VERSION ""

NS_ :

BS_:

BU_: ETH

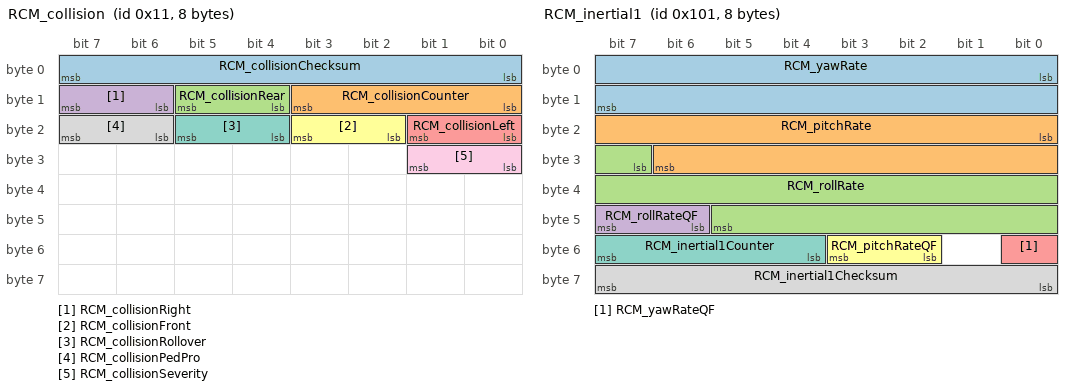
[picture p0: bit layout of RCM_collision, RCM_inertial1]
BO_ 17 RCM_collision: 8 Vector__XXX
 SG_ RCM_collisionChecksum : 0|8@1+ (1,0) [0|0] "" Vector__XXX
 SG_ RCM_collisionCounter : 8|4@1+ (1,0) [0|0] "" Vector__XXX
 SG_ RCM_collisionRear : 12|2@1+ (1,0) [0|0] "" Vector__XXX
 SG_ RCM_collisionRight : 14|2@1+ (1,0) [0|0] "" Vector__XXX
 SG_ RCM_collisionLeft : 16|2@1+ (1,0) [0|0] "" Vector__XXX
 SG_ RCM_collisionFront : 18|2@1+ (1,0) [0|0] "" Vector__XXX
 SG_ RCM_collisionRollover : 20|2@1+ (1,0) [0|0] "" Vector__XXX
 SG_ RCM_collisionPedPro : 22|2@1+ (1,0) [0|0] "" Vector__XXX
 SG_ RCM_collisionSeverity : 24|2@1+ (1,0) [0|0] "" Vector__XXX

BO_ 49 EPAS3P_status: 8 Vector__XXX
 SG_ EPAS3P_statusCrc : 0|8@1+ (1,0) [0|0] "" Vector__XXX
 SG_ EPAS3P_statusCounter : 8|4@1+ (1,0) [0|0] "" Vector__XXX
 SG_ EPAS3P_state : 12|4@1+ (1,0) [0|0] "" Vector__XXX
 SG_ EPAS3P_powerMode : 16|3@1+ (1,0) [0|0] "" Vector__XXX
 SG_ EPAS3P_role : 19|2@1+ (1,0) [0|0] "" Vector__XXX

BO_ 50 RCM_peripheralSensors1: 8 Vector__XXX
 SG_ RCM_leftFrontDoorPressure : 0|10@1- (0.48828125,0) [0|0] "" Vector__XXX
 SG_ RCM_rightFrontDoorPressure : 10|10@1- (0.48828125,0) [0|0] "" Vector__XXX
 SG_ RCM_leftRearDoorPressure : 20|10@1- (0.48828125,0) [0|0] "" Vector__XXX
 SG_ RCM_rightRearDoorPressure : 30|10@1- (0.48828125,0) [0|0] "" Vector__XXX
 SG_ RCM_peripheralSensors1Counter : 52|4@1+ (1,0) [0|0] "" Vector__XXX
 SG_ RCM_peripheralSensors1Checksum : 56|8@1+ (1,0) [0|0] "" Vector__XXX

BO_ 81 EPAS3S_status: 8 Vector__XXX
 SG_ EPAS3S_statusCrc : 0|8@1+ (1,0) [0|0] "" Vector__XXX
 SG_ EPAS3S_statusCounter : 8|4@1+ (1,0) [0|0] "" Vector__XXX
 SG_ EPAS3S_state : 12|4@1+ (1,0) [0|0] "" Vector__XXX
 SG_ EPAS3S_powerMode : 16|3@1+ (1,0) [0|0] "" Vector__XXX
 SG_ EPAS3S_role : 19|2@1+ (1,0) [0|0] "" Vector__XXX

BO_ 129 RCM_impactSummary: 8 Vector__XXX
 SG_ RCM_maxDvLateralEvent1 : 0|8@1+ (1,-127) [0|0] "" Vector__XXX
 SG_ RCM_maxDvLongitudinalEvent1 : 8|8@1+ (1,-127) [0|0] "" Vector__XXX
 SG_ RCM_impactDirectionEvent1 : 16|4@1+ (1,0) [0|0] "" Vector__XXX

BO_ 257 RCM_inertial1: 8 Vector__XXX
 SG_ RCM_yawRate : 0|16@1- (0.0001,0) [0|0] "" Vector__XXX
 SG_ RCM_pitchRate : 16|15@1- (0.00025,0) [0|0] "" Vector__XXX
 SG_ RCM_rollRate : 31|15@1- (0.00025,0) [0|0] "" Vector__XXX
 SG_ RCM_rollRateQF : 46|2@1+ (1,0) [0|0] "" Vector__XXX
 SG_ RCM_yawRateQF : 48|1@1+ (1,0) [0|0] "" Vector__XXX
 SG_ RCM_pitchRateQF : 50|2@1+ (1,0) [0|0] "" Vector__XXX
 SG_ RCM_inertial1Counter : 52|4@1+ (1,0) [0|0] "" Vector__XXX
 SG_ RCM_inertial1Checksum : 56|8@1+ (1,0) [0|0] "" Vector__XXX

BO_ 258 VCLEFT_doorStatus: 8 Vector__XXX
 SG_ VCLEFT_doorClosureStatusFront : 0|4@1+ (1,0) [0|0] "" Vector__XXX
 SG_ VCLEFT_doorClosureStatusRear : 4|4@1+ (1,0) [0|0] "" Vector__XXX
 SG_ VCLEFT_frontLatchSwitch : 8|1@1+ (1,0) [0|0] "" Vector__XXX
 SG_ VCLEFT_rearLatchSwitch : 9|1@1+ (1,0) [0|0] "" Vector__XXX
 SG_ VCLEFT_frontHandlePulled : 10|1@1+ (1,0) [0|0] "" Vector__XXX
 SG_ VCLEFT_rearHandlePulled : 11|1@1+ (1,0) [0|0] "" Vector__XXX
 SG_ VCLEFT_frontRelActuatorSwitch : 12|1@1+ (1,0) [0|0] "" Vector__XXX
 SG_ VCLEFT_rearRelActuatorSwitch : 13|1@1+ (1,0) [0|0] "" Vector__XXX
 SG_ VCLEFT_frontLatchStatus : 14|4@1+ (1,0) [0|0] "" Vector__XXX
 SG_ VCLEFT_rearLatchStatus : 18|4@1+ (1,0) [0|0] "" Vector__XXX
 SG_ VCLEFT_lastDoorReqSourceFront : 22|3@1+ (1,0) [0|0] "" Vector__XXX
 SG_ VCLEFT_lastDoorReqSourceRear : 25|3@1+ (1,0) [0|0] "" Vector__XXX
 SG_ VCLEFT_frontIntSwitchFaulted : 28|1@1+ (1,0) [0|0] "" Vector__XXX
 SG_ VCLEFT_rearIntSwitchFaulted : 29|1@1+ (1,0) [0|0] "" Vector__XXX
 SG_ VCLEFT_frontIntSwitchPressed : 31|1@1+ (1,0) [0|0] "" Vector__XXX
 SG_ VCLEFT_rearIntSwitchPressed : 32|1@1+ (1,0) [0|0] "" Vector__XXX
 SG_ VCLEFT_mirrorTiltXPosition : 33|8@1+ (0.02,0) [0|0] "" Vector__XXX
 SG_ VCLEFT_mirrorTiltYPosition : 41|8@1+ (0.02,0) [0|0] "" Vector__XXX
 SG_ VCLEFT_mirrorState : 49|3@1+ (1,0) [0|0] "" Vector__XXX
 SG_ VCLEFT_mirrorFoldState : 52|3@1+ (1,0) [0|0] "" Vector__XXX
 SG_ VCLEFT_mirrorRecallState : 55|3@1+ (1,0) [0|0] "" Vector__XXX
 SG_ VCLEFT_mirrorHeatState : 58|3@1+ (1,0) [0|0] "" Vector__XXX
 SG_ VCLEFT_rearHandlePulledPersist : 61|1@1+ (1,0) [0|0] "" Vector__XXX
 SG_ VCLEFT_frontHandlePulledPersist : 62|1@1+ (1,0) [0|0] "" Vector__XXX
 SG_ VCLEFT_mirrorDipped : 63|1@1+ (1,0) [0|0] "" Vector__XXX

BO_ 259 VCRIGHT_doorStatus: 8 Vector__XXX
 SG_ VCRIGHT_doorClosureStatusFront : 0|4@1+ (1,0) [0|0] "" Vector__XXX
 SG_ VCRIGHT_doorClosureStatusRear : 4|4@1+ (1,0) [0|0] "" Vector__XXX
 SG_ VCRIGHT_frontLatchSwitch : 8|1@1+ (1,0) [0|0] "" Vector__XXX
 SG_ VCRIGHT_rearLatchSwitch : 9|1@1+ (1,0) [0|0] "" Vector__XXX
 SG_ VCRIGHT_frontHandlePulled : 10|1@1+ (1,0) [0|0] "" Vector__XXX
 SG_ VCRIGHT_rearHandlePulled : 11|1@1+ (1,0) [0|0] "" Vector__XXX
 SG_ VCRIGHT_frontRelActuatorSwitch : 12|1@1+ (1,0) [0|0] "" Vector__XXX
 SG_ VCRIGHT_rearRelActuatorSwitch : 13|1@1+ (1,0) [0|0] "" Vector__XXX
 SG_ VCRIGHT_frontLatchStatus : 14|4@1+ (1,0) [0|0] "" Vector__XXX
 SG_ VCRIGHT_rearLatchStatus : 18|4@1+ (1,0) [0|0] "" Vector__XXX
 SG_ VCRIGHT_lastDoorReqSourceFront : 22|3@1+ (1,0) [0|0] "" Vector__XXX
 SG_ VCRIGHT_lastDoorReqSourceRear : 25|3@1+ (1,0) [0|0] "" Vector__XXX
 SG_ VCRIGHT_frontIntSwitchFaulted : 28|1@1+ (1,0) [0|0] "" Vector__XXX
 SG_ VCRIGHT_rearIntSwitchFaulted : 29|1@1+ (1,0) [0|0] "" Vector__XXX
 SG_ VCRIGHT_frontHandlePulledPersist : 30|1@1+ (1,0) [0|0] "" Vector__XXX
 SG_ VCRIGHT_frontIntSwitchPressed : 31|1@1+ (1,0) [0|0] "" Vector__XXX
 SG_ VCRIGHT_rearIntSwitchPressed : 32|1@1+ (1,0) [0|0] "" Vector__XXX
 SG_ VCRIGHT_mirrorTiltXPosition : 33|8@1+ (0.02,0) [0|0] "" Vector__XXX
 SG_ VCRIGHT_mirrorTiltYPosition : 41|8@1+ (0.02,0) [0|0] "" Vector__XXX
 SG_ VCRIGHT_mirrorState : 49|3@1+ (1,0) [0|0] "" Vector__XXX
 SG_ VCRIGHT_mirrorFoldState : 52|3@1+ (1,0) [0|0] "" Vector__XXX
 SG_ VCRIGHT_mirrorDipped : 55|1@1+ (1,0) [0|0] "" Vector__XXX
 SG_ VCRIGHT_trunkLatchStatus : 56|4@1+ (1,0) [0|0] "" Vector__XXX
 SG_ VCRIGHT_mirrorRecallState : 60|3@1+ (1,0) [0|0] "" Vector__XXX
 SG_ VCRIGHT_rearHandlePulledPersist : 63|1@1+ (1,0) [0|0] "" Vector__XXX

BO_ 260 VCFRONT_partyDebug: 8 Vector__XXX
 SG_ VCFRONT_vcleftHighPower : 0|1@1+ (1,0) [0|0] "" Vector__XXX
 SG_ VCFRONT_vcrightHighPower : 1|1@1+ (1,0) [0|0] "" Vector__XXX
 SG_ VCFRONT_uiHighPower : 2|1@1+ (1,0) [0|0] "" Vector__XXX
 SG_ VCFRONT_5VAStable : 3|1@1+ (1,0) [0|0] "" Vector__XXX
 SG_ VCFRONT_5VBStable : 4|1@1+ (1,0) [0|0] "" Vector__XXX
 SG_ VCFRONT_12VAStable : 5|1@1+ (1,0) [0|0] "" Vector__XXX
 SG_ VCFRONT_12VBStable : 6|1@1+ (1,0) [0|0] "" Vector__XXX
 SG_ VCFRONT_railA : 7|1@1+ (1,0) [0|0] "" Vector__XXX
 SG_ VCFRONT_railB : 8|1@1+ (1,0) [0|0] "" Vector__XXX
 SG_ VCFRONT_chargePumpStable : 9|1@1+ (1,0) [0|0] "" Vector__XXX
 SG_ VCFRONT_vehicleSM : 10|5@1+ (1,0) [0|0] "" Vector__XXX
 SG_ VCFRONT_revBattFault : 15|1@1+ (1,0) [0|0] "" Vector__XXX
 SG_ VCFRONT_battSM : 16|4@1+ (1,0) [0|0] "" Vector__XXX
 SG_ VCFRONT_U13Init : 20|1@1+ (1,0) [0|0] "" Vector__XXX
 SG_ VCFRONT_U16Init : 21|1@1+ (1,0) [0|0] "" Vector__XXX
 SG_ VCFRONT_anyVehLoadShedActiveDBG : 22|1@1+ (1,0) [0|0] "" Vector__XXX
 SG_ VCFRONT_battVoltage : 24|12@1+ (0.005443676098,0) [0|0] "" Vector__XXX
 SG_ VCFRONT_battCurrent : 40|16@1- (0.005,0) [0|0] "" Vector__XXX

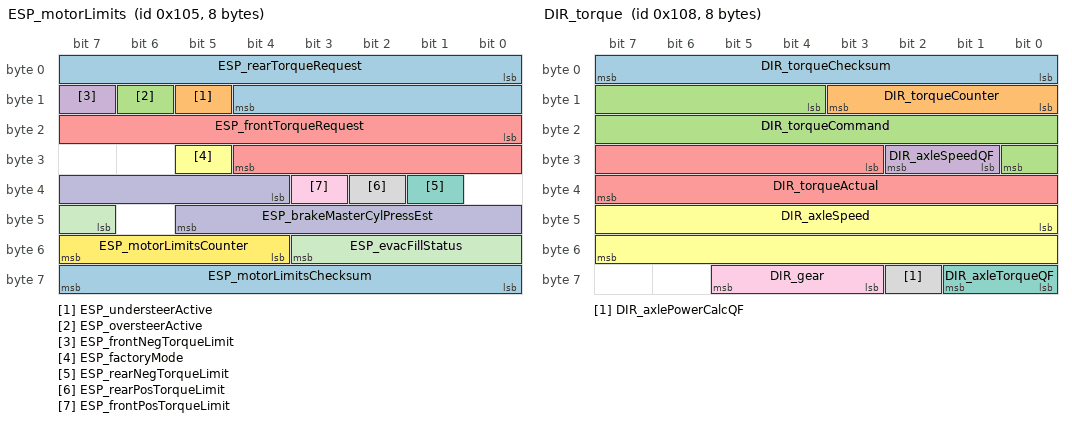
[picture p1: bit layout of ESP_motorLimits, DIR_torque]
BO_ 261 ESP_motorLimits: 8 Vector__XXX
 SG_ ESP_rearTorqueRequest : 0|13@1- (2,0) [0|0] "" Vector__XXX
 SG_ ESP_understeerActive : 13|1@1+ (1,0) [0|0] "" Vector__XXX
 SG_ ESP_oversteerActive : 14|1@1+ (1,0) [0|0] "" Vector__XXX
 SG_ ESP_frontNegTorqueLimit : 15|1@1+ (1,0) [0|0] "" Vector__XXX
 SG_ ESP_frontTorqueRequest : 16|13@1- (2,0) [0|0] "" Vector__XXX
 SG_ ESP_factoryMode : 29|1@1+ (1,0) [0|0] "" Vector__XXX
 SG_ ESP_rearNegTorqueLimit : 33|1@1+ (1,0) [0|0] "" Vector__XXX
 SG_ ESP_rearPosTorqueLimit : 34|1@1+ (1,0) [0|0] "" Vector__XXX
 SG_ ESP_frontPosTorqueLimit : 35|1@1+ (1,0) [0|0] "" Vector__XXX
 SG_ ESP_brakeMasterCylPressEst : 36|10@1+ (0.3,-30) [0|0] "" Vector__XXX
 SG_ ESP_evacFillStatus : 47|5@1+ (1,0) [0|0] "" Vector__XXX
 SG_ ESP_motorLimitsCounter : 52|4@1+ (1,0) [0|0] "" Vector__XXX
 SG_ ESP_motorLimitsChecksum : 56|8@1+ (1,0) [0|0] "" Vector__XXX

BO_ 264 DIR_torque: 8 Vector__XXX
 SG_ DIR_torqueChecksum : 0|8@1+ (1,0) [0|0] "" Vector__XXX
 SG_ DIR_torqueCounter : 8|4@1+ (1,0) [0|0] "" Vector__XXX
 SG_ DIR_torqueCommand : 12|13@1- (2,0) [0|0] "" Vector__XXX
 SG_ DIR_axleSpeedQF : 25|2@1+ (1,0) [0|0] "" Vector__XXX
 SG_ DIR_torqueActual : 27|13@1- (2,0) [0|0] "" Vector__XXX
 SG_ DIR_axleSpeed : 40|16@1- (0.1,0) [0|0] "" Vector__XXX
 SG_ DIR_axleTorqueQF : 56|2@1+ (1,0) [0|0] "" Vector__XXX
 SG_ DIR_axlePowerCalcQF : 58|1@1+ (1,0) [0|0] "" Vector__XXX
 SG_ DIR_gear : 59|3@1+ (1,0) [0|0] "" Vector__XXX

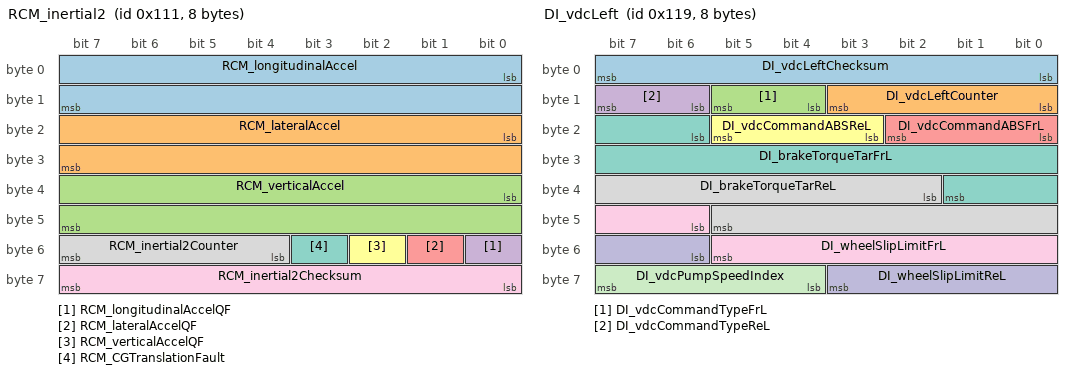
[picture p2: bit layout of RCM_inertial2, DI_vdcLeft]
BO_ 273 RCM_inertial2: 8 Vector__XXX
 SG_ RCM_longitudinalAccel : 0|16@1- (0.00125,0) [0|0] "" Vector__XXX
 SG_ RCM_lateralAccel : 16|16@1- (0.00125,0) [0|0] "" Vector__XXX
 SG_ RCM_verticalAccel : 32|16@1- (0.00125,0) [0|0] "" Vector__XXX
 SG_ RCM_longitudinalAccelQF : 48|1@1+ (1,0) [0|0] "" Vector__XXX
 SG_ RCM_lateralAccelQF : 49|1@1+ (1,0) [0|0] "" Vector__XXX
 SG_ RCM_verticalAccelQF : 50|1@1+ (1,0) [0|0] "" Vector__XXX
 SG_ RCM_CGTranslationFault : 51|1@1+ (1,0) [0|0] "" Vector__XXX
 SG_ RCM_inertial2Counter : 52|4@1+ (1,0) [0|0] "" Vector__XXX
 SG_ RCM_inertial2Checksum : 56|8@1+ (1,0) [0|0] "" Vector__XXX

BO_ 280 DI_systemStatus: 8 Vector__XXX
 SG_ DI_systemStatusChecksum : 0|8@1+ (1,0) [0|0] "" Vector__XXX
 SG_ DI_systemStatusCounter : 8|4@1+ (1,0) [0|0] "" Vector__XXX
 SG_ DI_immobilizerState : 13|3@1+ (1,0) [0|0] "" Vector__XXX
 SG_ DI_systemState : 16|3@1+ (1,0) [0|0] "" Vector__XXX
 SG_ DI_brakePedalState : 19|2@1+ (1,0) [0|0] "" Vector__XXX
 SG_ DI_gear : 21|3@1+ (1,0) [0|0] "" Vector__XXX
 SG_ DI_driveBlocked : 24|3@1+ (1,0) [0|0] "" Vector__XXX
 SG_ DI_hvilSystemStatus : 27|2@1+ (1,0) [0|0] "" Vector__XXX
 SG_ DI_accelPedalPos : 32|8@1+ (0.4,0) [0|0] "" Vector__XXX
 SG_ DI_tractionControlMode : 40|3@1+ (1,0) [0|0] "" Vector__XXX
 SG_ DI_dynoModeAvailable : 43|1@1+ (1,0) [0|0] "" Vector__XXX
 SG_ DI_epbRequest : 44|2@1+ (1,0) [0|0] "" Vector__XXX
 SG_ DI_eepDeliveryBitStatus : 46|1@1+ (1,0) [0|0] "" Vector__XXX
 SG_ DI_keepDrivePowerStateRequest : 47|1@1+ (1,0) [0|0] "" Vector__XXX
 SG_ DI_trackModeState : 48|2@1+ (1,0) [0|0] "" Vector__XXX
 SG_ DI_manualDrivingProhibited : 50|1@1+ (1,0) [0|0] "" Vector__XXX
 SG_ DI_regenLight : 51|1@1+ (1,0) [0|0] "" Vector__XXX
 SG_ DI_vehicleAcceleration : 52|12@1- (0.01,0) [0|0] "" Vector__XXX

BO_ 281 DI_vdcLeft: 8 Vector__XXX
 SG_ DI_vdcLeftChecksum : 0|8@1+ (1,0) [0|0] "" Vector__XXX
 SG_ DI_vdcLeftCounter : 8|4@1+ (1,0) [0|0] "" Vector__XXX
 SG_ DI_vdcCommandTypeFrL : 12|2@1+ (1,0) [0|0] "" Vector__XXX
 SG_ DI_vdcCommandTypeReL : 14|2@1+ (1,0) [0|0] "" Vector__XXX
 SG_ DI_vdcCommandABSFrL : 16|3@1+ (1,0) [0|0] "" Vector__XXX
 SG_ DI_vdcCommandABSReL : 19|3@1+ (1,0) [0|0] "" Vector__XXX
 SG_ DI_brakeTorqueTarFrL : 22|12@1+ (3,-3) [0|0] "" Vector__XXX
 SG_ DI_brakeTorqueTarReL : 34|12@1+ (3,-3) [0|0] "" Vector__XXX
 SG_ DI_wheelSlipLimitFrL : 46|8@1+ (0.004,-0.004) [0|0] "" Vector__XXX
 SG_ DI_wheelSlipLimitReL : 54|6@1+ (0.004,-0.004) [0|0] "" Vector__XXX
 SG_ DI_vdcPumpSpeedIndex : 60|4@1+ (1,0) [0|0] "" Vector__XXX

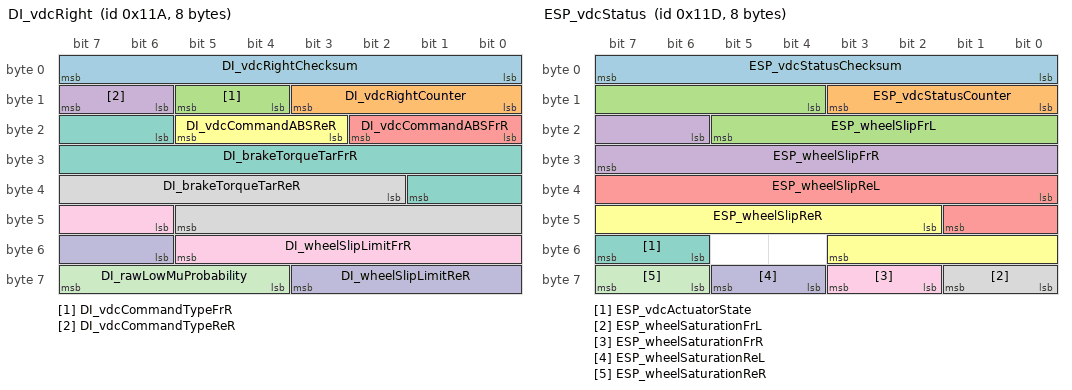
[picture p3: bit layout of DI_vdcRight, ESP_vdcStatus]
BO_ 282 DI_vdcRight: 8 Vector__XXX
 SG_ DI_vdcRightChecksum : 0|8@1+ (1,0) [0|0] "" Vector__XXX
 SG_ DI_vdcRightCounter : 8|4@1+ (1,0) [0|0] "" Vector__XXX
 SG_ DI_vdcCommandTypeFrR : 12|2@1+ (1,0) [0|0] "" Vector__XXX
 SG_ DI_vdcCommandTypeReR : 14|2@1+ (1,0) [0|0] "" Vector__XXX
 SG_ DI_vdcCommandABSFrR : 16|3@1+ (1,0) [0|0] "" Vector__XXX
 SG_ DI_vdcCommandABSReR : 19|3@1+ (1,0) [0|0] "" Vector__XXX
 SG_ DI_brakeTorqueTarFrR : 22|12@1+ (3,-3) [0|0] "" Vector__XXX
 SG_ DI_brakeTorqueTarReR : 34|12@1+ (3,-3) [0|0] "" Vector__XXX
 SG_ DI_wheelSlipLimitFrR : 46|8@1+ (0.004,-0.004) [0|0] "" Vector__XXX
 SG_ DI_wheelSlipLimitReR : 54|6@1+ (0.004,-0.004) [0|0] "" Vector__XXX
 SG_ DI_rawLowMuProbability : 60|4@1+ (0.06666666666666667,0) [0|0] "" Vector__XXX

BO_ 283 DAS_matrixBendAngleRequest: 8 Vector__XXX
 SG_ DAS_adaptiveBendAngle : 0|8@1- (0.1,0) [0|0] "" Vector__XXX

BO_ 285 ESP_vdcStatus: 8 Vector__XXX
 SG_ ESP_vdcStatusChecksum : 0|8@1+ (1,0) [0|0] "" Vector__XXX
 SG_ ESP_vdcStatusCounter : 8|4@1+ (1,0) [0|0] "" Vector__XXX
 SG_ ESP_wheelSlipFrL : 12|10@1+ (0.001,0) [0|0] "" Vector__XXX
 SG_ ESP_wheelSlipFrR : 22|10@1+ (0.001,0) [0|0] "" Vector__XXX
 SG_ ESP_wheelSlipReL : 32|10@1+ (0.001,0) [0|0] "" Vector__XXX
 SG_ ESP_wheelSlipReR : 42|10@1+ (0.001,0) [0|0] "" Vector__XXX
 SG_ ESP_vdcActuatorState : 54|2@1+ (1,0) [0|0] "" Vector__XXX
 SG_ ESP_wheelSaturationFrL : 56|2@1+ (1,0) [0|0] "" Vector__XXX
 SG_ ESP_wheelSaturationFrR : 58|2@1+ (1,0) [0|0] "" Vector__XXX
 SG_ ESP_wheelSaturationReL : 60|2@1+ (1,0) [0|0] "" Vector__XXX
 SG_ ESP_wheelSaturationReR : 62|2@1+ (1,0) [0|0] "" Vector__XXX

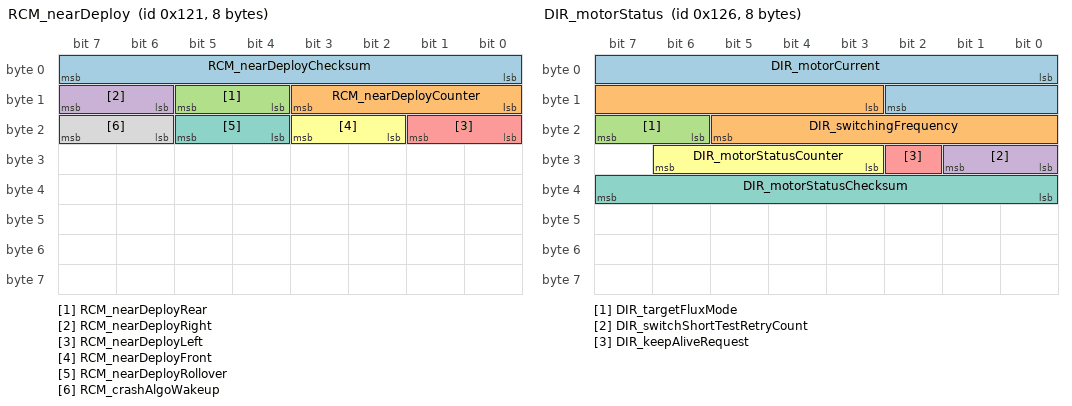
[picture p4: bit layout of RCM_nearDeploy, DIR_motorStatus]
BO_ 289 RCM_nearDeploy: 8 Vector__XXX
 SG_ RCM_nearDeployChecksum : 0|8@1+ (1,0) [0|0] "" Vector__XXX
 SG_ RCM_nearDeployCounter : 8|4@1+ (1,0) [0|0] "" Vector__XXX
 SG_ RCM_nearDeployRear : 12|2@1+ (1,0) [0|0] "" Vector__XXX
 SG_ RCM_nearDeployRight : 14|2@1+ (1,0) [0|0] "" Vector__XXX
 SG_ RCM_nearDeployLeft : 16|2@1+ (1,0) [0|0] "" Vector__XXX
 SG_ RCM_nearDeployFront : 18|2@1+ (1,0) [0|0] "" Vector__XXX
 SG_ RCM_nearDeployRollover : 20|2@1+ (1,0) [0|0] "" Vector__XXX
 SG_ RCM_crashAlgoWakeup : 22|2@1+ (1,0) [0|0] "" Vector__XXX

BO_ 294 DIR_motorStatus: 8 Vector__XXX
 SG_ DIR_motorCurrent : 0|11@1+ (1,0) [0|0] "" Vector__XXX
 SG_ DIR_switchingFrequency : 11|11@1+ (0.01,0) [0|0] "" Vector__XXX
 SG_ DIR_targetFluxMode : 22|2@1+ (1,0) [0|0] "" Vector__XXX
 SG_ DIR_switchShortTestRetryCount : 24|2@1+ (1,0) [0|0] "" Vector__XXX
 SG_ DIR_keepAliveRequest : 26|1@1+ (1,0) [0|0] "" Vector__XXX
 SG_ DIR_motorStatusCounter : 27|4@1+ (1,0) [0|0] "" Vector__XXX
 SG_ DIR_motorStatusChecksum : 32|8@1+ (1,0) [0|0] "" Vector__XXX

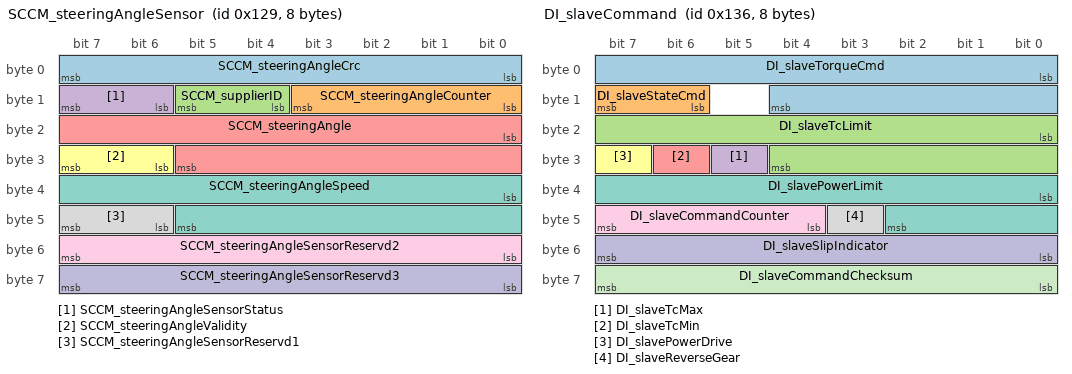
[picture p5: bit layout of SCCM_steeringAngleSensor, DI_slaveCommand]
BO_ 297 SCCM_steeringAngleSensor: 8 Vector__XXX
 SG_ SCCM_steeringAngleCrc : 0|8@1+ (1,0) [0|0] "" Vector__XXX
 SG_ SCCM_steeringAngleCounter : 8|4@1+ (1,0) [0|0] "" Vector__XXX
 SG_ SCCM_supplierID : 12|2@1+ (1,0) [0|0] "" Vector__XXX
 SG_ SCCM_steeringAngleSensorStatus : 14|2@1+ (1,0) [0|0] "" Vector__XXX
 SG_ SCCM_steeringAngle : 16|14@1+ (0.1,-819.2) [0|0] "" Vector__XXX
 SG_ SCCM_steeringAngleValidity : 30|2@1+ (1,0) [0|0] "" Vector__XXX
 SG_ SCCM_steeringAngleSpeed : 32|14@1+ (0.5,-4096) [0|0] "" Vector__XXX
 SG_ SCCM_steeringAngleSensorReservd1 : 46|2@1+ (1,0) [0|0] "" Vector__XXX
 SG_ SCCM_steeringAngleSensorReservd2 : 48|8@1+ (1,0) [0|0] "" Vector__XXX
 SG_ SCCM_steeringAngleSensorReservd3 : 56|8@1+ (1,0) [0|0] "" Vector__XXX

BO_ 310 DI_slaveCommand: 8 Vector__XXX
 SG_ DI_slaveTorqueCmd : 0|13@1- (2,0) [0|0] "" Vector__XXX
 SG_ DI_slaveStateCmd : 14|2@1+ (1,0) [0|0] "" Vector__XXX
 SG_ DI_slaveTcLimit : 16|13@1- (2,0) [0|0] "" Vector__XXX
 SG_ DI_slaveTcMax : 29|1@1+ (1,0) [0|0] "" Vector__XXX
 SG_ DI_slaveTcMin : 30|1@1+ (1,0) [0|0] "" Vector__XXX
 SG_ DI_slavePowerDrive : 31|1@1+ (1,0) [0|0] "" Vector__XXX
 SG_ DI_slavePowerLimit : 32|11@1+ (0.25,0) [0|0] "" Vector__XXX
 SG_ DI_slaveReverseGear : 43|1@1+ (1,0) [0|0] "" Vector__XXX
 SG_ DI_slaveCommandCounter : 44|4@1+ (1,0) [0|0] "" Vector__XXX
 SG_ DI_slaveSlipIndicator : 48|8@1+ (1,0) [0|0] "" Vector__XXX
 SG_ DI_slaveCommandChecksum : 56|8@1+ (1,0) [0|0] "" Vector__XXX

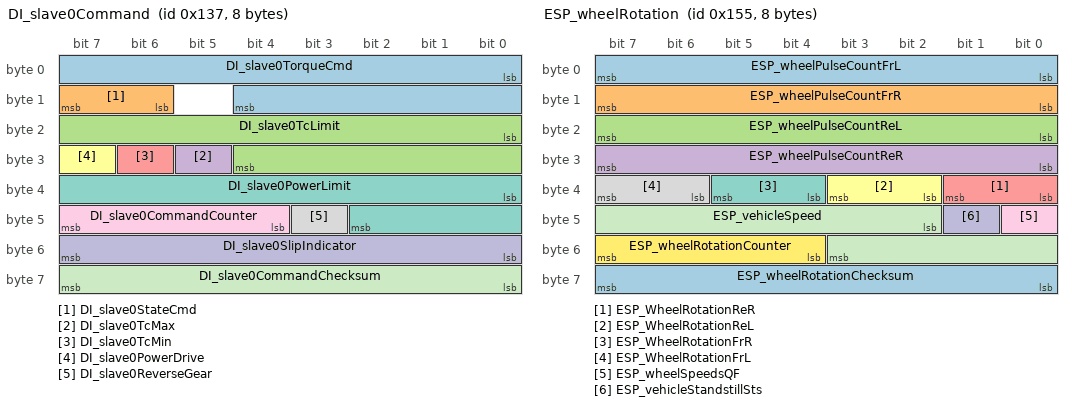
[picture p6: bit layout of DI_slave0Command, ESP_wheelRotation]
BO_ 311 DI_slave0Command: 8 Vector__XXX
 SG_ DI_slave0TorqueCmd : 0|13@1- (2,0) [0|0] "" Vector__XXX
 SG_ DI_slave0StateCmd : 14|2@1+ (1,0) [0|0] "" Vector__XXX
 SG_ DI_slave0TcLimit : 16|13@1- (2,0) [0|0] "" Vector__XXX
 SG_ DI_slave0TcMax : 29|1@1+ (1,0) [0|0] "" Vector__XXX
 SG_ DI_slave0TcMin : 30|1@1+ (1,0) [0|0] "" Vector__XXX
 SG_ DI_slave0PowerDrive : 31|1@1+ (1,0) [0|0] "" Vector__XXX
 SG_ DI_slave0PowerLimit : 32|11@1+ (0.25,0) [0|0] "" Vector__XXX
 SG_ DI_slave0ReverseGear : 43|1@1+ (1,0) [0|0] "" Vector__XXX
 SG_ DI_slave0CommandCounter : 44|4@1+ (1,0) [0|0] "" Vector__XXX
 SG_ DI_slave0SlipIndicator : 48|8@1+ (1,0) [0|0] "" Vector__XXX
 SG_ DI_slave0CommandChecksum : 56|8@1+ (1,0) [0|0] "" Vector__XXX

BO_ 322 DI_slaveCommand2: 8 Vector__XXX
 SG_ DI_slaveCommand2Checksum : 0|8@1+ (1,0) [0|0] "" Vector__XXX
 SG_ DI_slaveCommand2Counter : 8|4@1+ (1,0) [0|0] "" Vector__XXX
 SG_ DI_slaveAddLimit : 16|13@1- (1,0) [0|0] "" Vector__XXX
 SG_ DI_slaveAddMax : 29|1@1+ (1,0) [0|0] "" Vector__XXX
 SG_ DI_slaveAddMin : 30|1@1+ (1,0) [0|0] "" Vector__XXX
 SG_ DI_slaveExcessHeatCmd : 32|8@1+ (0.08,0) [0|0] "" Vector__XXX

BO_ 323 DI_slave0Command2: 8 Vector__XXX
 SG_ DI_slave0Command2Checksum : 0|8@1+ (1,0) [0|0] "" Vector__XXX
 SG_ DI_slave0Command2Counter : 8|4@1+ (1,0) [0|0] "" Vector__XXX
 SG_ DI_slave0AddLimit : 16|13@1- (1,0) [0|0] "" Vector__XXX
 SG_ DI_slave0AddMax : 29|1@1+ (1,0) [0|0] "" Vector__XXX
 SG_ DI_slave0AddMin : 30|1@1+ (1,0) [0|0] "" Vector__XXX
 SG_ DI_slave0ExcessHeatCmd : 32|8@1+ (0.08,0) [0|0] "" Vector__XXX

BO_ 325 ESP_status: 8 Vector__XXX
 SG_ ESP_statusChecksum : 0|8@1+ (1,0) [0|0] "" Vector__XXX
 SG_ ESP_statusCounter : 8|4@1+ (1,0) [0|0] "" Vector__XXX
 SG_ ESP_espModeActive : 12|2@1+ (1,0) [0|0] "" Vector__XXX
 SG_ ESP_stabilityControlSts2 : 14|2@1+ (1,0) [0|0] "" Vector__XXX
 SG_ ESP_ebdFaultLamp : 16|1@1+ (1,0) [0|0] "" Vector__XXX
 SG_ ESP_absFaultLamp : 17|1@1+ (1,0) [0|0] "" Vector__XXX
 SG_ ESP_espFaultLamp : 18|1@1+ (1,0) [0|0] "" Vector__XXX
 SG_ ESP_hydraulicBoostEnabled : 19|1@1+ (1,0) [0|0] "" Vector__XXX
 SG_ ESP_espLampFlash : 20|1@1+ (1,0) [0|0] "" Vector__XXX
 SG_ ESP_brakeLamp : 21|1@1+ (1,0) [0|0] "" Vector__XXX
 SG_ ESP_absBrakeEvent2 : 22|2@1+ (1,0) [0|0] "" Vector__XXX
 SG_ ESP_longitudinalAccelQF : 24|1@1+ (1,0) [0|0] "" Vector__XXX
 SG_ ESP_lateralAccelQF : 25|1@1+ (1,0) [0|0] "" Vector__XXX
 SG_ ESP_yawRateQF : 26|1@1+ (1,0) [0|0] "" Vector__XXX
 SG_ ESP_steeringAngleQF : 27|1@1+ (1,0) [0|0] "" Vector__XXX
 SG_ ESP_brakeDiscWipingActive : 28|1@1+ (1,0) [0|0] "" Vector__XXX
 SG_ ESP_driverBrakeApply : 29|2@1+ (1,0) [0|0] "" Vector__XXX
 SG_ ESP_brakeApply : 31|1@1+ (1,0) [0|0] "" Vector__XXX
 SG_ ESP_aesPrimaryActuatorStatus : 32|2@1+ (1,0) [0|0] "" Vector__XXX
 SG_ ESP_cdpStatus : 34|2@1+ (1,0) [0|0] "" Vector__XXX
 SG_ ESP_ptcTargetState : 36|2@1+ (1,0) [0|0] "" Vector__XXX
 SG_ ESP_btcTargetState : 38|2@1+ (1,0) [0|0] "" Vector__XXX
 SG_ ESP_ebrStandstillSkid : 48|1@1+ (1,0) [0|0] "" Vector__XXX
 SG_ ESP_ebrStatus : 49|2@1+ (1,0) [0|0] "" Vector__XXX
 SG_ ESP_brakeTorqueTarget : 51|13@1+ (3,0) [0|0] "" Vector__XXX

BO_ 328 DI_chassisControl: 8 Vector__XXX
 SG_ DI_chassisControlChecksum : 0|8@1+ (1,0) [0|0] "" Vector__XXX
 SG_ DI_chassisControlCounter : 8|4@1+ (1,0) [0|0] "" Vector__XXX
 SG_ DI_imuOffsetLearnRequest : 12|2@1+ (1,0) [0|0] "" Vector__XXX
 SG_ DI_brakeCommandType : 14|1@1+ (1,0) [0|0] "" Vector__XXX
 SG_ DI_brakeTorqueRequestActive : 15|1@1+ (1,0) [0|0] "" Vector__XXX
 SG_ DI_brakeTorqueCommand : 16|13@1+ (3,0) [0|0] "" Vector__XXX
 SG_ DI_ptcStateGlobal : 29|2@1+ (1,0) [0|0] "" Vector__XXX
 SG_ DI_ptcActive : 31|1@1+ (1,0) [0|0] "" Vector__XXX
 SG_ DI_vdcState : 32|2@1+ (1,0) [0|0] "" Vector__XXX
 SG_ DI_isAnyVdcControlActive : 34|2@1+ (1,0) [0|0] "" Vector__XXX
 SG_ DI_vdcMode : 36|2@1+ (1,0) [0|0] "" Vector__XXX
 SG_ DI_pedalAssistCurveSelect : 38|4@1+ (1,0) [0|0] "" Vector__XXX
 SG_ DI_isAnyTcActive : 42|1@1+ (1,0) [0|0] "" Vector__XXX
 SG_ DI_VehicleMuConfidence : 43|6@1+ (0.02,0) [0|0] "" Vector__XXX
 SG_ DI_VehicleMu : 49|6@1+ (0.024,0) [0|0] "" Vector__XXX
 SG_ DI_trailerSwayIndex : 55|5@1+ (0.035,0) [0|0] "" Vector__XXX
 SG_ DI_vdcControlActive : 60|3@1+ (1,0) [0|0] "" Vector__XXX
 SG_ DI_treadDepthAlertSet : 63|1@1+ (1,0) [0|0] "" Vector__XXX

BO_ 341 ESP_wheelRotation: 8 Vector__XXX
 SG_ ESP_wheelPulseCountFrL : 0|8@1+ (1,0) [0|0] "" Vector__XXX
 SG_ ESP_wheelPulseCountFrR : 8|8@1+ (1,0) [0|0] "" Vector__XXX
 SG_ ESP_wheelPulseCountReL : 16|8@1+ (1,0) [0|0] "" Vector__XXX
 SG_ ESP_wheelPulseCountReR : 24|8@1+ (1,0) [0|0] "" Vector__XXX
 SG_ ESP_WheelRotationReR : 32|2@1+ (1,0) [0|0] "" Vector__XXX
 SG_ ESP_WheelRotationReL : 34|2@1+ (1,0) [0|0] "" Vector__XXX
 SG_ ESP_WheelRotationFrR : 36|2@1+ (1,0) [0|0] "" Vector__XXX
 SG_ ESP_WheelRotationFrL : 38|2@1+ (1,0) [0|0] "" Vector__XXX
 SG_ ESP_wheelSpeedsQF : 40|1@1+ (1,0) [0|0] "" Vector__XXX
 SG_ ESP_vehicleStandstillSts : 41|1@1+ (1,0) [0|0] "" Vector__XXX
 SG_ ESP_vehicleSpeed : 42|10@1+ (0.5,0) [0|0] "" Vector__XXX
 SG_ ESP_wheelRotationCounter : 52|4@1+ (1,0) [0|0] "" Vector__XXX
 SG_ ESP_wheelRotationChecksum : 56|8@1+ (1,0) [0|0] "" Vector__XXX

BO_ 373 ESP_wheelSpeeds: 8 Vector__XXX
 SG_ ESP_wheelSpeedFrL : 0|13@1+ (0.042,0) [0|0] "" Vector__XXX
 SG_ ESP_wheelSpeedFrR : 13|13@1+ (0.042,0) [0|0] "" Vector__XXX
 SG_ ESP_wheelSpeedReL : 26|13@1+ (0.042,0) [0|0] "" Vector__XXX
 SG_ ESP_wheelSpeedReR : 39|13@1+ (0.042,0) [0|0] "" Vector__XXX
 SG_ ESP_wheelSpeedsCounter : 52|4@1+ (1,0) [0|0] "" Vector__XXX
 SG_ ESP_wheelSpeedsChecksum : 56|8@1+ (1,0) [0|0] "" Vector__XXX

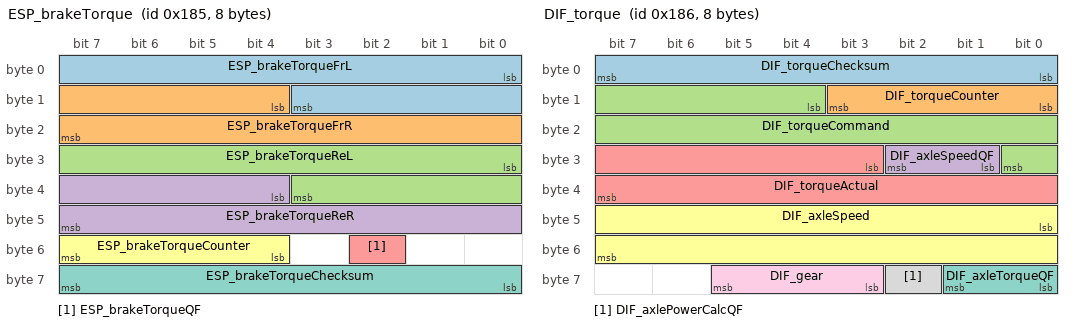
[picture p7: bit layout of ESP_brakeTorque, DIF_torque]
BO_ 389 ESP_brakeTorque: 8 Vector__XXX
 SG_ ESP_brakeTorqueFrL : 0|12@1+ (3,0) [0|0] "" Vector__XXX
 SG_ ESP_brakeTorqueFrR : 12|12@1+ (3,0) [0|0] "" Vector__XXX
 SG_ ESP_brakeTorqueReL : 24|12@1+ (3,0) [0|0] "" Vector__XXX
 SG_ ESP_brakeTorqueReR : 36|12@1+ (3,0) [0|0] "" Vector__XXX
 SG_ ESP_brakeTorqueQF : 50|1@1+ (1,0) [0|0] "" Vector__XXX
 SG_ ESP_brakeTorqueCounter : 52|4@1+ (1,0) [0|0] "" Vector__XXX
 SG_ ESP_brakeTorqueChecksum : 56|8@1+ (1,0) [0|0] "" Vector__XXX

BO_ 390 DIF_torque: 8 Vector__XXX
 SG_ DIF_torqueChecksum : 0|8@1+ (1,0) [0|0] "" Vector__XXX
 SG_ DIF_torqueCounter : 8|4@1+ (1,0) [0|0] "" Vector__XXX
 SG_ DIF_torqueCommand : 12|13@1- (2,0) [0|0] "" Vector__XXX
 SG_ DIF_axleSpeedQF : 25|2@1+ (1,0) [0|0] "" Vector__XXX
 SG_ DIF_torqueActual : 27|13@1- (2,0) [0|0] "" Vector__XXX
 SG_ DIF_axleSpeed : 40|16@1- (0.1,0) [0|0] "" Vector__XXX
 SG_ DIF_axleTorqueQF : 56|2@1+ (1,0) [0|0] "" Vector__XXX
 SG_ DIF_axlePowerCalcQF : 58|1@1+ (1,0) [0|0] "" Vector__XXX
 SG_ DIF_gear : 59|3@1+ (1,0) [0|0] "" Vector__XXX

BO_ 391 DIF_capability: 8 Vector__XXX
 SG_ DIF_capabilityChecksum : 0|8@1+ (1,0) [0|0] "" Vector__XXX
 SG_ DIF_capabilityCounter : 8|4@1+ (1,0) [0|0] "" Vector__XXX
 SG_ DIF_torquePedalMin : 12|12@1+ (2,-7500) [0|0] "" Vector__XXX
 SG_ DIF_torquePedalMax : 24|12@1+ (2,0) [0|0] "" Vector__XXX
 SG_ DIF_torquePostPedalMin : 36|12@1+ (2,-7500) [0|0] "" Vector__XXX
 SG_ DIF_torquePostPedalMax : 48|12@1+ (2,0) [0|0] "" Vector__XXX

BO_ 394 DIR_capability: 8 Vector__XXX
 SG_ DIR_capabilityChecksum : 0|8@1+ (1,0) [0|0] "" Vector__XXX
 SG_ DIR_capabilityCounter : 8|4@1+ (1,0) [0|0] "" Vector__XXX
 SG_ DIR_torquePedalMin : 12|12@1+ (2,-7500) [0|0] "" Vector__XXX
 SG_ DIR_torquePedalMax : 24|12@1+ (2,0) [0|0] "" Vector__XXX
 SG_ DIR_torquePostPedalMin : 36|12@1+ (2,-7500) [0|0] "" Vector__XXX
 SG_ DIR_torquePostPedalMax : 48|12@1+ (2,0) [0|0] "" Vector__XXX

BO_ 421 DIF_motorStatus: 8 Vector__XXX
 SG_ DIF_motorCurrent : 0|11@1+ (1,0) [0|0] "" Vector__XXX
 SG_ DIF_switchingFrequency : 11|11@1+ (0.01,0) [0|0] "" Vector__XXX
 SG_ DIF_targetFluxMode : 22|2@1+ (1,0) [0|0] "" Vector__XXX
 SG_ DIF_switchShortTestRetryCount : 24|2@1+ (1,0) [0|0] "" Vector__XXX
 SG_ DIF_keepAliveRequest : 26|1@1+ (1,0) [0|0] "" Vector__XXX
 SG_ DIF_motorStatusCounter : 27|4@1+ (1,0) [0|0] "" Vector__XXX
 SG_ DIF_motorStatusChecksum : 32|8@1+ (1,0) [0|0] "" Vector__XXX

BO_ 463 PM_systemState: 8 Vector__XXX
 SG_ PM_torqueCheckState : 0|3@1+ (1,0) [0|0] "" Vector__XXX
 SG_ PM_limpRequest : 3|2@1+ (1,0) [0|0] "" Vector__XXX
 SG_ PM_torqueCommand : 8|13@1- (2,0) [0|0] "" Vector__XXX
 SG_ PM_torqueState : 21|2@1+ (1,0) [0|0] "" Vector__XXX
 SG_ PM_systemStateCounter : 53|3@1+ (1,0) [0|0] "" Vector__XXX
 SG_ PM_systemStateChecksum : 56|8@1+ (1,0) [0|0] "" Vector__XXX

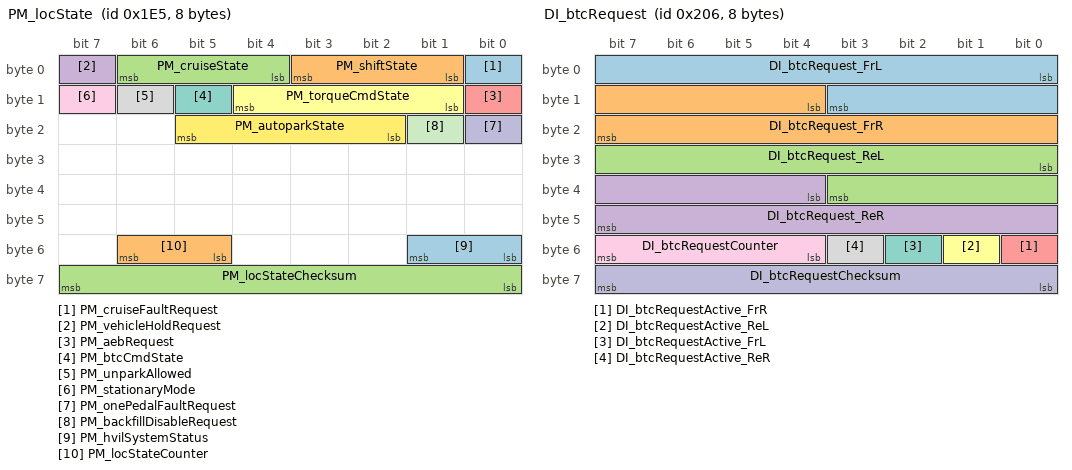
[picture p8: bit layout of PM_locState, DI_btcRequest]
BO_ 485 PM_locState: 8 Vector__XXX
 SG_ PM_cruiseFaultRequest : 0|1@1+ (1,0) [0|0] "" Vector__XXX
 SG_ PM_shiftState : 1|3@1+ (1,0) [0|0] "" Vector__XXX
 SG_ PM_cruiseState : 4|3@1+ (1,0) [0|0] "" Vector__XXX
 SG_ PM_vehicleHoldRequest : 7|1@1+ (1,0) [0|0] "" Vector__XXX
 SG_ PM_aebRequest : 8|1@1+ (1,0) [0|0] "" Vector__XXX
 SG_ PM_torqueCmdState : 9|4@1+ (1,0) [0|0] "" Vector__XXX
 SG_ PM_btcCmdState : 13|1@1+ (1,0) [0|0] "" Vector__XXX
 SG_ PM_unparkAllowed : 14|1@1+ (1,0) [0|0] "" Vector__XXX
 SG_ PM_stationaryMode : 15|1@1+ (1,0) [0|0] "" Vector__XXX
 SG_ PM_onePedalFaultRequest : 16|1@1+ (1,0) [0|0] "" Vector__XXX
 SG_ PM_backfillDisableRequest : 17|1@1+ (1,0) [0|0] "" Vector__XXX
 SG_ PM_autoparkState : 18|4@1+ (1,0) [0|0] "" Vector__XXX
 SG_ PM_hvilSystemStatus : 48|2@1+ (1,0) [0|0] "" Vector__XXX
 SG_ PM_locStateCounter : 53|2@1+ (1,0) [0|0] "" Vector__XXX
 SG_ PM_locStateChecksum : 56|8@1+ (1,0) [0|0] "" Vector__XXX

BO_ 518 DI_btcRequest: 8 Vector__XXX
 SG_ DI_btcRequest_FrL : 0|12@1+ (2,0) [0|0] "" Vector__XXX
 SG_ DI_btcRequest_FrR : 12|12@1+ (2,0) [0|0] "" Vector__XXX
 SG_ DI_btcRequest_ReL : 24|12@1+ (2,0) [0|0] "" Vector__XXX
 SG_ DI_btcRequest_ReR : 36|12@1+ (2,0) [0|0] "" Vector__XXX
 SG_ DI_btcRequestActive_FrR : 48|1@1+ (1,0) [0|0] "" Vector__XXX
 SG_ DI_btcRequestActive_ReL : 49|1@1+ (1,0) [0|0] "" Vector__XXX
 SG_ DI_btcRequestActive_FrL : 50|1@1+ (1,0) [0|0] "" Vector__XXX
 SG_ DI_btcRequestActive_ReR : 51|1@1+ (1,0) [0|0] "" Vector__XXX
 SG_ DI_btcRequestCounter : 52|4@1+ (1,0) [0|0] "" Vector__XXX
 SG_ DI_btcRequestChecksum : 56|8@1+ (1,0) [0|0] "" Vector__XXX

BO_ 521 DAS_longControl: 8 Vector__XXX
 SG_ DAS_longControlChecksum : 0|8@1+ (1,0) [0|0] "" Vector__XXX
 SG_ DAS_longControlCounter : 8|3@1+ (1,0) [0|0] "" Vector__XXX
 SG_ DAS_gearRequest : 11|2@1+ (1,0) [0|0] "" Vector__XXX
 SG_ DAS_velocityProfile_accelFwd_t0 m3 : 13|11@1- (0.012,-0.216) [0|0] "" Vector__XXX
 SG_ DAS_torqueProfiler_accelMinPed m2 : 14|9@1+ (0.04,-15) [0|0] "" Vector__XXX
 SG_ DAS_aebControl_active m4 : 16|2@1+ (1,0) [0|0] "" Vector__XXX
 SG_ DAS_pedalControl_accelPedalPos m5 : 16|12@1+ (0.025,0) [0|0] "" Vector__XXX
 SG_ DAS_torqueControl_sysTorqueCommandFwd m6 : 16|15@1- (2,0) [0|0] "" Vector__XXX
 SG_ DAS_aebControl_targetAccelDis m4 : 18|11@1- (0.01,-7.5) [0|0] "" Vector__XXX
 SG_ DAS_torqueProfiler_accelMaxPed m2 : 23|9@1+ (0.04,-15) [0|0] "" Vector__XXX
 SG_ DAS_velocityProfile_jerkFwd_t0t1 m3 : 24|8@1- (0.12,0) [0|0] "" Vector__XXX
 SG_ DAS_pedalControl_brakeTorqueCommand m5 : 32|13@1+ (3.5,0) [0|0] "" Vector__XXX
 SG_ DAS_torqueControl_standstillRequest m6 : 32|1@1+ (1,0) [0|0] "" Vector__XXX
 SG_ DAS_torqueProfiler_targetSpeedPed m2 : 32|12@1+ (0.1,0) [0|0] "" Vector__XXX
 SG_ DAS_velocityProfile_futureTargetSpeedFwd m3 : 32|12@1- (0.08,80.08) [0|0] "" Vector__XXX
 SG_ DAS_torqueProfiler_jerkMinPed m2 : 44|9@1+ (0.03,-15.232) [0|0] "" Vector__XXX
 SG_ DAS_velocityProfile_jerkFwd_t1t2 m3 : 44|8@1- (0.12,0) [0|0] "" Vector__XXX
 SG_ DAS_velocityProfile_maxAllowedTargetErrorReg m3 : 52|6@1- (0.1,1.1) [0|0] "" Vector__XXX
 SG_ DAS_torqueProfiler_jerkMaxPed m2 : 53|8@1+ (0.059,0) [0|0] "" Vector__XXX
 SG_ DAS_velocityProfile_calcDelay m3 : 58|3@1+ (0.006666666666666667,0) [0|0] "" Vector__XXX
 SG_ DAS_longControlStack M : 61|3@1+ (1,0) [0|0] "" Vector__XXX

BO_ 522 DAS_longControlTuningParameters: 8 Vector__XXX
 SG_ DAS_longControlTuningParametersChecksum : 0|8@1+ (1,0) [0|0] "" Vector__XXX
 SG_ DAS_longControlTuningParametersCounter : 8|3@1+ (1,0) [0|0] "" Vector__XXX
 SG_ DAS_velocityProfile_delayBeforet0 : 11|7@1+ (0.01,0) [0|0] "" Vector__XXX
 SG_ DAS_velocityProfile_futureTargetSpeedFwdDt : 18|7@1+ (0.01,0) [0|0] "" Vector__XXX
 SG_ DAS_velocityProfile_Dt_t0t1 : 32|7@1+ (0.01,0) [0|0] "" Vector__XXX
 SG_ DAS_velocityProfile_Dt_t1t2 : 39|7@1+ (0.01,0) [0|0] "" Vector__XXX

BO_ 526 DAS_autonomyControl: 8 Vector__XXX
 SG_ DAS_autonomyControlChecksum : 0|8@1+ (1,0) [0|0] "" Vector__XXX
 SG_ DAS_autonomyControlCounter : 8|3@1+ (1,0) [0|0] "" Vector__XXX
 SG_ DAS_manualDrivingProhibited : 11|1@1+ (1,0) [0|0] "" Vector__XXX
 SG_ DAS_autonomyControlActive : 12|1@1+ (1,0) [0|0] "" Vector__XXX
 SG_ DAS_autonomyBehavior : 13|2@1+ (1,0) [0|0] "" Vector__XXX

BO_ 529 RCM_status: 8 Vector__XXX
 SG_ RCM_statusChecksum : 0|8@1+ (1,0) [0|0] "" Vector__XXX
 SG_ RCM_statusCounter : 8|4@1+ (1,0) [0|0] "" Vector__XXX
 SG_ RCM_armStatus : 12|2@1+ (1,0) [0|0] "" Vector__XXX
 SG_ RCM_warningIndicatorState : 14|2@1+ (1,0) [0|0] "" Vector__XXX
 SG_ RCM_passAirbagIndicatorRequest : 16|2@1+ (1,0) [0|0] "" Vector__XXX
 SG_ RCM_airbagCutoffStatus : 18|2@1+ (1,0) [0|0] "" Vector__XXX
 SG_ RCM_alrSwitchStatus : 20|2@1+ (1,0) [0|0] "" Vector__XXX
 SG_ RCM_vinLearnFlag : 22|2@1+ (1,0) [0|0] "" Vector__XXX
 SG_ RCM_seatTrackPositionDrvr : 24|2@1+ (1,0) [0|0] "" Vector__XXX
 SG_ RCM_seatTrackPositionPass : 26|2@1+ (1,0) [0|0] "" Vector__XXX
 SG_ RCM_edr1State : 28|2@1+ (1,0) [0|0] "" Vector__XXX
 SG_ RCM_edr2State : 30|2@1+ (1,0) [0|0] "" Vector__XXX
 SG_ RCM_keepPowerReason : 32|4@1+ (1,0) [0|0] "" Vector__XXX
 SG_ RCM_imuOffsetLearnState : 36|2@1+ (1,0) [0|0] "" Vector__XXX
 SG_ RCM_edr3State : 38|2@1+ (1,0) [0|0] "" Vector__XXX
 SG_ RCM_driverOrientationInitStatus : 40|3@1+ (1,0) [0|0] "" Vector__XXX
 SG_ RCM_occupantClassificationSource : 43|1@1+ (1,0) [0|0] "" Vector__XXX
 SG_ RCM_pedProEDR1State : 44|2@1+ (1,0) [0|0] "" Vector__XXX
 SG_ RCM_pedProEDR2State : 46|2@1+ (1,0) [0|0] "" Vector__XXX

BO_ 545 VCFRONT_LVPowerState: 8 Vector__XXX
 SG_ VCFRONT_LVPowerStateIndex M : 0|5@1+ (1,0) [0|0] "" Vector__XXX
 SG_ VCFRONT_vehiclePowerState : 5|2@1+ (1,0) [0|0] "" Vector__XXX
 SG_ VCFRONT_cpLVRequest m1 : 8|2@1+ (1,0) [0|0] "" Vector__XXX
 SG_ VCFRONT_parkLVState m0 : 8|2@1+ (1,0) [0|0] "" Vector__XXX
 SG_ VCFRONT_epasLVState m1 : 10|2@1+ (1,0) [0|0] "" Vector__XXX
 SG_ VCFRONT_espLVState m0 : 10|2@1+ (1,0) [0|0] "" Vector__XXX
 SG_ VCFRONT_hvcLVRequest m1 : 12|2@1+ (1,0) [0|0] "" Vector__XXX
 SG_ VCFRONT_radcLVState m0 : 12|2@1+ (1,0) [0|0] "" Vector__XXX
 SG_ VCFRONT_hvacCompLVState m0 : 14|2@1+ (1,0) [0|0] "" Vector__XXX
 SG_ VCFRONT_tasLVState m1 : 14|2@1+ (1,0) [0|0] "" Vector__XXX
 SG_ VCFRONT_pcsLVState m1 : 16|2@1+ (1,0) [0|0] "" Vector__XXX
 SG_ VCFRONT_ptcLVRequest m0 : 16|2@1+ (1,0) [0|0] "" Vector__XXX
 SG_ VCFRONT_CMPDLVState m1 : 18|2@1+ (1,0) [0|0] "" Vector__XXX
 SG_ VCFRONT_sccmLVRequest m0 : 18|2@1+ (1,0) [0|0] "" Vector__XXX
 SG_ VCFRONT_hcmlLVState m1 : 20|2@1+ (1,0) [0|0] "" Vector__XXX
 SG_ VCFRONT_tpmsLVRequest m0 : 20|2@1+ (1,0) [0|0] "" Vector__XXX
 SG_ VCFRONT_hcmrLVState m1 : 22|2@1+ (1,0) [0|0] "" Vector__XXX
 SG_ VCFRONT_rcmLVRequest m0 : 22|2@1+ (1,0) [0|0] "" Vector__XXX
 SG_ VCFRONT_MCUAudioLVState m1 : 24|2@1+ (1,0) [0|0] "" Vector__XXX
 SG_ VCFRONT_iBoosterLVState m0 : 24|2@1+ (1,0) [0|0] "" Vector__XXX
 SG_ VCFRONT_espValveLVState m1 : 26|2@1+ (1,0) [0|0] "" Vector__XXX
 SG_ VCFRONT_tunerLVRequest m0 : 26|2@1+ (1,0) [0|0] "" Vector__XXX
 SG_ VCFRONT_MCUGraphicsLVState m1 : 28|2@1+ (1,0) [0|0] "" Vector__XXX
 SG_ VCFRONT_amplifierLVRequest m0 : 28|2@1+ (1,0) [0|0] "" Vector__XXX
 SG_ VCFRONT_das1HighCurrentLVState m0 : 30|2@1+ (1,0) [0|0] "" Vector__XXX
 SG_ VC_dcdcSupportRequest m1 : 30|1@1+ (1,0) [0|0] "" Vector__XXX
 SG_ VC_hvStateRequest m1 : 31|3@1+ (1,0) [0|0] "" Vector__XXX
 SG_ VCFRONT_das2HighCurrentLVState m0 : 32|2@1+ (1,0) [0|0] "" Vector__XXX
 SG_ VCFRONT_dirLVRequest m0 : 34|2@1+ (1,0) [0|0] "" Vector__XXX
 SG_ VCFRONT_difLVState m0 : 36|2@1+ (1,0) [0|0] "" Vector__XXX
 SG_ VCFRONT_oilPumpFrontLVState m0 : 38|2@1+ (1,0) [0|0] "" Vector__XXX
 SG_ VC_persistAccPowerRequestOverridden m1 : 39|1@1+ (1,0) [0|0] "" Vector__XXX
 SG_ VCFRONT_oilPumpRearLVRequest m0 : 40|2@1+ (1,0) [0|0] "" Vector__XXX
 SG_ VC_accPortPowerRequest m1 : 40|1@1+ (1,0) [0|0] "" Vector__XXX
 SG_ VC_persistAccPortPowerState m1 : 41|3@1+ (1,0) [0|0] "" Vector__XXX
 SG_ VCFRONT_ocsLVRequest m0 : 42|2@1+ (1,0) [0|0] "" Vector__XXX
 SG_ VCFRONT_vcleftHiCurrentLVState m0 : 44|2@1+ (1,0) [0|0] "" Vector__XXX
 SG_ VCFRONT_vcrightHiCurrentLVState m0 : 46|2@1+ (1,0) [0|0] "" Vector__XXX
 SG_ VC_noAccDeviceDetectedWhileIdle m1 : 46|1@1+ (1,0) [0|0] "" Vector__XXX
 SG_ VCFRONT_uiHiCurrentLVState m0 : 48|2@1+ (1,0) [0|0] "" Vector__XXX
 SG_ VCFRONT_inAccessoryPlus : 50|1@1+ (1,0) [0|0] "" Vector__XXX
 SG_ VCFRONT_LVShuttingDown : 51|1@1+ (1,0) [0|0] "" Vector__XXX
 SG_ VCFRONT_LVPowerStateCounter : 52|4@1+ (1,0) [0|0] "" Vector__XXX
 SG_ VCFRONT_LVPowerStateChecksum : 56|8@1+ (1,0) [0|0] "" Vector__XXX

BO_ 546 VCLEFT_epbmStatus: 8 Vector__XXX
 SG_ VCLEFT_cdpRequestState : 0|1@1+ (1,0) [0|0] "" Vector__XXX
 SG_ VCLEFT_epbmSystemStatusQF : 3|1@1+ (1,0) [0|0] "" Vector__XXX
 SG_ VCLEFT_epbmUnitStatus : 4|5@1+ (1,0) [0|0] "" Vector__XXX
 SG_ VCLEFT_epbmCdpState : 9|2@1+ (1,0) [0|0] "" Vector__XXX
 SG_ VCLEFT_epbmStatusCounter : 52|4@1+ (1,0) [0|0] "" Vector__XXX
 SG_ VCLEFT_epbmStatusChecksum : 56|8@1+ (1,0) [0|0] "" Vector__XXX

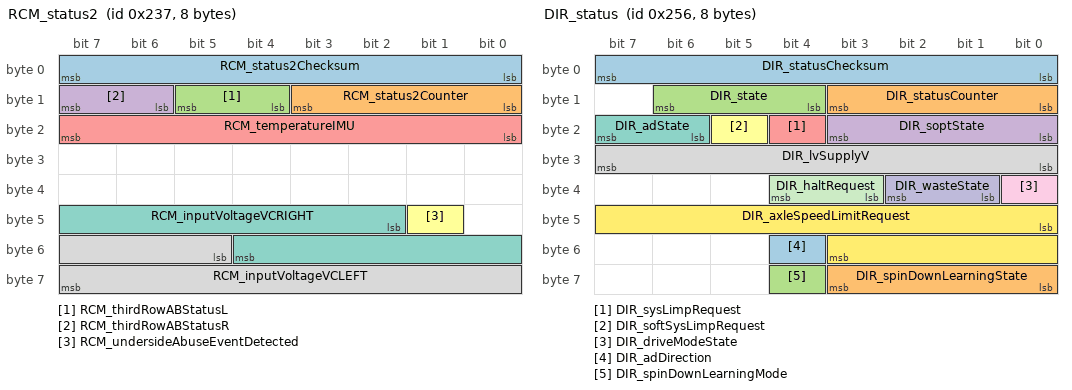
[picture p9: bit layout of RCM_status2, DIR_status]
BO_ 567 RCM_status2: 8 Vector__XXX
 SG_ RCM_status2Checksum : 0|8@1+ (1,0) [0|0] "" Vector__XXX
 SG_ RCM_status2Counter : 8|4@1+ (1,0) [0|0] "" Vector__XXX
 SG_ RCM_thirdRowABStatusL : 12|2@1+ (1,0) [0|0] "" Vector__XXX
 SG_ RCM_thirdRowABStatusR : 14|2@1+ (1,0) [0|0] "" Vector__XXX
 SG_ RCM_temperatureIMU : 16|8@1+ (0.5,-40) [0|0] "" Vector__XXX
 SG_ RCM_undersideAbuseEventDetected : 41|1@1+ (1,0) [0|0] "" Vector__XXX
 SG_ RCM_inputVoltageVCRIGHT : 42|11@1+ (0.01,0) [0|0] "" Vector__XXX
 SG_ RCM_inputVoltageVCLEFT : 53|11@1+ (0.01,0) [0|0] "" Vector__XXX

BO_ 576 PM_state2: 8 Vector__XXX
 SG_ PM_state2Checksum : 0|8@1+ (1,0) [0|0] "" Vector__XXX
 SG_ PM_state2Counter : 8|4@1+ (1,0) [0|0] "" Vector__XXX
 SG_ PM_vdcCmdState : 12|1@1+ (1,0) [0|0] "" Vector__XXX
 SG_ PM_ebrCmdState : 13|1@1+ (1,0) [0|0] "" Vector__XXX
 SG_ PM_vehicleSpeedQF : 14|1@1+ (1,0) [0|0] "" Vector__XXX

BO_ 598 DIR_status: 8 Vector__XXX
 SG_ DIR_statusChecksum : 0|8@1+ (1,0) [0|0] "" Vector__XXX
 SG_ DIR_statusCounter : 8|4@1+ (1,0) [0|0] "" Vector__XXX
 SG_ DIR_state : 12|3@1+ (1,0) [0|0] "" Vector__XXX
 SG_ DIR_soptState : 16|4@1+ (1,0) [0|0] "" Vector__XXX
 SG_ DIR_sysLimpRequest : 20|1@1+ (1,0) [0|0] "" Vector__XXX
 SG_ DIR_softSysLimpRequest : 21|1@1+ (1,0) [0|0] "" Vector__XXX
 SG_ DIR_adState : 22|2@1+ (1,0) [0|0] "" Vector__XXX
 SG_ DIR_lvSupplyV : 24|8@1+ (0.1,0) [0|0] "" Vector__XXX
 SG_ DIR_driveModeState : 32|1@1+ (1,0) [0|0] "" Vector__XXX
 SG_ DIR_wasteState : 33|2@1+ (1,0) [0|0] "" Vector__XXX
 SG_ DIR_haltRequest : 35|2@1+ (1,0) [0|0] "" Vector__XXX
 SG_ DIR_axleSpeedLimitRequest : 40|12@1+ (1,40) [0|0] "" Vector__XXX
 SG_ DIR_adDirection : 52|1@1+ (1,0) [0|0] "" Vector__XXX
 SG_ DIR_spinDownLearningState : 56|4@1+ (1,0) [0|0] "" Vector__XXX
 SG_ DIR_spinDownLearningMode : 60|1@1+ (1,0) [0|0] "" Vector__XXX

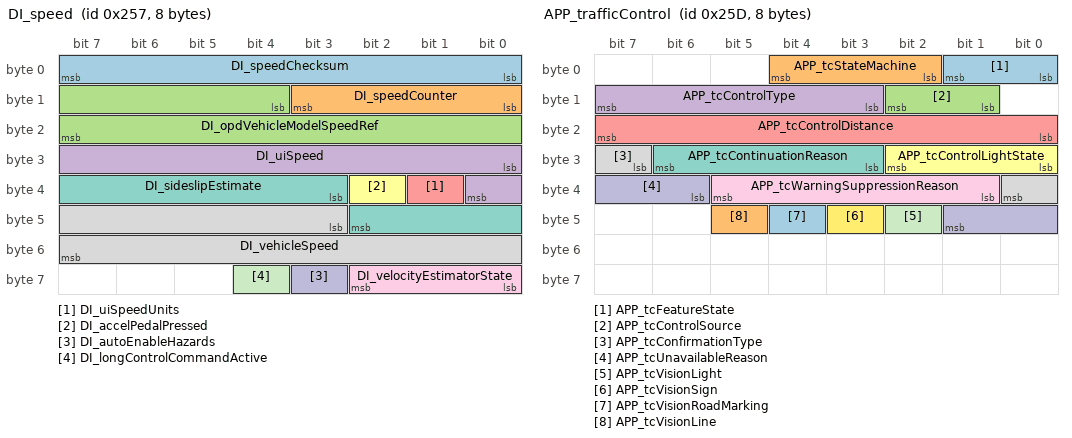
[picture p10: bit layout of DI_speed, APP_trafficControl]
BO_ 599 DI_speed: 8 Vector__XXX
 SG_ DI_speedChecksum : 0|8@1+ (1,0) [0|0] "" Vector__XXX
 SG_ DI_speedCounter : 8|4@1+ (1,0) [0|0] "" Vector__XXX
 SG_ DI_opdVehicleModelSpeedRef : 12|12@1+ (0.08,-40) [0|0] "" Vector__XXX
 SG_ DI_uiSpeed : 24|9@1+ (1,0) [0|0] "" Vector__XXX
 SG_ DI_uiSpeedUnits : 33|1@1+ (1,0) [0|0] "" Vector__XXX
 SG_ DI_accelPedalPressed : 34|1@1+ (1,0) [0|0] "" Vector__XXX
 SG_ DI_sideslipEstimate : 35|8@1- (0.0025,0) [0|0] "" Vector__XXX
 SG_ DI_vehicleSpeed : 43|13@1+ (0.08,-40) [0|0] "" Vector__XXX
 SG_ DI_velocityEstimatorState : 56|3@1+ (1,0) [0|0] "" Vector__XXX
 SG_ DI_autoEnableHazards : 59|1@1+ (1,0) [0|0] "" Vector__XXX
 SG_ DI_longControlCommandActive : 60|1@1+ (1,0) [0|0] "" Vector__XXX

BO_ 605 APP_trafficControl: 8 Vector__XXX
 SG_ APP_tcFeatureState : 0|2@1+ (1,0) [0|0] "" Vector__XXX
 SG_ APP_tcStateMachine : 2|3@1+ (1,0) [0|0] "" Vector__XXX
 SG_ APP_tcControlSource : 9|2@1+ (1,0) [0|0] "" Vector__XXX
 SG_ APP_tcControlType : 11|5@1+ (1,0) [0|0] "" Vector__XXX
 SG_ APP_tcControlDistance : 16|8@1+ (1,0) [0|0] "" Vector__XXX
 SG_ APP_tcControlLightState : 24|3@1+ (1,0) [0|0] "" Vector__XXX
 SG_ APP_tcContinuationReason : 27|4@1+ (1,0) [0|0] "" Vector__XXX
 SG_ APP_tcConfirmationType : 31|2@1+ (1,0) [0|0] "" Vector__XXX
 SG_ APP_tcWarningSuppressionReason : 33|5@1+ (1,0) [0|0] "" Vector__XXX
 SG_ APP_tcUnavailableReason : 38|4@1+ (1,0) [0|0] "" Vector__XXX
 SG_ APP_tcVisionLight : 42|1@1+ (1,0) [0|0] "" Vector__XXX
 SG_ APP_tcVisionSign : 43|1@1+ (1,0) [0|0] "" Vector__XXX
 SG_ APP_tcVisionRoadMarking : 44|1@1+ (1,0) [0|0] "" Vector__XXX
 SG_ APP_tcVisionLine : 45|1@1+ (1,0) [0|0] "" Vector__XXX

BO_ 611 VCRIGHT_epbmStatus: 8 Vector__XXX
 SG_ VCRIGHT_cdpRequestState : 0|1@1+ (1,0) [0|0] "" Vector__XXX
 SG_ VCRIGHT_epbmSystemStatusQF : 3|1@1+ (1,0) [0|0] "" Vector__XXX
 SG_ VCRIGHT_epbmUnitStatus : 4|5@1+ (1,0) [0|0] "" Vector__XXX
 SG_ VCRIGHT_epbmCdpState : 9|2@1+ (1,0) [0|0] "" Vector__XXX
 SG_ VCRIGHT_epbmStatusCounter : 52|4@1+ (1,0) [0|0] "" Vector__XXX
 SG_ VCRIGHT_epbmStatusChecksum : 56|8@1+ (1,0) [0|0] "" Vector__XXX

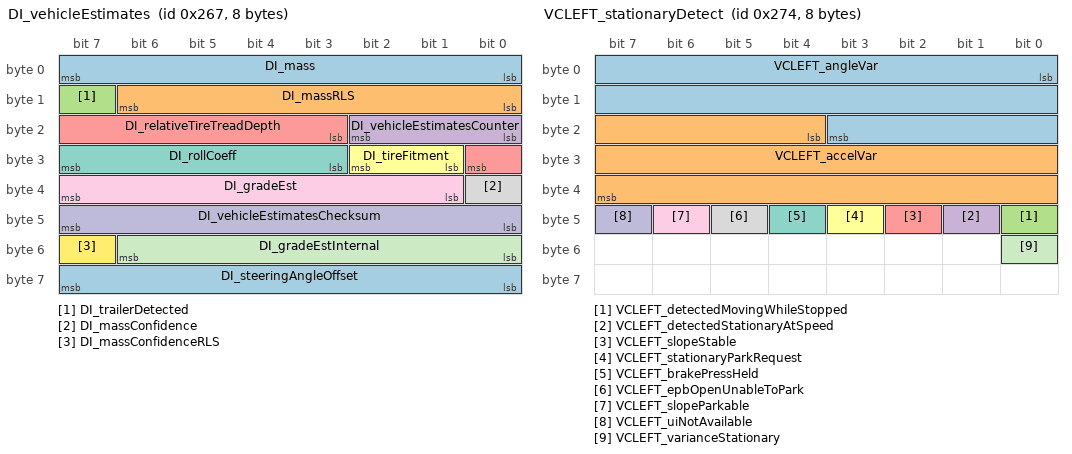
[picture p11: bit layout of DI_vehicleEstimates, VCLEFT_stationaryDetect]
BO_ 615 DI_vehicleEstimates: 8 Vector__XXX
 SG_ DI_mass : 0|8@1+ (25,1500) [0|0] "" Vector__XXX
 SG_ DI_massRLS : 8|7@1+ (45,1500) [0|0] "" Vector__XXX
 SG_ DI_trailerDetected : 15|1@1+ (1,0) [0|0] "" Vector__XXX
 SG_ DI_vehicleEstimatesCounter : 16|3@1+ (1,0) [0|0] "" Vector__XXX
 SG_ DI_relativeTireTreadDepth : 19|6@1- (0.4,0) [0|0] "" Vector__XXX
 SG_ DI_tireFitment : 25|2@1+ (1,0) [0|0] "" Vector__XXX
 SG_ DI_rollCoeff : 27|5@1+ (0.001,0) [0|0] "" Vector__XXX
 SG_ DI_massConfidence : 32|1@1+ (1,0) [0|0] "" Vector__XXX
 SG_ DI_gradeEst : 33|7@1- (1,0) [0|0] "" Vector__XXX
 SG_ DI_vehicleEstimatesChecksum : 40|8@1+ (1,0) [0|0] "" Vector__XXX
 SG_ DI_gradeEstInternal : 48|7@1- (1,0) [0|0] "" Vector__XXX
 SG_ DI_massConfidenceRLS : 55|1@1+ (1,0) [0|0] "" Vector__XXX
 SG_ DI_steeringAngleOffset : 56|8@1- (0.2,0) [0|0] "" Vector__XXX

BO_ 628 VCLEFT_stationaryDetect: 8 Vector__XXX
 SG_ VCLEFT_angleVar : 0|20@1+ (1e-05,0) [0|0] "" Vector__XXX
 SG_ VCLEFT_accelVar : 20|20@1+ (1e-05,0) [0|0] "" Vector__XXX
 SG_ VCLEFT_detectedMovingWhileStopped : 40|1@1+ (1,0) [0|0] "" Vector__XXX
 SG_ VCLEFT_detectedStationaryAtSpeed : 41|1@1+ (1,0) [0|0] "" Vector__XXX
 SG_ VCLEFT_slopeStable : 42|1@1+ (1,0) [0|0] "" Vector__XXX
 SG_ VCLEFT_stationaryParkRequest : 43|1@1+ (1,0) [0|0] "" Vector__XXX
 SG_ VCLEFT_brakePressHeld : 44|1@1+ (1,0) [0|0] "" Vector__XXX
 SG_ VCLEFT_epbOpenUnableToPark : 45|1@1+ (1,0) [0|0] "" Vector__XXX
 SG_ VCLEFT_slopeParkable : 46|1@1+ (1,0) [0|0] "" Vector__XXX
 SG_ VCLEFT_uiNotAvailable : 47|1@1+ (1,0) [0|0] "" Vector__XXX
 SG_ VCLEFT_varianceStationary : 48|1@1+ (1,0) [0|0] "" Vector__XXX

BO_ 637 APS_eacMonitor: 8 Vector__XXX
 SG_ APS_eacAllow : 0|2@1+ (1,0) [0|0] "" Vector__XXX
 SG_ APS_eacMonitorCounter : 8|4@1+ (1,0) [0|0] "" Vector__XXX
 SG_ APS_eacMonitorChecksum : 16|8@1+ (1,0) [0|0] "" Vector__XXX

BO_ 646 DI_locStatus: 8 Vector__XXX
 SG_ DI_locStatusChecksum : 0|8@1+ (1,0) [0|0] "" Vector__XXX
 SG_ DI_locStatusCounter : 8|4@1+ (1,0) [0|0] "" Vector__XXX
 SG_ DI_cruiseState : 12|3@1+ (1,0) [0|0] "" Vector__XXX
 SG_ DI_cruiseSetSpeed : 15|9@1+ (0.5,0) [0|0] "" Vector__XXX
 SG_ DI_cruiseSetSpeedUnits : 24|1@1+ (1,0) [0|0] "" Vector__XXX
 SG_ DI_autoparkState : 25|4@1+ (1,0) [0|0] "" Vector__XXX
 SG_ DI_parkBrakeState : 29|4@1+ (1,0) [0|0] "" Vector__XXX
 SG_ DI_aebState : 33|3@1+ (1,0) [0|0] "" Vector__XXX
 SG_ DI_loncDeactivationReason : 36|2@1+ (1,0) [0|0] "" Vector__XXX
 SG_ DI_vehicleHoldState : 38|3@1+ (1,0) [0|0] "" Vector__XXX
 SG_ DI_summonInPanic : 41|1@1+ (1,0) [0|0] "" Vector__XXX
 SG_ DI_onePedalDrivingState : 42|4@1+ (1,0) [0|0] "" Vector__XXX
 SG_ DI_brakeStandActive : 46|1@1+ (1,0) [0|0] "" Vector__XXX
 SG_ DI_regenBackfillState : 47|2@1+ (1,0) [0|0] "" Vector__XXX
 SG_ DI_cruiseNotAvailableReason : 49|6@1+ (1,0) [0|0] "" Vector__XXX
 SG_ DI_cruiseFaultReason : 55|5@1+ (1,0) [0|0] "" Vector__XXX
 SG_ DI_cruiseCancelReason : 60|4@1+ (1,0) [0|0] "" Vector__XXX

BO_ 649 DAS_pmmControl: 8 Vector__XXX
 SG_ DAS_pmmControlChecksum : 0|8@1+ (1,0) [0|0] "" Vector__XXX
 SG_ DAS_pmmControlCounter : 8|3@1+ (1,0) [0|0] "" Vector__XXX
 SG_ DAS_pmmAccelMax : 11|9@1+ (0.04,-15) [0|0] "" Vector__XXX

BO_ 659 UI_chassisControl: 8 Vector__XXX
 SG_ UI_steeringTuneRequest : 0|2@1+ (1,0) [0|0] "" Vector__XXX
 SG_ UI_tractionControlMode : 2|3@1+ (1,0) [0|0] "" Vector__XXX
 SG_ UI_parkBrakeRequest : 5|2@1+ (1,0) [0|0] "" Vector__XXX
 SG_ UI_narrowGarages : 7|1@1+ (1,0) [0|0] "" Vector__XXX
 SG_ UI_winchModeRequest : 8|2@1+ (1,0) [0|0] "" Vector__XXX
 SG_ UI_zeroSpeedConfirmed : 10|2@1+ (1,0) [0|0] "" Vector__XXX
 SG_ UI_trailerMode : 12|1@1+ (1,0) [0|0] "" Vector__XXX
 SG_ UI_distanceUnits : 13|1@1+ (1,0) [0|0] "" Vector__XXX
 SG_ UI_dasDebugEnable : 14|1@1+ (1,0) [0|0] "" Vector__XXX
 SG_ UI_accOvertakeEnable : 16|2@1+ (1,0) [0|0] "" Vector__XXX
 SG_ UI_aebEnable : 18|2@1+ (1,0) [0|0] "" Vector__XXX
 SG_ UI_aesEnable : 20|2@1+ (1,0) [0|0] "" Vector__XXX
 SG_ UI_ahlbEnable : 22|2@1+ (1,0) [0|0] "" Vector__XXX
 SG_ UI_autoLaneChangeEnable : 24|2@1+ (1,0) [0|0] "" Vector__XXX
 SG_ UI_winchProxUserOverride : 26|1@1+ (1,0) [0|0] "" Vector__XXX
 SG_ UI_rebootAutopilot : 27|1@1+ (1,0) [0|0] "" Vector__XXX
 SG_ UI_autoParkRequest : 28|4@1+ (1,0) [0|0] "" Vector__XXX
 SG_ UI_bsdEnable : 32|2@1+ (1,0) [0|0] "" Vector__XXX
 SG_ UI_fcwEnable : 34|2@1+ (1,0) [0|0] "" Vector__XXX
 SG_ UI_fcwSensitivity : 36|2@1+ (1,0) [0|0] "" Vector__XXX
 SG_ UI_latControlEnable : 38|2@1+ (1,0) [0|0] "" Vector__XXX
 SG_ UI_ldwEnable : 40|2@1+ (1,0) [0|0] "" Vector__XXX
 SG_ UI_pedalSafetyEnable : 42|2@1+ (1,0) [0|0] "" Vector__XXX
 SG_ UI_pedalMap_epas : 44|2@1+ (1,0) [0|0] "" Vector__XXX
 SG_ UI_redLightStopSignEnable : 46|2@1+ (1,0) [0|0] "" Vector__XXX
 SG_ UI_selfParkTune : 48|4@1+ (1,0) [0|0] "" Vector__XXX
 SG_ UI_chassisControlCounter : 52|4@1+ (1,0) [0|0] "" Vector__XXX
 SG_ UI_chassisControlChecksum : 56|8@1+ (1,0) [0|0] "" Vector__XXX

BO_ 665 DAS_integratedSafetyFront: 8 Vector__XXX
 SG_ DAS_safetyFrontChecksum : 0|8@1+ (1,0) [0|0] "" Vector__XXX
 SG_ DAS_safetyFrontCounter : 8|4@1+ (1,0) [0|0] "" Vector__XXX
 SG_ DAS_timeToImpactFront : 12|9@1+ (1,0) [0|0] "" Vector__XXX
 SG_ DAS_timeToImpactFrontQF : 21|1@1+ (1,0) [0|0] "" Vector__XXX
 SG_ DAS_predictedImpactVelFront : 22|7@1+ (0.5,0) [0|0] "" Vector__XXX
 SG_ DAS_predictedImpactVelFrontQF : 29|1@1+ (1,0) [0|0] "" Vector__XXX
 SG_ DAS_relativeVelocityFront : 30|6@1+ (1,-32) [0|0] "" Vector__XXX
 SG_ DAS_relativeVelocityFrontQF : 36|1@1+ (1,0) [0|0] "" Vector__XXX
 SG_ DAS_targetDistanceFront : 37|7@1+ (0.1,0) [0|0] "" Vector__XXX
 SG_ DAS_targetDistanceFrontQF : 44|1@1+ (1,0) [0|0] "" Vector__XXX
 SG_ DAS_relativeAccelerationFront : 45|8@1+ (0.1,-12.8) [0|0] "" Vector__XXX
 SG_ DAS_relativeAccelerationFrontQF : 53|1@1+ (1,0) [0|0] "" Vector__XXX
 SG_ DAS_imminentCollisionFront : 54|1@1+ (1,0) [0|0] "" Vector__XXX
 SG_ DAS_imminentCollisionFrontQF : 55|1@1+ (1,0) [0|0] "" Vector__XXX
 SG_ DAS_predictedImpactOvrlapFront : 56|3@1+ (12.5,0) [0|0] "" Vector__XXX
 SG_ DAS_predictedImpactOvrlapFrontQF : 59|1@1+ (1,0) [0|0] "" Vector__XXX
 SG_ DAS_idfEnableFlag : 60|1@1+ (1,0) [0|0] "" Vector__XXX

BO_ 680 EPBL_status: 8 Vector__XXX
 SG_ EPBL_systemStatus : 0|4@1+ (1,0) [0|0] "" Vector__XXX
 SG_ EPBL_freeRollModeStatus : 4|2@1+ (1,0) [0|0] "" Vector__XXX
 SG_ EPBL_driverIsLeaving : 6|1@1+ (1,0) [0|0] "" Vector__XXX
 SG_ EPBL_driverIsLeavingAnySpeed : 7|1@1+ (1,0) [0|0] "" Vector__XXX
 SG_ EPBL_systemCdpAvailable : 8|1@1+ (1,0) [0|0] "" Vector__XXX
 SG_ EPBL_chimeRequest : 9|3@1+ (1,0) [0|0] "" Vector__XXX
 SG_ EPBL_telltale : 12|3@1+ (1,0) [0|0] "" Vector__XXX
 SG_ EPBL_contactorCycleNotNeededForWinchEntry : 15|1@1+ (1,0) [0|0] "" Vector__XXX
 SG_ EPBL_redundantBrakingEnabled : 16|1@1+ (1,0) [0|0] "" Vector__XXX
 SG_ EPBL_summonEnabled : 17|1@1+ (1,0) [0|0] "" Vector__XXX
 SG_ EPBL_brakeLight : 18|1@1+ (1,0) [0|0] "" Vector__XXX
 SG_ EPBL_epbConfigMismatch : 19|1@1+ (1,0) [0|0] "" Vector__XXX
 SG_ EPBL_brakeConfirmedPressed : 20|1@1+ (1,0) [0|0] "" Vector__XXX
 SG_ EPBL_requestUserConfirmation : 21|1@1+ (1,0) [0|0] "" Vector__XXX
 SG_ EPBL_uiWinchModeMiscBlocking : 22|1@1+ (1,0) [0|0] "" Vector__XXX
 SG_ EPBL_winchModeActive : 23|1@1+ (1,0) [0|0] "" Vector__XXX
 SG_ EPBL_updateMode : 24|1@1+ (1,0) [0|0] "" Vector__XXX
 SG_ EPBL_winchModePermissive : 25|1@1+ (1,0) [0|0] "" Vector__XXX
 SG_ EPBL_winchModePending : 26|1@1+ (1,0) [0|0] "" Vector__XXX
 SG_ EPBL_cdpRequest : 27|1@1+ (1,0) [0|0] "" Vector__XXX
 SG_ EPBL_uiParkAvailable : 28|2@1+ (1,0) [0|0] "" Vector__XXX
 SG_ EPBL_brakeDiscWipeRequest : 30|2@1+ (1,0) [0|0] "" Vector__XXX
 SG_ EPBL_showUiGearShifter : 32|1@1+ (1,0) [0|0] "" Vector__XXX
 SG_ EPBL_uiWinchModeLvStatus : 33|2@1+ (1,0) [0|0] "" Vector__XXX
 SG_ EPBL_showStalkFaultedOnUi : 45|1@1+ (1,0) [0|0] "" Vector__XXX
 SG_ EPBL_espPowerRequest : 46|1@1+ (1,0) [0|0] "" Vector__XXX
 SG_ EPBL_okToPark : 47|1@1+ (1,0) [0|0] "" Vector__XXX
 SG_ EPBL_hornRequest : 48|1@1+ (1,0) [0|0] "" Vector__XXX
 SG_ EPBL_winchModeAvailable : 49|1@1+ (1,0) [0|0] "" Vector__XXX
 SG_ EPBL_bothDisconnected : 50|1@1+ (1,0) [0|0] "" Vector__XXX
 SG_ EPBL_blockDrive : 51|1@1+ (1,0) [0|0] "" Vector__XXX
 SG_ EPBL_statusCounter : 52|4@1+ (1,0) [0|0] "" Vector__XXX
 SG_ EPBL_statusChecksum : 56|8@1+ (1,0) [0|0] "" Vector__XXX

BO_ 690 VCFRONT_LVDebugData: 8 Vector__XXX
 SG_ VCFRONT_LVDebugDataIndex M : 0|4@1+ (1,0) [0|0] "" Vector__XXX
 SG_ VCFRONT_battSensorCurrentIntrvlMax5s m0 : 4|16@1- (0.005,0) [0|0] "" Vector__XXX
 SG_ VCFRONT_vcleftMaxCurrent m1 : 4|12@1+ (0.05,0) [0|0] "" Vector__XXX
 SG_ VCFRONT_vcrightMaxCurrent m2 : 4|12@1+ (0.05,0) [0|0] "" Vector__XXX
 SG_ VCFRONT_batBridgeMaxCurrent m9 : 8|13@1- (0.1,0) [0|0] "" Vector__XXX
 SG_ VCFRONT_epas3pMaxCurrent m3 : 8|14@1+ (0.1,0) [0|0] "" Vector__XXX
 SG_ VCFRONT_epas3sMaxCurrent m4 : 8|14@1+ (0.1,0) [0|0] "" Vector__XXX
 SG_ VCFRONT_hcuEspAbsMaxCurrent m6 : 8|14@1+ (0.1,0) [0|0] "" Vector__XXX
 SG_ VCFRONT_iBoosterMaxCurrent m5 : 8|14@1+ (0.1,0) [0|0] "" Vector__XXX
 SG_ VCFRONT_loadshedMaxCurrent m10 : 8|14@1+ (0.1,0) [0|0] "" Vector__XXX
 SG_ VCFRONT_pcsMaxCurrent m7 : 8|13@1- (0.1,0) [0|0] "" Vector__XXX
 SG_ VCFRONT_vehicleCurrentIntrvlMax5s m8 : 8|16@1- (0.01,0) [0|0] "" Vector__XXX
 SG_ VCFRONT_vcleftMinCurrent m1 : 16|12@1+ (0.05,0) [0|0] "" Vector__XXX
 SG_ VCFRONT_vcrightMinCurrent m2 : 16|12@1+ (0.05,0) [0|0] "" Vector__XXX
 SG_ VCFRONT_battSensorCurrentIntrvlMin5s m0 : 20|16@1- (0.005,0) [0|0] "" Vector__XXX
 SG_ VCFRONT_loadshedMinCurrent m10 : 22|14@1+ (0.1,0) [0|0] "" Vector__XXX
 SG_ VCFRONT_batBridgeMinCurrent m9 : 24|13@1- (0.1,0) [0|0] "" Vector__XXX
 SG_ VCFRONT_epas3pMinCurrent m3 : 24|14@1+ (0.1,0) [0|0] "" Vector__XXX
 SG_ VCFRONT_epas3sMinCurrent m4 : 24|14@1+ (0.1,0) [0|0] "" Vector__XXX
 SG_ VCFRONT_hcuEspAbsMinCurrent m6 : 24|14@1+ (0.1,0) [0|0] "" Vector__XXX
 SG_ VCFRONT_iBoosterMinCurrent m5 : 24|14@1+ (0.1,0) [0|0] "" Vector__XXX
 SG_ VCFRONT_pcsMinCurrent m7 : 24|13@1- (0.1,0) [0|0] "" Vector__XXX
 SG_ VCFRONT_vehicleCurrentIntrvlMin5s m8 : 24|16@1- (0.01,0) [0|0] "" Vector__XXX
 SG_ VCFRONT_vcleftMaxVoltage m1 : 28|12@1+ (0.005443676098,0) [0|0] "" Vector__XXX
 SG_ VCFRONT_vcrightMaxVoltage m2 : 28|12@1+ (0.005443676098,0) [0|0] "" Vector__XXX
 SG_ VCFRONT_battSensorVoltIntrvlMax5s m0 : 36|13@1- (0.005443676098,0) [0|0] "" Vector__XXX
 SG_ VCFRONT_pcsBridgeMaxCurrent m9 : 37|13@1- (0.1,0) [0|0] "" Vector__XXX
 SG_ VCFRONT_epas3pMaxVoltage m3 : 40|12@1+ (0.005443676098,0) [0|0] "" Vector__XXX
 SG_ VCFRONT_epas3sMaxVoltage m4 : 40|12@1+ (0.005443676098,0) [0|0] "" Vector__XXX
 SG_ VCFRONT_hcuEspAbsMaxVoltage m6 : 40|12@1+ (0.005443676098,0) [0|0] "" Vector__XXX
 SG_ VCFRONT_iBoosterMaxVoltage m5 : 40|12@1+ (0.005443676098,0) [0|0] "" Vector__XXX
 SG_ VCFRONT_pcsMaxVoltage m7 : 40|12@1+ (0.005443676098,0) [0|0] "" Vector__XXX
 SG_ VCFRONT_vcleftMinVoltage m1 : 40|12@1+ (0.005443676098,0) [0|0] "" Vector__XXX
 SG_ VCFRONT_vcrightMinVoltage m2 : 40|12@1+ (0.005443676098,0) [0|0] "" Vector__XXX
 SG_ VCFRONT_battSensorVoltIntrvlMin5s m0 : 49|13@1- (0.005443676098,0) [0|0] "" Vector__XXX
 SG_ VCFRONT_pcsBridgeMinCurrent m9 : 50|13@1- (0.1,0) [0|0] "" Vector__XXX
 SG_ VCFRONT_epas3pMinVoltage m3 : 52|12@1+ (0.005443676098,0) [0|0] "" Vector__XXX
 SG_ VCFRONT_epas3sMinVoltage m4 : 52|12@1+ (0.005443676098,0) [0|0] "" Vector__XXX
 SG_ VCFRONT_hcuEspAbsMinVoltage m6 : 52|12@1+ (0.005443676098,0) [0|0] "" Vector__XXX
 SG_ VCFRONT_iBoosterMinVoltage m5 : 52|12@1+ (0.005443676098,0) [0|0] "" Vector__XXX
 SG_ VCFRONT_pcsMinVoltage m7 : 52|12@1+ (0.005443676098,0) [0|0] "" Vector__XXX

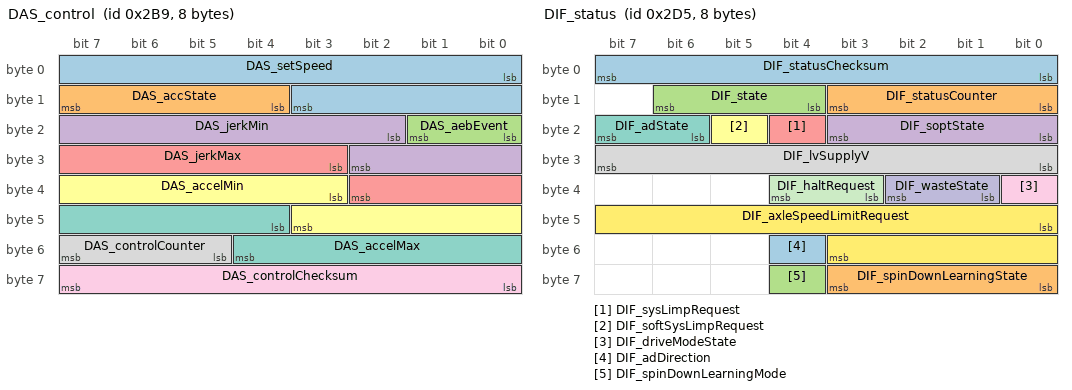
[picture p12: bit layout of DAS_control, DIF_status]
BO_ 697 DAS_control: 8 Vector__XXX
 SG_ DAS_setSpeed : 0|12@1+ (0.1,0) [0|0] "" Vector__XXX
 SG_ DAS_accState : 12|4@1+ (1,0) [0|0] "" Vector__XXX
 SG_ DAS_aebEvent : 16|2@1+ (1,0) [0|0] "" Vector__XXX
 SG_ DAS_jerkMin : 18|9@1+ (0.03,-15.232) [0|0] "" Vector__XXX
 SG_ DAS_jerkMax : 27|8@1+ (0.059,0) [0|0] "" Vector__XXX
 SG_ DAS_accelMin : 35|9@1+ (0.04,-15) [0|0] "" Vector__XXX
 SG_ DAS_accelMax : 44|9@1+ (0.04,-15) [0|0] "" Vector__XXX
 SG_ DAS_controlCounter : 53|3@1+ (1,0) [0|0] "" Vector__XXX
 SG_ DAS_controlChecksum : 56|8@1+ (1,0) [0|0] "" Vector__XXX

BO_ 714 APP_gpsTime: 8 Vector__XXX
 SG_ APP_gpsSeconds : 0|32@1+ (1,0) [0|0] "" Vector__XXX
 SG_ APP_gpsNanoseconds : 32|32@1+ (1,0) [0|0] "" Vector__XXX

BO_ 725 DIF_status: 8 Vector__XXX
 SG_ DIF_statusChecksum : 0|8@1+ (1,0) [0|0] "" Vector__XXX
 SG_ DIF_statusCounter : 8|4@1+ (1,0) [0|0] "" Vector__XXX
 SG_ DIF_state : 12|3@1+ (1,0) [0|0] "" Vector__XXX
 SG_ DIF_soptState : 16|4@1+ (1,0) [0|0] "" Vector__XXX
 SG_ DIF_sysLimpRequest : 20|1@1+ (1,0) [0|0] "" Vector__XXX
 SG_ DIF_softSysLimpRequest : 21|1@1+ (1,0) [0|0] "" Vector__XXX
 SG_ DIF_adState : 22|2@1+ (1,0) [0|0] "" Vector__XXX
 SG_ DIF_lvSupplyV : 24|8@1+ (0.1,0) [0|0] "" Vector__XXX
 SG_ DIF_driveModeState : 32|1@1+ (1,0) [0|0] "" Vector__XXX
 SG_ DIF_wasteState : 33|2@1+ (1,0) [0|0] "" Vector__XXX
 SG_ DIF_haltRequest : 35|2@1+ (1,0) [0|0] "" Vector__XXX
 SG_ DIF_axleSpeedLimitRequest : 40|12@1+ (1,40) [0|0] "" Vector__XXX
 SG_ DIF_adDirection : 52|1@1+ (1,0) [0|0] "" Vector__XXX
 SG_ DIF_spinDownLearningState : 56|4@1+ (1,0) [0|0] "" Vector__XXX
 SG_ DIF_spinDownLearningMode : 60|1@1+ (1,0) [0|0] "" Vector__XXX

BO_ 744 EPBR_status: 8 Vector__XXX
 SG_ EPBR_systemStatus : 0|4@1+ (1,0) [0|0] "" Vector__XXX
 SG_ EPBR_freeRollModeStatus : 4|2@1+ (1,0) [0|0] "" Vector__XXX
 SG_ EPBR_driverIsLeaving : 6|1@1+ (1,0) [0|0] "" Vector__XXX
 SG_ EPBR_driverIsLeavingAnySpeed : 7|1@1+ (1,0) [0|0] "" Vector__XXX
 SG_ EPBR_systemCdpAvailable : 8|1@1+ (1,0) [0|0] "" Vector__XXX
 SG_ EPBR_chimeRequest : 9|3@1+ (1,0) [0|0] "" Vector__XXX
 SG_ EPBR_telltale : 12|3@1+ (1,0) [0|0] "" Vector__XXX
 SG_ EPBR_audioCurrentSpikeDetected : 15|1@1+ (1,0) [0|0] "" Vector__XXX
 SG_ EPBR_redundantBrakingEnabled : 16|1@1+ (1,0) [0|0] "" Vector__XXX
 SG_ EPBR_summonEnabled : 17|1@1+ (1,0) [0|0] "" Vector__XXX
 SG_ EPBR_brakeLight : 18|1@1+ (1,0) [0|0] "" Vector__XXX
 SG_ EPBR_epbConfigMismatch : 19|1@1+ (1,0) [0|0] "" Vector__XXX
 SG_ EPBR_brakeConfirmedPressed : 20|1@1+ (1,0) [0|0] "" Vector__XXX
 SG_ EPBR_requestUserConfirmation : 21|1@1+ (1,0) [0|0] "" Vector__XXX
 SG_ EPBR_uiWinchModeMiscBlocking : 22|1@1+ (1,0) [0|0] "" Vector__XXX
 SG_ EPBR_winchModeActive : 23|1@1+ (1,0) [0|0] "" Vector__XXX
 SG_ EPBR_updateMode : 24|1@1+ (1,0) [0|0] "" Vector__XXX
 SG_ EPBR_winchModePermissive : 25|1@1+ (1,0) [0|0] "" Vector__XXX
 SG_ EPBR_winchModePending : 26|1@1+ (1,0) [0|0] "" Vector__XXX
 SG_ EPBR_cdpRequest : 27|1@1+ (1,0) [0|0] "" Vector__XXX
 SG_ EPBR_uiParkAvailable : 28|2@1+ (1,0) [0|0] "" Vector__XXX
 SG_ EPBR_brakeDiscWipeRequest : 30|2@1+ (1,0) [0|0] "" Vector__XXX
 SG_ EPBR_showUiGearShifter : 32|1@1+ (1,0) [0|0] "" Vector__XXX
 SG_ EPBR_uiWinchModeLvStatus : 33|2@1+ (1,0) [0|0] "" Vector__XXX
 SG_ EPBR_contactorCycleNotNeededForWinchEntry : 35|1@1+ (1,0) [0|0] "" Vector__XXX
 SG_ EPBR_showStalkFaultedOnUi : 45|1@1+ (1,0) [0|0] "" Vector__XXX
 SG_ EPBR_espPowerRequest : 46|1@1+ (1,0) [0|0] "" Vector__XXX
 SG_ EPBR_okToPark : 47|1@1+ (1,0) [0|0] "" Vector__XXX
 SG_ EPBR_hornRequest : 48|1@1+ (1,0) [0|0] "" Vector__XXX
 SG_ EPBR_winchModeAvailable : 49|1@1+ (1,0) [0|0] "" Vector__XXX
 SG_ EPBR_bothDisconnected : 50|1@1+ (1,0) [0|0] "" Vector__XXX
 SG_ EPBR_blockDrive : 51|1@1+ (1,0) [0|0] "" Vector__XXX
 SG_ EPBR_statusCounter : 52|4@1+ (1,0) [0|0] "" Vector__XXX
 SG_ EPBR_statusChecksum : 56|8@1+ (1,0) [0|0] "" Vector__XXX

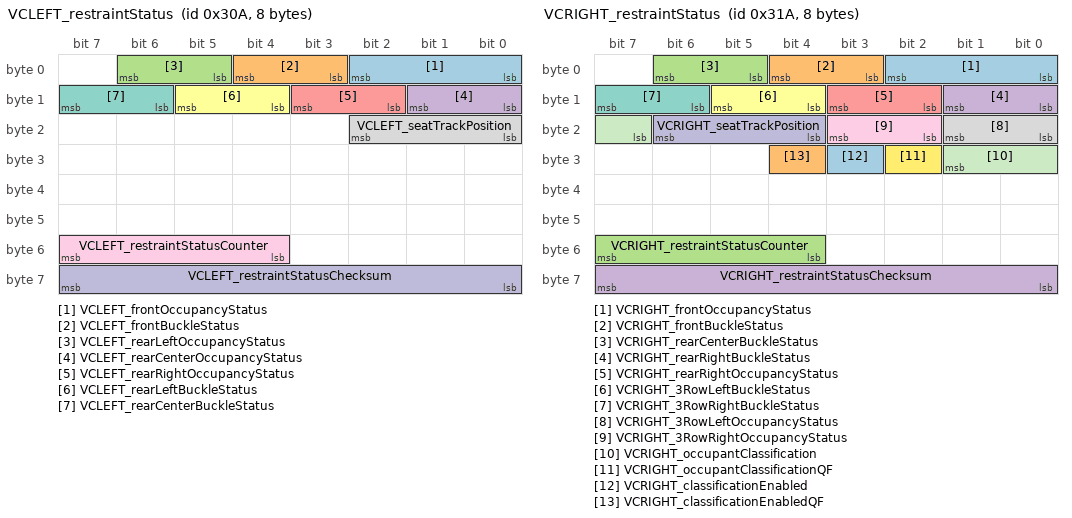
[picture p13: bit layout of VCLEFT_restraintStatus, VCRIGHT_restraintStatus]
BO_ 778 VCLEFT_restraintStatus: 8 Vector__XXX
 SG_ VCLEFT_frontOccupancyStatus : 0|3@1+ (1,0) [0|0] "" Vector__XXX
 SG_ VCLEFT_frontBuckleStatus : 3|2@1+ (1,0) [0|0] "" Vector__XXX
 SG_ VCLEFT_rearLeftOccupancyStatus : 5|2@1+ (1,0) [0|0] "" Vector__XXX
 SG_ VCLEFT_rearCenterOccupancyStatus : 8|2@1+ (1,0) [0|0] "" Vector__XXX
 SG_ VCLEFT_rearRightOccupancyStatus : 10|2@1+ (1,0) [0|0] "" Vector__XXX
 SG_ VCLEFT_rearLeftBuckleStatus : 12|2@1+ (1,0) [0|0] "" Vector__XXX
 SG_ VCLEFT_rearCenterBuckleStatus : 14|2@1+ (1,0) [0|0] "" Vector__XXX
 SG_ VCLEFT_seatTrackPosition : 16|3@1+ (1,0) [0|0] "" Vector__XXX
 SG_ VCLEFT_restraintStatusCounter : 52|4@1+ (1,0) [0|0] "" Vector__XXX
 SG_ VCLEFT_restraintStatusChecksum : 56|8@1+ (1,0) [0|0] "" Vector__XXX

BO_ 785 VCFRONT_AP_vehicleState10Hz: 8 Vector__XXX
 SG_ VCFRONT_AP_vehicleState10HzChecksum : 0|8@1+ (1,0) [0|0] "" Vector__XXX
 SG_ VCFRONT_AP_vehicleState10HzCounter : 8|4@1+ (1,0) [0|0] "" Vector__XXX
 SG_ VCFRONT_AP_driverPresent : 12|1@1+ (1,0) [0|0] "" Vector__XXX
 SG_ VCFRONT_AP_driverBuckleStatus : 13|1@1+ (1,0) [0|0] "" Vector__XXX
 SG_ VCFRONT_AP_das1OkToUseHighPower : 14|1@1+ (1,0) [0|0] "" Vector__XXX
 SG_ VCFRONT_AP_das2OkToUseHighPower : 15|1@1+ (1,0) [0|0] "" Vector__XXX
 SG_ VCFRONT_AP_vehiclePowerState : 16|2@1+ (1,0) [0|0] "" Vector__XXX
 SG_ VCFRONT_AP_inAccessoryPlus : 18|1@1+ (1,0) [0|0] "" Vector__XXX
 SG_ VCFRONT_AP_highBeamSwitchActive : 19|1@1+ (1,0) [0|0] "" Vector__XXX
 SG_ VCFRONT_AP_hornSwitchPressed : 20|1@1+ (1,0) [0|0] "" Vector__XXX
 SG_ VCFRONT_AP_swcAnyInteraction : 21|1@1+ (1,0) [0|0] "" Vector__XXX
 SG_ VCFRONT_AP_simLatchingTurnStalk : 22|2@1+ (1,0) [0|0] "" Vector__XXX
 SG_ VCFRONT_AP_indicatorLeftRequest : 24|2@1+ (1,0) [0|0] "" Vector__XXX
 SG_ VCFRONT_AP_indicatorRightRequest : 26|2@1+ (1,0) [0|0] "" Vector__XXX
 SG_ VCFRONT_AP_anyClosureOpen : 28|1@1+ (1,0) [0|0] "" Vector__XXX
 SG_ VCFRONT_AP_anyClosureSwitchPress : 29|1@1+ (1,0) [0|0] "" Vector__XXX
 SG_ VCFRONT_AP_anyLeftDoorOpen : 30|1@1+ (1,0) [0|0] "" Vector__XXX
 SG_ VCFRONT_AP_anyRightDoorOpen : 31|1@1+ (1,0) [0|0] "" Vector__XXX
 SG_ VCFRONT_AP_wiperSpeed : 32|4@1+ (1,0) [0|0] "" Vector__XXX
 SG_ VCFRONT_AP_wiperState : 36|4@1+ (1,0) [0|0] "" Vector__XXX
 SG_ VCFRONT_AP_rearTrunkOpen : 40|1@1+ (1,0) [0|0] "" Vector__XXX
 SG_ VCFRONT_AP_rightMirrorFoldState : 41|3@1+ (1,0) [0|0] "" Vector__XXX
 SG_ VCFRONT_AP_leftMirrorFoldState : 44|3@1+ (1,0) [0|0] "" Vector__XXX
 SG_ VCFRONT_AP_radarHeaterState : 47|3@1+ (1,0) [0|0] "" Vector__XXX
 SG_ VCFRONT_AP_highBeamControlState : 50|2@1+ (1,0) [0|0] "" Vector__XXX
 SG_ VCFRONT_AP_falconOpenToFitActive : 52|1@1+ (1,0) [0|0] "" Vector__XXX
 SG_ VCFRONT_AP_frunkOpen : 53|1@1+ (1,0) [0|0] "" Vector__XXX

BO_ 794 VCRIGHT_restraintStatus: 8 Vector__XXX
 SG_ VCRIGHT_frontOccupancyStatus : 0|3@1+ (1,0) [0|0] "" Vector__XXX
 SG_ VCRIGHT_frontBuckleStatus : 3|2@1+ (1,0) [0|0] "" Vector__XXX
 SG_ VCRIGHT_rearCenterBuckleStatus : 5|2@1+ (1,0) [0|0] "" Vector__XXX
 SG_ VCRIGHT_rearRightBuckleStatus : 8|2@1+ (1,0) [0|0] "" Vector__XXX
 SG_ VCRIGHT_rearRightOccupancyStatus : 10|2@1+ (1,0) [0|0] "" Vector__XXX
 SG_ VCRIGHT_3RowLeftBuckleStatus : 12|2@1+ (1,0) [0|0] "" Vector__XXX
 SG_ VCRIGHT_3RowRightBuckleStatus : 14|2@1+ (1,0) [0|0] "" Vector__XXX
 SG_ VCRIGHT_3RowLeftOccupancyStatus : 16|2@1+ (1,0) [0|0] "" Vector__XXX
 SG_ VCRIGHT_3RowRightOccupancyStatus : 18|2@1+ (1,0) [0|0] "" Vector__XXX
 SG_ VCRIGHT_seatTrackPosition : 20|3@1+ (1,0) [0|0] "" Vector__XXX
 SG_ VCRIGHT_occupantClassification : 23|3@1+ (1,0) [0|0] "" Vector__XXX
 SG_ VCRIGHT_occupantClassificationQF : 26|1@1+ (1,0) [0|0] "" Vector__XXX
 SG_ VCRIGHT_classificationEnabled : 27|1@1+ (1,0) [0|0] "" Vector__XXX
 SG_ VCRIGHT_classificationEnabledQF : 28|1@1+ (1,0) [0|0] "" Vector__XXX
 SG_ VCRIGHT_restraintStatusCounter : 52|4@1+ (1,0) [0|0] "" Vector__XXX
 SG_ VCRIGHT_restraintStatusChecksum : 56|8@1+ (1,0) [0|0] "" Vector__XXX

BO_ 811 APP_gpsAccuracies: 8 Vector__XXX
 SG_ APP_gpsAccuracy3D : 0|7@1+ (0.2,0) [0|0] "" Vector__XXX
 SG_ APP_gpsAccuracyHorizontal : 8|8@1+ (0.2,0) [0|0] "" Vector__XXX
 SG_ APP_gpsAccuracyVertical : 16|8@1+ (0.2,0) [0|0] "" Vector__XXX
 SG_ APP_gpsElevation : 24|14@1- (1,0) [0|0] "" Vector__XXX

BO_ 817 EPAS3P_info: 8 Vector__XXX
 SG_ EPAS3P_infoIndex M : 0|8@1+ (1,0) [0|0] "" Vector__XXX
 SG_ EPAS3P_infoBootUdsProtoVersion m20 : 8|8@1+ (1,0) [0|0] "" Vector__XXX
 SG_ EPAS3P_infoBuildType m10 : 8|8@1+ (1,0) [0|0] "" Vector__XXX
 SG_ EPAS3P_infoPcbaID m11 : 16|8@1+ (1,0) [0|0] "" Vector__XXX
 SG_ EPAS3P_infoAssemblyID m11 : 24|8@1+ (1,0) [0|0] "" Vector__XXX
 SG_ EPAS3P_infoApplicationCRC m13 : 32|32@1+ (1,0) [0|0] "" Vector__XXX
 SG_ EPAS3P_infoBootloaderCRC m20 : 32|32@1+ (1,0) [0|0] "" Vector__XXX
 SG_ EPAS3P_infoSubcomponent2 m23 : 32|32@1+ (1,0) [0|0] "" Vector__XXX
 SG_ EPAS3P_infoUsageID m11 : 32|16@1+ (1,0) [0|0] "" Vector__XXX
 SG_ EPAS3P_infoComponentID m10 : 48|16@1+ (1,0) [0|0] "" Vector__XXX

BO_ 822 DI_maxRatedPower: 8 Vector__XXX
 SG_ DI_sysDrivePowerRated : 0|10@1+ (1,0) [0|0] "" Vector__XXX
 SG_ DI_performancePackage : 11|3@1+ (1,0) [0|0] "" Vector__XXX
 SG_ DI_sysRegenPowerRated : 16|8@1+ (1,-100) [0|0] "" Vector__XXX

BO_ 823 DI_accelPedal: 8 Vector__XXX
 SG_ DI_track1IdlePedalVoltage : 0|9@1+ (0.0010784313725490198,0.65) [0|0] "" Vector__XXX
 SG_ DI_track2IdlePedalVoltage : 9|9@1+ (0.0008823529411764706,0.25) [0|0] "" Vector__XXX
 SG_ DI_track1MinVoltage30s : 18|12@1+ (0.0011355311355311355,0.65) [0|0] "" Vector__XXX
 SG_ DI_track1MaxVoltage30s : 32|12@1+ (0.0011355311355311355,0.65) [0|0] "" Vector__XXX
 SG_ DI_track1MinVoltageBrakePress : 44|12@1+ (0.0011355311355311355,0.65) [0|0] "" Vector__XXX
 SG_ DI_idleOffsetLearningActive : 56|1@1+ (1,0) [0|0] "" Vector__XXX

BO_ 847 APP_gnssReceiverRaw: 8 Vector__XXX
 SG_ APP_gnssReceiverRawGroundSpeed : 0|20@1- (1,0) [0|0] "" Vector__XXX
 SG_ APP_gnssReceiverRawEHPE : 20|16@1+ (1,0) [0|0] "" Vector__XXX
 SG_ APP_gnssReceiverRawNumSatellitesUsed : 36|8@1+ (1,0) [0|0] "" Vector__XXX
 SG_ APP_gnssReceiverRawDistinctDataIndex : 44|3@1+ (1,0) [0|0] "" Vector__XXX
 SG_ APP_gnssReceiverRawNormalizedCovariance : 48|8@1+ (0.1,0) [0|0] "" Vector__XXX

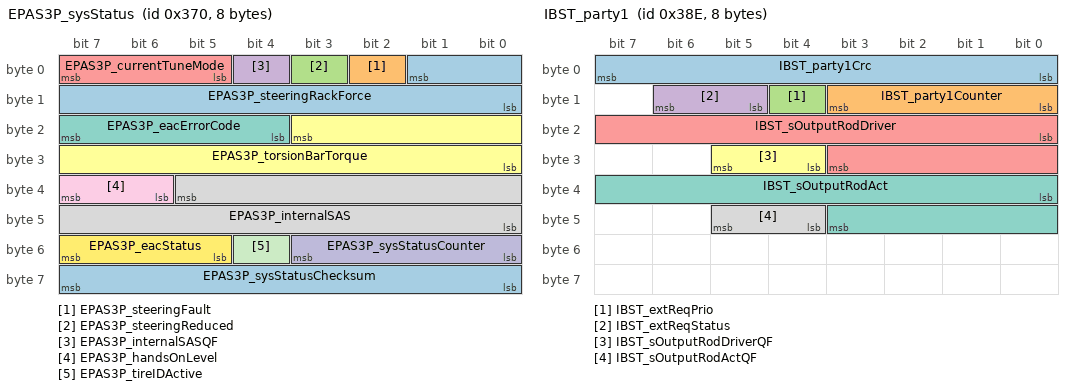
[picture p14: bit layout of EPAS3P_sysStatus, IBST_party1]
BO_ 880 EPAS3P_sysStatus: 8 Vector__XXX
 SG_ EPAS3P_steeringRackForce : 1|10@0+ (50,-25575) [0|0] "" Vector__XXX
 SG_ EPAS3P_steeringFault : 2|1@0+ (1,0) [0|0] "" Vector__XXX
 SG_ EPAS3P_steeringReduced : 3|1@0+ (1,0) [0|0] "" Vector__XXX
 SG_ EPAS3P_internalSASQF : 4|1@0+ (1,0) [0|0] "" Vector__XXX
 SG_ EPAS3P_currentTuneMode : 7|3@0+ (1,0) [0|0] "" Vector__XXX
 SG_ EPAS3P_torsionBarTorque : 19|12@0+ (0.01,-20.5) [0|0] "" Vector__XXX
 SG_ EPAS3P_eacErrorCode : 23|4@0+ (1,0) [0|0] "" Vector__XXX
 SG_ EPAS3P_internalSAS : 37|14@0+ (0.1,-819.2) [0|0] "" Vector__XXX
 SG_ EPAS3P_handsOnLevel : 39|2@0+ (1,0) [0|0] "" Vector__XXX
 SG_ EPAS3P_sysStatusCounter : 51|4@0+ (1,0) [0|0] "" Vector__XXX
 SG_ EPAS3P_tireIDActive : 52|1@1+ (1,0) [0|0] "" Vector__XXX
 SG_ EPAS3P_eacStatus : 55|3@0+ (1,0) [0|0] "" Vector__XXX
 SG_ EPAS3P_sysStatusChecksum : 63|8@0+ (1,0) [0|0] "" Vector__XXX

BO_ 901 ESP_offsets: 8 Vector__XXX
 SG_ ESP_latAccelOffsetComp : 0|8@1+ (0.02,-2.25) [0|0] "" Vector__XXX
 SG_ ESP_longAccelOffsetComp : 8|8@1+ (0.02,-2.25) [0|0] "" Vector__XXX
 SG_ ESP_yawrateOffsetComp : 16|9@1+ (0.0009765625,-0.24) [0|0] "" Vector__XXX
 SG_ ESP_masterCylOffsetComp : 25|7@1+ (0.25,-16) [0|0] "" Vector__XXX
 SG_ ESP_offsetsCounter : 52|4@1+ (1,0) [0|0] "" Vector__XXX
 SG_ ESP_offsetsChecksum : 56|8@1+ (1,0) [0|0] "" Vector__XXX

BO_ 905 DAS_status2: 8 Vector__XXX
 SG_ DAS_accSpeedLimit : 0|9@1+ (0.4,0) [0|0] "" Vector__XXX
 SG_ DAS_versionIdentifier : 9|1@1+ (1,0) [0|0] "" Vector__XXX
 SG_ DAS_pmmObstacleSeverity : 10|3@1+ (1,0) [0|0] "" Vector__XXX
 SG_ DAS_pmmLoggingRequest : 13|1@1+ (1,0) [0|0] "" Vector__XXX
 SG_ DAS_activationFailureStatus : 14|2@1+ (1,0) [0|0] "" Vector__XXX
 SG_ DAS_pmmUltrasonicsFaultReason : 16|3@1+ (1,0) [0|0] "" Vector__XXX
 SG_ DAS_pmmRadarFaultReason : 19|2@1+ (1,0) [0|0] "" Vector__XXX
 SG_ DAS_pmmSysFaultReason : 21|3@1+ (1,0) [0|0] "" Vector__XXX
 SG_ DAS_pmmCameraFaultReason : 24|2@1+ (1,0) [0|0] "" Vector__XXX
 SG_ DAS_ACC_report : 26|5@1+ (1,0) [0|0] "" Vector__XXX
 SG_ DAS_relaxCruiseLimits : 31|1@1+ (1,0) [0|0] "" Vector__XXX
 SG_ DAS_csaState : 32|2@1+ (1,0) [0|0] "" Vector__XXX
 SG_ DAS_radarTelemetry : 34|2@1+ (1,0) [0|0] "" Vector__XXX
 SG_ DAS_robState : 36|2@1+ (1,0) [0|0] "" Vector__XXX
 SG_ DAS_driverInteractionLevel : 38|2@1+ (1,0) [0|0] "" Vector__XXX
 SG_ DAS_ppOffsetDesiredRamp : 40|8@1+ (0.01,-1.28) [0|0] "" Vector__XXX
 SG_ DAS_longCollisionWarning : 48|4@1+ (1,0) [0|0] "" Vector__XXX
 SG_ DAS_status2Counter : 52|4@1+ (1,0) [0|0] "" Vector__XXX
 SG_ DAS_status2Checksum : 56|8@1+ (1,0) [0|0] "" Vector__XXX

BO_ 907 ESP_party1: 8 Vector__XXX
 SG_ ESP_party1Crc : 0|8@1+ (1,0) [0|0] "" Vector__XXX
 SG_ ESP_party1Counter : 8|4@1+ (1,0) [0|0] "" Vector__XXX
 SG_ ESP_ignitionOn : 12|1@1+ (1,0) [0|0] "" Vector__XXX
 SG_ ESP_privateVehicleSpeedQF : 14|2@1+ (1,0) [0|0] "" Vector__XXX
 SG_ ESP_privateVehicleSpeed : 16|8@1+ (0.4,0) [0|0] "" Vector__XXX
 SG_ ESP_pEstMax : 24|8@1+ (1,0) [0|0] "" Vector__XXX

BO_ 908 ESP_party2: 8 Vector__XXX
 SG_ ESP_party2Crc : 0|8@1+ (1,0) [0|0] "" Vector__XXX
 SG_ ESP_party2Counter : 8|4@1+ (1,0) [0|0] "" Vector__XXX
 SG_ ESP_qTargetExternalQF : 14|2@1+ (1,0) [0|0] "" Vector__XXX
 SG_ ESP_qTargetExternal : 16|16@1+ (0.0078125,-252) [0|0] "" Vector__XXX

BO_ 909 ESP_party3: 8 Vector__XXX
 SG_ ESP_party3Crc : 0|8@1+ (1,0) [0|0] "" Vector__XXX
 SG_ ESP_party3Counter : 8|4@1+ (1,0) [0|0] "" Vector__XXX
 SG_ ESP_absActive : 12|1@1+ (1,0) [0|0] "" Vector__XXX
 SG_ ESP_brakeMasterCylPress : 44|10@1+ (0.3,-30) [0|0] "" Vector__XXX
 SG_ ESP_brakeMasterCylPressQF : 54|2@1+ (1,0) [0|0] "" Vector__XXX

BO_ 910 IBST_party1: 8 Vector__XXX
 SG_ IBST_party1Crc : 0|8@1+ (1,0) [0|0] "" Vector__XXX
 SG_ IBST_party1Counter : 8|4@1+ (1,0) [0|0] "" Vector__XXX
 SG_ IBST_extReqPrio : 12|1@1+ (1,0) [0|0] "" Vector__XXX
 SG_ IBST_extReqStatus : 13|2@1+ (1,0) [0|0] "" Vector__XXX
 SG_ IBST_sOutputRodDriver : 16|12@1+ (0.015625,-5) [0|0] "" Vector__XXX
 SG_ IBST_sOutputRodDriverQF : 28|2@1+ (1,0) [0|0] "" Vector__XXX
 SG_ IBST_sOutputRodAct : 32|12@1+ (0.015625,-5) [0|0] "" Vector__XXX
 SG_ IBST_sOutputRodActQF : 44|2@1+ (1,0) [0|0] "" Vector__XXX

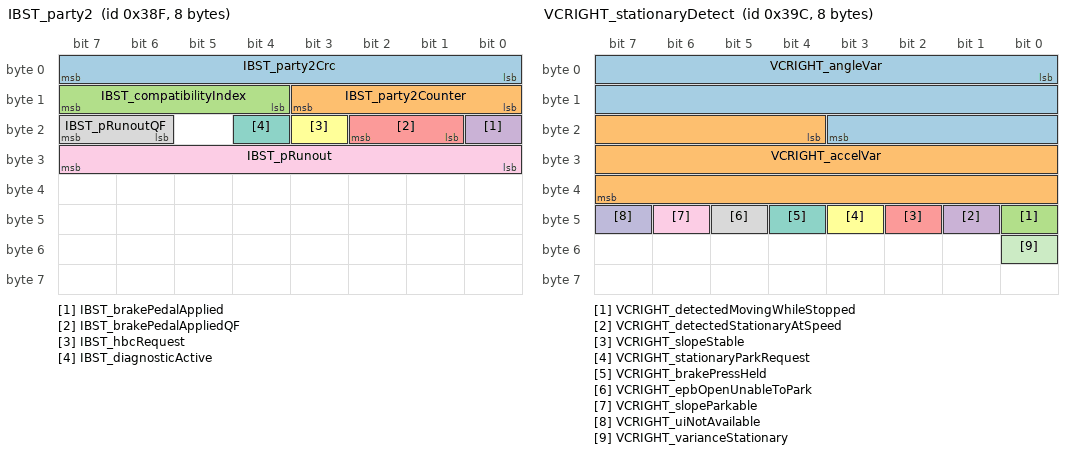
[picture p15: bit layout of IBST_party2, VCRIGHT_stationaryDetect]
BO_ 911 IBST_party2: 8 Vector__XXX
 SG_ IBST_party2Crc : 0|8@1+ (1,0) [0|0] "" Vector__XXX
 SG_ IBST_party2Counter : 8|4@1+ (1,0) [0|0] "" Vector__XXX
 SG_ IBST_compatibilityIndex : 12|4@1+ (1,0) [0|0] "" Vector__XXX
 SG_ IBST_brakePedalApplied : 16|1@1+ (1,0) [0|0] "" Vector__XXX
 SG_ IBST_brakePedalAppliedQF : 17|2@1+ (1,0) [0|0] "" Vector__XXX
 SG_ IBST_hbcRequest : 19|1@1+ (1,0) [0|0] "" Vector__XXX
 SG_ IBST_diagnosticActive : 20|1@1+ (1,0) [0|0] "" Vector__XXX
 SG_ IBST_pRunoutQF : 22|2@1+ (1,0) [0|0] "" Vector__XXX
 SG_ IBST_pRunout : 24|8@1+ (1,0) [0|0] "" Vector__XXX

BO_ 914 EPAS3P_alertMatrix: 8 Vector__XXX
 SG_ EPAS3P_matrixIndex M : 0|4@1+ (1,0) [0|0] "" Vector__XXX
 SG_ EPAS3P_a001_sent1Mia m0 : 4|1@1+ (1,0) [0|0] "" Vector__XXX
 SG_ EPAS3P_a061_bridgeUv m1 : 4|1@1+ (1,0) [0|0] "" Vector__XXX
 SG_ EPAS3P_a121_pvtEcuStatCrcError m2 : 4|1@1+ (1,0) [0|0] "" Vector__XXX
 SG_ EPAS3P_a002_sent1Error m0 : 5|1@1+ (1,0) [0|0] "" Vector__XXX
 SG_ EPAS3P_a062_assistCorrError m1 : 5|1@1+ (1,0) [0|0] "" Vector__XXX
 SG_ EPAS3P_a122_olpActive m2 : 5|1@1+ (1,0) [0|0] "" Vector__XXX
 SG_ EPAS3P_a003_trqSens1Supply m0 : 6|1@1+ (1,0) [0|0] "" Vector__XXX
 SG_ EPAS3P_a063_dampCorrError m1 : 6|1@1+ (1,0) [0|0] "" Vector__XXX
 SG_ EPAS3P_a123_combEcu2StatFail m2 : 6|1@1+ (1,0) [0|0] "" Vector__XXX
 SG_ EPAS3P_a004_trqSens1Eeprom m0 : 7|1@1+ (1,0) [0|0] "" Vector__XXX
 SG_ EPAS3P_a064_phaseCompCorrError m1 : 7|1@1+ (1,0) [0|0] "" Vector__XXX
 SG_ EPAS3P_a124_tempSensStuckInRange m2 : 7|1@1+ (1,0) [0|0] "" Vector__XXX
 SG_ EPAS3P_a005_sent2Mia m0 : 8|1@1+ (1,0) [0|0] "" Vector__XXX
 SG_ EPAS3P_a065_trqTarCorrError m1 : 8|1@1+ (1,0) [0|0] "" Vector__XXX
 SG_ EPAS3P_a125_trqSensTrimOutRange m2 : 8|1@1+ (1,0) [0|0] "" Vector__XXX
 SG_ EPAS3P_a006_sent2Error m0 : 9|1@1+ (1,0) [0|0] "" Vector__XXX
 SG_ EPAS3P_a066_returnCorrError m1 : 9|1@1+ (1,0) [0|0] "" Vector__XXX
 SG_ EPAS3P_a126_apsMia m2 : 9|1@1+ (1,0) [0|0] "" Vector__XXX
 SG_ EPAS3P_a007_trqSens2Supply m0 : 10|1@1+ (1,0) [0|0] "" Vector__XXX
 SG_ EPAS3P_a067_yawDampCorrError m1 : 10|1@1+ (1,0) [0|0] "" Vector__XXX
 SG_ EPAS3P_a127_apsCntError m2 : 10|1@1+ (1,0) [0|0] "" Vector__XXX
 SG_ EPAS3P_a008_trqSens2Eeprom m0 : 11|1@1+ (1,0) [0|0] "" Vector__XXX
 SG_ EPAS3P_a068_hystCorrError m1 : 11|1@1+ (1,0) [0|0] "" Vector__XXX
 SG_ EPAS3P_a128_apsCsError m2 : 11|1@1+ (1,0) [0|0] "" Vector__XXX
 SG_ EPAS3P_a009_sentDiff m0 : 12|1@1+ (1,0) [0|0] "" Vector__XXX
 SG_ EPAS3P_a069_eacCorrError m1 : 12|1@1+ (1,0) [0|0] "" Vector__XXX
 SG_ EPAS3P_a129_combEcu1StatFail m2 : 12|1@1+ (1,0) [0|0] "" Vector__XXX
 SG_ EPAS3P_a010_trqSensCalError m0 : 13|1@1+ (1,0) [0|0] "" Vector__XXX
 SG_ EPAS3P_a070_hodCorrError m1 : 13|1@1+ (1,0) [0|0] "" Vector__XXX
 SG_ EPAS3P_a130_sasOffsetNotCal m2 : 13|1@1+ (1,0) [0|0] "" Vector__XXX
 SG_ EPAS3P_a011_currentSensError m0 : 14|1@1+ (1,0) [0|0] "" Vector__XXX
 SG_ EPAS3P_a071_vehSpdCorrError m1 : 14|1@1+ (1,0) [0|0] "" Vector__XXX
 SG_ EPAS3P_a131_phaseFeedbackError m2 : 14|1@1+ (1,0) [0|0] "" Vector__XXX
 SG_ EPAS3P_a012_currentSensCalError m0 : 15|1@1+ (1,0) [0|0] "" Vector__XXX
 SG_ EPAS3P_a072_motFeedFwdError m1 : 15|1@1+ (1,0) [0|0] "" Vector__XXX
 SG_ EPAS3P_a132_motFeedFwdCounter25 m2 : 15|1@1+ (1,0) [0|0] "" Vector__XXX
 SG_ EPAS3P_a013_gateDriveError m0 : 16|1@1+ (1,0) [0|0] "" Vector__XXX
 SG_ EPAS3P_a073_motParEstError m1 : 16|1@1+ (1,0) [0|0] "" Vector__XXX
 SG_ EPAS3P_a133_motFeedFwdCounter50 m2 : 16|1@1+ (1,0) [0|0] "" Vector__XXX
 SG_ EPAS3P_a014_gateDriveTxError m0 : 17|1@1+ (1,0) [0|0] "" Vector__XXX
 SG_ EPAS3P_a074_overHeatProtect m1 : 17|1@1+ (1,0) [0|0] "" Vector__XXX
 SG_ EPAS3P_a134_motFeedFwdCounter85 m2 : 17|1@1+ (1,0) [0|0] "" Vector__XXX
 SG_ EPAS3P_a015_gateDriveEeprom m0 : 18|1@1+ (1,0) [0|0] "" Vector__XXX
 SG_ EPAS3P_a075_fspPwrCut m1 : 18|1@1+ (1,0) [0|0] "" Vector__XXX
 SG_ EPAS3P_a135_piCtrlCounter25 m2 : 18|1@1+ (1,0) [0|0] "" Vector__XXX
 SG_ EPAS3P_a016_phaseUhighUv m0 : 19|1@1+ (1,0) [0|0] "" Vector__XXX
 SG_ EPAS3P_a076_tempSensOutofRange m1 : 19|1@1+ (1,0) [0|0] "" Vector__XXX
 SG_ EPAS3P_a136_piCtrlCounter50 m2 : 19|1@1+ (1,0) [0|0] "" Vector__XXX
 SG_ EPAS3P_a017_phaseUlowUv m0 : 20|1@1+ (1,0) [0|0] "" Vector__XXX
 SG_ EPAS3P_a077_highSideFetError m1 : 20|1@1+ (1,0) [0|0] "" Vector__XXX
 SG_ EPAS3P_a137_piCtrlCounter85 m2 : 20|1@1+ (1,0) [0|0] "" Vector__XXX
 SG_ EPAS3P_a018_phaseVhighUv m0 : 21|1@1+ (1,0) [0|0] "" Vector__XXX
 SG_ EPAS3P_a078_phaseDisconnectError m1 : 21|1@1+ (1,0) [0|0] "" Vector__XXX
 SG_ EPAS3P_a144_diSpdMia m2 : 21|1@1+ (1,0) [0|0] "" Vector__XXX
 SG_ EPAS3P_a019_phaseVlowUv m0 : 22|1@1+ (1,0) [0|0] "" Vector__XXX
 SG_ EPAS3P_a079_backupCurrentPlaus m1 : 22|1@1+ (1,0) [0|0] "" Vector__XXX
 SG_ EPAS3P_a145_diSpdCntError m2 : 22|1@1+ (1,0) [0|0] "" Vector__XXX
 SG_ EPAS3P_a020_phaseWhighUv m0 : 23|1@1+ (1,0) [0|0] "" Vector__XXX
 SG_ EPAS3P_a080_ecuInitArbError m1 : 23|1@1+ (1,0) [0|0] "" Vector__XXX
 SG_ EPAS3P_a146_diSpdCsError m2 : 23|1@1+ (1,0) [0|0] "" Vector__XXX
 SG_ EPAS3P_a021_phaseWlowUv m0 : 24|1@1+ (1,0) [0|0] "" Vector__XXX
 SG_ EPAS3P_a081_coggCompError m1 : 24|1@1+ (1,0) [0|0] "" Vector__XXX
 SG_ EPAS3P_a147_backupVehSpeed m2 : 24|1@1+ (1,0) [0|0] "" Vector__XXX
 SG_ EPAS3P_a022_phaseUhighOv m0 : 25|1@1+ (1,0) [0|0] "" Vector__XXX
 SG_ EPAS3P_a082_polarityCalError m1 : 25|1@1+ (1,0) [0|0] "" Vector__XXX
 SG_ EPAS3P_a148_vMaxAssist m2 : 25|1@1+ (1,0) [0|0] "" Vector__XXX
 SG_ EPAS3P_a023_phaseUlowOv m0 : 26|1@1+ (1,0) [0|0] "" Vector__XXX
 SG_ EPAS3P_a083_crcMismatch m1 : 26|1@1+ (1,0) [0|0] "" Vector__XXX
 SG_ EPAS3P_a149_currentSensPathSwitch m2 : 26|1@1+ (1,0) [0|0] "" Vector__XXX
 SG_ EPAS3P_a024_phaseVhighOv m0 : 27|1@1+ (1,0) [0|0] "" Vector__XXX
 SG_ EPAS3P_a084_eacCancelled m1 : 27|1@1+ (1,0) [0|0] "" Vector__XXX
 SG_ EPAS3P_a150_currentSensOffsetDetect m2 : 27|1@1+ (1,0) [0|0] "" Vector__XXX
 SG_ EPAS3P_a025_phaseVlowOv m0 : 28|1@1+ (1,0) [0|0] "" Vector__XXX
 SG_ EPAS3P_a085_canBusOff m1 : 28|1@1+ (1,0) [0|0] "" Vector__XXX
 SG_ EPAS3P_a151_dcsCboot m2 : 28|1@1+ (1,0) [0|0] "" Vector__XXX
 SG_ EPAS3P_a026_phaseWhighOv m0 : 29|1@1+ (1,0) [0|0] "" Vector__XXX
 SG_ EPAS3P_a086_dasMia m1 : 29|1@1+ (1,0) [0|0] "" Vector__XXX
 SG_ EPAS3P_a152_dcsDiagReg m2 : 29|1@1+ (1,0) [0|0] "" Vector__XXX
 SG_ EPAS3P_a027_phaseWlowOv m0 : 30|1@1+ (1,0) [0|0] "" Vector__XXX
 SG_ EPAS3P_a087_dasCntError m1 : 30|1@1+ (1,0) [0|0] "" Vector__XXX
 SG_ EPAS3P_a153_dcsInitOffset m2 : 30|1@1+ (1,0) [0|0] "" Vector__XXX
 SG_ EPAS3P_a028_phaseUbootUv m0 : 31|1@1+ (1,0) [0|0] "" Vector__XXX
 SG_ EPAS3P_a088_dasCsError m1 : 31|1@1+ (1,0) [0|0] "" Vector__XXX
 SG_ EPAS3P_a154_assistTorqueDisabled m2 : 31|1@1+ (1,0) [0|0] "" Vector__XXX
 SG_ EPAS3P_a029_phaseVbootUv m0 : 32|1@1+ (1,0) [0|0] "" Vector__XXX
 SG_ EPAS3P_a089_espWsMia m1 : 32|1@1+ (1,0) [0|0] "" Vector__XXX
 SG_ EPAS3P_a155_backupEacActive m2 : 32|1@1+ (1,0) [0|0] "" Vector__XXX
 SG_ EPAS3P_a030_phaseWbootUv m0 : 33|1@1+ (1,0) [0|0] "" Vector__XXX
 SG_ EPAS3P_a090_espWsCntError m1 : 33|1@1+ (1,0) [0|0] "" Vector__XXX
 SG_ EPAS3P_a156_angleSensorDivergence m2 : 33|1@1+ (1,0) [0|0] "" Vector__XXX
 SG_ EPAS3P_a031_abnormalShutdown m0 : 34|1@1+ (1,0) [0|0] "" Vector__XXX
 SG_ EPAS3P_a091_espWsCsError m1 : 34|1@1+ (1,0) [0|0] "" Vector__XXX
 SG_ EPAS3P_a032_vRegOutputUv m0 : 35|1@1+ (1,0) [0|0] "" Vector__XXX
 SG_ EPAS3P_a092_espWrMia m1 : 35|1@1+ (1,0) [0|0] "" Vector__XXX
 SG_ EPAS3P_a033_vRegOutputOv m0 : 36|1@1+ (1,0) [0|0] "" Vector__XXX
 SG_ EPAS3P_a093_espWrCntError m1 : 36|1@1+ (1,0) [0|0] "" Vector__XXX
 SG_ EPAS3P_a034_vRegError m0 : 37|1@1+ (1,0) [0|0] "" Vector__XXX
 SG_ EPAS3P_a094_espWrCsError m1 : 37|1@1+ (1,0) [0|0] "" Vector__XXX
 SG_ EPAS3P_a035_vbbSupplyUv m0 : 38|1@1+ (1,0) [0|0] "" Vector__XXX
 SG_ EPAS3P_a095_espWsStatus m1 : 38|1@1+ (1,0) [0|0] "" Vector__XXX
 SG_ EPAS3P_a036_vbbSupplyOv m0 : 39|1@1+ (1,0) [0|0] "" Vector__XXX
 SG_ EPAS3P_a096_rcmMia m1 : 39|1@1+ (1,0) [0|0] "" Vector__XXX
 SG_ EPAS3P_a037_motPos1ParityError m0 : 40|1@1+ (1,0) [0|0] "" Vector__XXX
 SG_ EPAS3P_a097_rcmCntError m1 : 40|1@1+ (1,0) [0|0] "" Vector__XXX
 SG_ EPAS3P_a038_motPos1Uv m0 : 41|1@1+ (1,0) [0|0] "" Vector__XXX
 SG_ EPAS3P_a098_rcmCsError m1 : 41|1@1+ (1,0) [0|0] "" Vector__XXX
 SG_ EPAS3P_a039_motPos1MagnetMia m0 : 42|1@1+ (1,0) [0|0] "" Vector__XXX
 SG_ EPAS3P_a099_yawRateStatus m1 : 42|1@1+ (1,0) [0|0] "" Vector__XXX
 SG_ EPAS3P_a040_motPos1LogicError m0 : 43|1@1+ (1,0) [0|0] "" Vector__XXX
 SG_ EPAS3P_a100_diMia m1 : 43|1@1+ (1,0) [0|0] "" Vector__XXX
 SG_ EPAS3P_a041_motPos1tempError m0 : 44|1@1+ (1,0) [0|0] "" Vector__XXX
 SG_ EPAS3P_a101_diCntError m1 : 44|1@1+ (1,0) [0|0] "" Vector__XXX
 SG_ EPAS3P_a042_motPos2ParityError m0 : 45|1@1+ (1,0) [0|0] "" Vector__XXX
 SG_ EPAS3P_a102_diCsError m1 : 45|1@1+ (1,0) [0|0] "" Vector__XXX
 SG_ EPAS3P_a043_motPos2Uv m0 : 46|1@1+ (1,0) [0|0] "" Vector__XXX
 SG_ EPAS3P_a103_vcFrontMia m1 : 46|1@1+ (1,0) [0|0] "" Vector__XXX
 SG_ EPAS3P_a044_motPos2MagnetMia m0 : 47|1@1+ (1,0) [0|0] "" Vector__XXX
 SG_ EPAS3P_a104_vcFrontCntError m1 : 47|1@1+ (1,0) [0|0] "" Vector__XXX
 SG_ EPAS3P_a045_motPos2LogicError m0 : 48|1@1+ (1,0) [0|0] "" Vector__XXX
 SG_ EPAS3P_a105_vcFrontCsError m1 : 48|1@1+ (1,0) [0|0] "" Vector__XXX
 SG_ EPAS3P_a046_motPos2tempError m0 : 49|1@1+ (1,0) [0|0] "" Vector__XXX
 SG_ EPAS3P_a106_vcFrontTempMia m1 : 49|1@1+ (1,0) [0|0] "" Vector__XXX
 SG_ EPAS3P_a047_motPosCorrError m0 : 50|1@1+ (1,0) [0|0] "" Vector__XXX
 SG_ EPAS3P_a107_uiTuneReqMia m1 : 50|1@1+ (1,0) [0|0] "" Vector__XXX
 SG_ EPAS3P_a048_motPosCalError m0 : 51|1@1+ (1,0) [0|0] "" Vector__XXX
 SG_ EPAS3P_a108_uiTuneReqCntError m1 : 51|1@1+ (1,0) [0|0] "" Vector__XXX
 SG_ EPAS3P_a049_piCtrlError m0 : 52|1@1+ (1,0) [0|0] "" Vector__XXX
 SG_ EPAS3P_a109_uiTuneReqCsError m1 : 52|1@1+ (1,0) [0|0] "" Vector__XXX
 SG_ EPAS3P_a050_mcuSmuError m0 : 53|1@1+ (1,0) [0|0] "" Vector__XXX
 SG_ EPAS3P_a110_sasMia m1 : 53|1@1+ (1,0) [0|0] "" Vector__XXX
 SG_ EPAS3P_a051_mcuSupError m0 : 54|1@1+ (1,0) [0|0] "" Vector__XXX
 SG_ EPAS3P_a111_sasCntError m1 : 54|1@1+ (1,0) [0|0] "" Vector__XXX
 SG_ EPAS3P_a052_intWatchdogError m0 : 55|1@1+ (1,0) [0|0] "" Vector__XXX
 SG_ EPAS3P_a112_sasCsError m1 : 55|1@1+ (1,0) [0|0] "" Vector__XXX
 SG_ EPAS3P_a053_extWatchdogError m0 : 56|1@1+ (1,0) [0|0] "" Vector__XXX
 SG_ EPAS3P_a113_sasStatusError m1 : 56|1@1+ (1,0) [0|0] "" Vector__XXX
 SG_ EPAS3P_a054_memoryProtectError m0 : 57|1@1+ (1,0) [0|0] "" Vector__XXX
 SG_ EPAS3P_a114_gtwConfigMia m1 : 57|1@1+ (1,0) [0|0] "" Vector__XXX
 SG_ EPAS3P_a055_floatPointError m0 : 58|1@1+ (1,0) [0|0] "" Vector__XXX
 SG_ EPAS3P_a115_ecuStatMia m1 : 58|1@1+ (1,0) [0|0] "" Vector__XXX
 SG_ EPAS3P_a056_battUv m0 : 59|1@1+ (1,0) [0|0] "" Vector__XXX
 SG_ EPAS3P_a116_ecuStatCntError m1 : 59|1@1+ (1,0) [0|0] "" Vector__XXX
 SG_ EPAS3P_a057_battUvReduced m0 : 60|1@1+ (1,0) [0|0] "" Vector__XXX
 SG_ EPAS3P_a117_ecuStatCrcError m1 : 60|1@1+ (1,0) [0|0] "" Vector__XXX
 SG_ EPAS3P_a058_battOv m0 : 61|1@1+ (1,0) [0|0] "" Vector__XXX
 SG_ EPAS3P_a118_privateBusOff m1 : 61|1@1+ (1,0) [0|0] "" Vector__XXX
 SG_ EPAS3P_a059_battOvReduced m0 : 62|1@1+ (1,0) [0|0] "" Vector__XXX
 SG_ EPAS3P_a119_pvtEcuStatMia m1 : 62|1@1+ (1,0) [0|0] "" Vector__XXX
 SG_ EPAS3P_a060_battBridgeDiff m0 : 63|1@1+ (1,0) [0|0] "" Vector__XXX
 SG_ EPAS3P_a120_pvtEcuStatCntError m1 : 63|1@1+ (1,0) [0|0] "" Vector__XXX

BO_ 919 EPASTP_alertMatrix: 8 Vector__XXX
 SG_ EPASTP_matrixIndex M : 0|4@1+ (1,0) [0|0] "" Vector__XXX
 SG_ EPASTP_a001_adcCalibrationOrInitFail m0 : 4|1@1+ (1,0) [0|0] "" Vector__XXX
 SG_ EPASTP_a061_amIntSerialErr m1 : 4|1@1+ (1,0) [0|0] "" Vector__XXX
 SG_ EPASTP_a121_mcusscMbistEccErr m2 : 4|1@1+ (1,0) [0|0] "" Vector__XXX
 SG_ EPASTP_a181_dmDeadlineViolationC1 m3 : 4|1@1+ (1,0) [0|0] "" Vector__XXX
 SG_ EPASTP_a242_gtwConfigMia m4 : 4|1@1+ (1,0) [0|0] "" Vector__XXX
 SG_ EPASTP_a002_adcMuxErr m0 : 5|1@1+ (1,0) [0|0] "" Vector__XXX
 SG_ EPASTP_a062_amPhaseBridgeCheck m1 : 5|1@1+ (1,0) [0|0] "" Vector__XXX
 SG_ EPASTP_a122_pcpBridgeFetShort m2 : 5|1@1+ (1,0) [0|0] "" Vector__XXX
 SG_ EPASTP_a182_mcdInputMia m3 : 5|1@1+ (1,0) [0|0] "" Vector__XXX
 SG_ EPASTP_a243_rcmCntError m4 : 5|1@1+ (1,0) [0|0] "" Vector__XXX
 SG_ EPASTP_a003_pspInvalidParamset m0 : 6|1@1+ (1,0) [0|0] "" Vector__XXX
 SG_ EPASTP_a063_amIntRegulatorErr m1 : 6|1@1+ (1,0) [0|0] "" Vector__XXX
 SG_ EPASTP_a123_imcmCommErr m2 : 6|1@1+ (1,0) [0|0] "" Vector__XXX
 SG_ EPASTP_a183_sbchCommErrSbcToMcu m3 : 6|1@1+ (1,0) [0|0] "" Vector__XXX
 SG_ EPASTP_a244_rcmCsError m4 : 6|1@1+ (1,0) [0|0] "" Vector__XXX
 SG_ EPASTP_a004_scpInputMia m0 : 7|1@1+ (1,0) [0|0] "" Vector__XXX
 SG_ EPASTP_a064_amBridgeShort m1 : 7|1@1+ (1,0) [0|0] "" Vector__XXX
 SG_ EPASTP_a124_mcusscMbistEccTransientErr m2 : 7|1@1+ (1,0) [0|0] "" Vector__XXX
 SG_ EPASTP_a184_sbcmCommBufferOverflow m3 : 7|1@1+ (1,0) [0|0] "" Vector__XXX
 SG_ EPASTP_a245_rcmMia m4 : 7|1@1+ (1,0) [0|0] "" Vector__XXX
 SG_ EPASTP_a005_scpUnknownResetSource m0 : 8|1@1+ (1,0) [0|0] "" Vector__XXX
 SG_ EPASTP_a065_amGduJuncTemp m1 : 8|1@1+ (1,0) [0|0] "" Vector__XXX
 SG_ EPASTP_a125_mcusscMbistMiaErr m2 : 8|1@1+ (1,0) [0|0] "" Vector__XXX
 SG_ EPASTP_a185_sbcscpQAWatchdogReset m3 : 8|1@1+ (1,0) [0|0] "" Vector__XXX
 SG_ EPASTP_a246_sccmCntError m4 : 8|1@1+ (1,0) [0|0] "" Vector__XXX
 SG_ EPASTP_a006_swrhResetByInvalidErrid m0 : 9|1@1+ (1,0) [0|0] "" Vector__XXX
 SG_ EPASTP_a066_amVoltQfErr m1 : 9|1@1+ (1,0) [0|0] "" Vector__XXX
 SG_ EPASTP_a126_mcusscMonbistMiaErr m2 : 9|1@1+ (1,0) [0|0] "" Vector__XXX
 SG_ EPASTP_a186_wdhCommBufferOverflow m3 : 9|1@1+ (1,0) [0|0] "" Vector__XXX
 SG_ EPASTP_a247_sccmCsError m4 : 9|1@1+ (1,0) [0|0] "" Vector__XXX
 SG_ EPASTP_a007_tsmcCoreTempDiff m0 : 10|1@1+ (1,0) [0|0] "" Vector__XXX
 SG_ EPASTP_a067_tspmPowermoduleTempImplausible m1 : 10|1@1+ (1,0) [0|0] "" Vector__XXX
 SG_ EPASTP_a127_exchAdditionalExceptionAfterRst m2 : 10|1@1+ (1,0) [0|0] "" Vector__XXX
 SG_ EPASTP_a187_epmVoltFail m3 : 10|1@1+ (1,0) [0|0] "" Vector__XXX
 SG_ EPASTP_a248_sccmMia m4 : 10|1@1+ (1,0) [0|0] "" Vector__XXX
 SG_ EPASTP_a008_psdcPlatformShutdown m0 : 11|1@1+ (1,0) [0|0] "" Vector__XXX
 SG_ EPASTP_a068_rsthCoreRedundancyErr m1 : 11|1@1+ (1,0) [0|0] "" Vector__XXX
 SG_ EPASTP_a128_exchExceptionStopRestart m2 : 11|1@1+ (1,0) [0|0] "" Vector__XXX
 SG_ EPASTP_a188_epmCommBufferOverflow m3 : 11|1@1+ (1,0) [0|0] "" Vector__XXX
 SG_ EPASTP_a249_uiTuneReqCntError m4 : 11|1@1+ (1,0) [0|0] "" Vector__XXX
 SG_ EPASTP_a009_mcusscLbistPermanentFail m0 : 12|1@1+ (1,0) [0|0] "" Vector__XXX
 SG_ EPASTP_a069_rsthCoreTempOutOfRangeHwCheck m1 : 12|1@1+ (1,0) [0|0] "" Vector__XXX
 SG_ EPASTP_a129_exchAdditionalExceptionStopRestart m2 : 12|1@1+ (1,0) [0|0] "" Vector__XXX
 SG_ EPASTP_a189_sbchCommErrMcuToSbc m3 : 12|1@1+ (1,0) [0|0] "" Vector__XXX
 SG_ EPASTP_a250_uiTuneReqCsError m4 : 12|1@1+ (1,0) [0|0] "" Vector__XXX
 SG_ EPASTP_a010_svcIncompatibleSwVersions m0 : 13|1@1+ (1,0) [0|0] "" Vector__XXX
 SG_ EPASTP_a070_rsthInternalLowVolt m1 : 13|1@1+ (1,0) [0|0] "" Vector__XXX
 SG_ EPASTP_a130_mrccConfigCsErrorErr m2 : 13|1@1+ (1,0) [0|0] "" Vector__XXX
 SG_ EPASTP_a190_sbchCommBufferOverflow m3 : 13|1@1+ (1,0) [0|0] "" Vector__XXX
 SG_ EPASTP_a251_uiTuneReqMia m4 : 13|1@1+ (1,0) [0|0] "" Vector__XXX
 SG_ EPASTP_a011_mcusscMonbistErr m0 : 14|1@1+ (1,0) [0|0] "" Vector__XXX
 SG_ EPASTP_a071_rsthInternalHighVolt m1 : 14|1@1+ (1,0) [0|0] "" Vector__XXX
 SG_ EPASTP_a131_exchGuardedResetAfterPartitionStop m2 : 14|1@1+ (1,0) [0|0] "" Vector__XXX
 SG_ EPASTP_a191_sbcscpVcp2VucVoltFail m3 : 14|1@1+ (1,0) [0|0] "" Vector__XXX
 SG_ EPASTP_a252_vcFrontCntError m4 : 14|1@1+ (1,0) [0|0] "" Vector__XXX
 SG_ EPASTP_a012_mcusscMbistEccErr m0 : 15|1@1+ (1,0) [0|0] "" Vector__XXX
 SG_ EPASTP_a072_rsthFlashUncorrEccOrOvfl m1 : 15|1@1+ (1,0) [0|0] "" Vector__XXX
 SG_ EPASTP_a132_mcusscNotSupportedMcu m2 : 15|1@1+ (1,0) [0|0] "" Vector__XXX
 SG_ EPASTP_a192_osumC0CsaNearFull m3 : 15|1@1+ (1,0) [0|0] "" Vector__XXX
 SG_ EPASTP_a253_vcFrontCsError m4 : 15|1@1+ (1,0) [0|0] "" Vector__XXX
 SG_ EPASTP_a013_mcusscSffMonitoringFailed m0 : 16|1@1+ (1,0) [0|0] "" Vector__XXX
 SG_ EPASTP_a073_rsthOtherEdcEcc m1 : 16|1@1+ (1,0) [0|0] "" Vector__XXX
 SG_ EPASTP_a133_mcusscLbistEcuIdIsNotSupported m2 : 16|1@1+ (1,0) [0|0] "" Vector__XXX
 SG_ EPASTP_a193_osumC0StackNearFull m3 : 16|1@1+ (1,0) [0|0] "" Vector__XXX
 SG_ EPASTP_a254_vcFrontMia m4 : 16|1@1+ (1,0) [0|0] "" Vector__XXX
 SG_ EPASTP_a014_mcusscSffMonitoringMia m0 : 17|1@1+ (1,0) [0|0] "" Vector__XXX
 SG_ EPASTP_a074_rsthUnexpectedAlarm m1 : 17|1@1+ (1,0) [0|0] "" Vector__XXX
 SG_ EPASTP_a134_osehGuardedResetAfterErrWithoutReset m2 : 17|1@1+ (1,0) [0|0] "" Vector__XXX
 SG_ EPASTP_a194_amNvdataLoss m3 : 17|1@1+ (1,0) [0|0] "" Vector__XXX
 SG_ EPASTP_a255_pmState2Mia m4 : 17|1@1+ (1,0) [0|0] "" Vector__XXX
 SG_ EPASTP_a015_mcusscCsErrorCheckFail m0 : 18|1@1+ (1,0) [0|0] "" Vector__XXX
 SG_ EPASTP_a075_rsthUnusedOtherModuleAlarm m1 : 18|1@1+ (1,0) [0|0] "" Vector__XXX
 SG_ EPASTP_a135_tmpsfetjCalculationOverflowErr m2 : 18|1@1+ (1,0) [0|0] "" Vector__XXX
 SG_ EPASTP_a195_imcmCommErrC1 m3 : 18|1@1+ (1,0) [0|0] "" Vector__XXX
 SG_ EPASTP_a256_dcvmOverVolt m4 : 18|1@1+ (1,0) [0|0] "" Vector__XXX
 SG_ EPASTP_a016_mcufcCsErrorCheckFail m0 : 19|1@1+ (1,0) [0|0] "" Vector__XXX
 SG_ EPASTP_a076_exchGeneralException m1 : 19|1@1+ (1,0) [0|0] "" Vector__XXX
 SG_ EPASTP_a136_ftElectricalAngleQf m2 : 19|1@1+ (1,0) [0|0] "" Vector__XXX
 SG_ EPASTP_a196_topEolTasOffsetInvalid m3 : 19|1@1+ (1,0) [0|0] "" Vector__XXX
 SG_ EPASTP_a257_dcvmUnderVolt m4 : 19|1@1+ (1,0) [0|0] "" Vector__XXX
 SG_ EPASTP_a017_stmdStmPlausibilityCheckErr m0 : 20|1@1+ (1,0) [0|0] "" Vector__XXX
 SG_ EPASTP_a077_dmDeadlineViolation m1 : 20|1@1+ (1,0) [0|0] "" Vector__XXX
 SG_ EPASTP_a137_osehErrWithoutImmediateReset m2 : 20|1@1+ (1,0) [0|0] "" Vector__XXX
 SG_ EPASTP_a197_difpDifactorInvalid m3 : 20|1@1+ (1,0) [0|0] "" Vector__XXX
 SG_ EPASTP_a258_pspInvalidProjectParamset m4 : 20|1@1+ (1,0) [0|0] "" Vector__XXX
 SG_ EPASTP_a018_exchCsErrorCheck m0 : 21|1@1+ (1,0) [0|0] "" Vector__XXX
 SG_ EPASTP_a078_dmDeadlineViolation m1 : 21|1@1+ (1,0) [0|0] "" Vector__XXX
 SG_ EPASTP_a138_osehAdditionalErrWithoutImmReset m2 : 21|1@1+ (1,0) [0|0] "" Vector__XXX
 SG_ EPASTP_a198_osumC1CsaNearFull m3 : 21|1@1+ (1,0) [0|0] "" Vector__XXX
 SG_ EPASTP_a259_scoCanBusOff m4 : 21|1@1+ (1,0) [0|0] "" Vector__XXX
 SG_ EPASTP_a019_rsthHwResetInfoCorruptionCheck m0 : 22|1@1+ (1,0) [0|0] "" Vector__XXX
 SG_ EPASTP_a079_gduhComErr m1 : 22|1@1+ (1,0) [0|0] "" Vector__XXX
 SG_ EPASTP_a139_osehAdditionalOsErr m2 : 22|1@1+ (1,0) [0|0] "" Vector__XXX
 SG_ EPASTP_a199_osumC1StackNearFull m3 : 22|1@1+ (1,0) [0|0] "" Vector__XXX
 SG_ EPASTP_a260_scoPrivateBusOff m4 : 22|1@1+ (1,0) [0|0] "" Vector__XXX
 SG_ EPASTP_a020_mcusscEolEcuIdIntegritiyFail m0 : 23|1@1+ (1,0) [0|0] "" Vector__XXX
 SG_ EPASTP_a080_pwmTimerSyncCheck m1 : 23|1@1+ (1,0) [0|0] "" Vector__XXX
 SG_ EPASTP_a140_imcmConfigurationErr m2 : 23|1@1+ (1,0) [0|0] "" Vector__XXX
 SG_ EPASTP_a200_ammInputBufferOverflow m3 : 23|1@1+ (1,0) [0|0] "" Vector__XXX
 SG_ EPASTP_a261_sccmStatusError m4 : 23|1@1+ (1,0) [0|0] "" Vector__XXX
 SG_ EPASTP_a021_osehCsErrorCheck m0 : 24|1@1+ (1,0) [0|0] "" Vector__XXX
 SG_ EPASTP_a081_exchFloatingPointException m1 : 24|1@1+ (1,0) [0|0] "" Vector__XXX
 SG_ EPASTP_a141_amFetShortTest m2 : 24|1@1+ (1,0) [0|0] "" Vector__XXX
 SG_ EPASTP_a201_ammOutputBufferOverflow m3 : 24|1@1+ (1,0) [0|0] "" Vector__XXX
 SG_ EPASTP_a262_yawRateStatus m4 : 24|1@1+ (1,0) [0|0] "" Vector__XXX
 SG_ EPASTP_a022_swrhSwResetInfoCorruptionCheck m0 : 25|1@1+ (1,0) [0|0] "" Vector__XXX
 SG_ EPASTP_a082_adcTriggerTimeChk m1 : 25|1@1+ (1,0) [0|0] "" Vector__XXX
 SG_ EPASTP_a142_tedEmifilterDmcTempChecker m2 : 25|1@1+ (1,0) [0|0] "" Vector__XXX
 SG_ EPASTP_a202_ohnvmpStoredOffsetLost m3 : 25|1@1+ (1,0) [0|0] "" Vector__XXX
 SG_ EPASTP_a263_espWsStatus m4 : 25|1@1+ (1,0) [0|0] "" Vector__XXX
 SG_ EPASTP_a023_btarcCorruptionCheck m0 : 26|1@1+ (1,0) [0|0] "" Vector__XXX
 SG_ EPASTP_a083_tdaDclinkcapacitorTempChecker m1 : 26|1@1+ (1,0) [0|0] "" Vector__XXX
 SG_ EPASTP_a143_tedEmifilterCmcTempChecker m2 : 26|1@1+ (1,0) [0|0] "" Vector__XXX
 SG_ EPASTP_a203_ctcInterfaceErr m3 : 26|1@1+ (1,0) [0|0] "" Vector__XXX
 SG_ EPASTP_a264_assistTorqueLimited m4 : 26|1@1+ (1,0) [0|0] "" Vector__XXX
 SG_ EPASTP_a024_srhCsErrorCheckFail m0 : 27|1@1+ (1,0) [0|0] "" Vector__XXX
 SG_ EPASTP_a084_adcTriggerCheck m1 : 27|1@1+ (1,0) [0|0] "" Vector__XXX
 SG_ EPASTP_a144_mriCoreRaminitFailed m2 : 27|1@1+ (1,0) [0|0] "" Vector__XXX
 SG_ EPASTP_a204_fdpPrevTrqErr m3 : 27|1@1+ (1,0) [0|0] "" Vector__XXX
 SG_ EPASTP_a265_overheatProtect m4 : 27|1@1+ (1,0) [0|0] "" Vector__XXX
 SG_ EPASTP_a025_btarcCorruptionCheck m0 : 28|1@1+ (1,0) [0|0] "" Vector__XXX
 SG_ EPASTP_a085_amGduSwitchOffTestByMcu m1 : 28|1@1+ (1,0) [0|0] "" Vector__XXX
 SG_ EPASTP_a145_mriPeripheralRaminitFailed m2 : 28|1@1+ (1,0) [0|0] "" Vector__XXX
 SG_ EPASTP_a205_fdrOclFail m3 : 28|1@1+ (1,0) [0|0] "" Vector__XXX
 SG_ EPASTP_a266_overloadProtect m4 : 28|1@1+ (1,0) [0|0] "" Vector__XXX
 SG_ EPASTP_a026_mrccCsErrorCheckFail m0 : 29|1@1+ (1,0) [0|0] "" Vector__XXX
 SG_ EPASTP_a086_rsthRamUncorrEcc m1 : 29|1@1+ (1,0) [0|0] "" Vector__XXX
 SG_ EPASTP_a146_btarcRcCircuitCheck m2 : 29|1@1+ (1,0) [0|0] "" Vector__XXX
 SG_ EPASTP_a206_fdrOclPartialBlocking m3 : 29|1@1+ (1,0) [0|0] "" Vector__XXX
 SG_ EPASTP_a267_safeSpeedAssist m4 : 29|1@1+ (1,0) [0|0] "" Vector__XXX
 SG_ EPASTP_a027_mcusscDmuHfErr m0 : 30|1@1+ (1,0) [0|0] "" Vector__XXX
 SG_ EPASTP_a087_rsthFlashConfigErr m1 : 30|1@1+ (1,0) [0|0] "" Vector__XXX
 SG_ EPASTP_a147_amDcLinkShortedFail m2 : 30|1@1+ (1,0) [0|0] "" Vector__XXX
 SG_ EPASTP_a207_fdrOclFreezing m3 : 30|1@1+ (1,0) [0|0] "" Vector__XXX
 SG_ EPASTP_a268_eacCancelled m4 : 30|1@1+ (1,0) [0|0] "" Vector__XXX
 SG_ EPASTP_a028_smuhNonInitDataCorruption m0 : 31|1@1+ (1,0) [0|0] "" Vector__XXX
 SG_ EPASTP_a088_tedMainboardTempChecker m1 : 31|1@1+ (1,0) [0|0] "" Vector__XXX
 SG_ EPASTP_a148_mrccExitFromStandbyDetected m2 : 31|1@1+ (1,0) [0|0] "" Vector__XXX
 SG_ EPASTP_a208_fdrLowSeverityBlocking m3 : 31|1@1+ (1,0) [0|0] "" Vector__XXX
 SG_ EPASTP_a269_assistTorqueDisabled m4 : 31|1@1+ (1,0) [0|0] "" Vector__XXX
 SG_ EPASTP_a029_smuhSmuCoreCntErrorTestFail m0 : 32|1@1+ (1,0) [0|0] "" Vector__XXX
 SG_ EPASTP_a089_tedRevercebattfetjunctionTempChecker m1 : 32|1@1+ (1,0) [0|0] "" Vector__XXX
 SG_ EPASTP_a149_amReversibleEmergencyOffRequested m2 : 32|1@1+ (1,0) [0|0] "" Vector__XXX
 SG_ EPASTP_a209_fdrLowSeverityFreezing m3 : 32|1@1+ (1,0) [0|0] "" Vector__XXX
 SG_ EPASTP_a270_oscillationCompTrqLimReached m4 : 32|1@1+ (1,0) [0|0] "" Vector__XXX
 SG_ EPASTP_a030_rsthClockReset m0 : 33|1@1+ (1,0) [0|0] "" Vector__XXX
 SG_ EPASTP_a090_etsmWarning m1 : 33|1@1+ (1,0) [0|0] "" Vector__XXX
 SG_ EPASTP_a150_amExternalEmergencyOffRequested m2 : 33|1@1+ (1,0) [0|0] "" Vector__XXX
 SG_ EPASTP_a210_fdrTotalBlocking m3 : 33|1@1+ (1,0) [0|0] "" Vector__XXX
 SG_ EPASTP_a031_pmsProductionModeFailed m0 : 34|1@1+ (1,0) [0|0] "" Vector__XXX
 SG_ EPASTP_a091_bvpBattVoltCrossChkFailed m1 : 34|1@1+ (1,0) [0|0] "" Vector__XXX
 SG_ EPASTP_a151_amPermanentEmergencyOffRequested m2 : 34|1@1+ (1,0) [0|0] "" Vector__XXX
 SG_ EPASTP_a211_frmInternalErr m3 : 34|1@1+ (1,0) [0|0] "" Vector__XXX
 SG_ EPASTP_a032_eolpEolCheckFailed m0 : 35|1@1+ (1,0) [0|0] "" Vector__XXX
 SG_ EPASTP_a092_amGduSwitchOffTestBySbc m1 : 35|1@1+ (1,0) [0|0] "" Vector__XXX
 SG_ EPASTP_a152_exchFlashEccException m2 : 35|1@1+ (1,0) [0|0] "" Vector__XXX
 SG_ EPASTP_a212_frmDataLost m3 : 35|1@1+ (1,0) [0|0] "" Vector__XXX
 SG_ EPASTP_a033_icsvcPswVersionMismatch m0 : 36|1@1+ (1,0) [0|0] "" Vector__XXX
 SG_ EPASTP_a093_sctpTsuSingleStaticFail m1 : 36|1@1+ (1,0) [0|0] "" Vector__XXX
 SG_ EPASTP_a153_sdsmBlockSelectorInvalid m2 : 36|1@1+ (1,0) [0|0] "" Vector__XXX
 SG_ EPASTP_a213_frmHighFrictionDetected m3 : 36|1@1+ (1,0) [0|0] "" Vector__XXX
 SG_ EPASTP_a034_sbchReadbackRegFail m0 : 37|1@1+ (1,0) [0|0] "" Vector__XXX
 SG_ EPASTP_a094_sctpTsuMultipleStaticFail m1 : 37|1@1+ (1,0) [0|0] "" Vector__XXX
 SG_ EPASTP_a154_sdsmCsErrorInvalidPrimary m2 : 37|1@1+ (1,0) [0|0] "" Vector__XXX
 SG_ EPASTP_a214_velInterfaceErr m3 : 37|1@1+ (1,0) [0|0] "" Vector__XXX
 SG_ EPASTP_a035_sbchChipIdFail m0 : 38|1@1+ (1,0) [0|0] "" Vector__XXX
 SG_ EPASTP_a095_mdModelBasedMotorIntegrityCheck m1 : 38|1@1+ (1,0) [0|0] "" Vector__XXX
 SG_ EPASTP_a155_sdsmDataInvalidAll m2 : 38|1@1+ (1,0) [0|0] "" Vector__XXX
 SG_ EPASTP_a215_vsgSafeViolErr m3 : 38|1@1+ (1,0) [0|0] "" Vector__XXX
 SG_ EPASTP_a036_sbcmSbcBistFailed m0 : 39|1@1+ (1,0) [0|0] "" Vector__XXX
 SG_ EPASTP_a096_rppRpsSingleStaticFail m1 : 39|1@1+ (1,0) [0|0] "" Vector__XXX
 SG_ EPASTP_a156_amIntSerialErrSafetyReset m2 : 39|1@1+ (1,0) [0|0] "" Vector__XXX
 SG_ EPASTP_a216_isdgImproperShutdown m3 : 39|1@1+ (1,0) [0|0] "" Vector__XXX
 SG_ EPASTP_a037_epmV5P2Fail m0 : 40|1@1+ (1,0) [0|0] "" Vector__XXX
 SG_ EPASTP_a097_rppRpsMultipleStaticFail m1 : 40|1@1+ (1,0) [0|0] "" Vector__XXX
 SG_ EPASTP_a157_mcudcpInvalidEcuId m2 : 40|1@1+ (1,0) [0|0] "" Vector__XXX
 SG_ EPASTP_a217_msdMasterSilentErr m3 : 40|1@1+ (1,0) [0|0] "" Vector__XXX
 SG_ EPASTP_a038_csohCh1CsErrorErrAtReset m0 : 41|1@1+ (1,0) [0|0] "" Vector__XXX
 SG_ EPASTP_a098_invErr m1 : 41|1@1+ (1,0) [0|0] "" Vector__XXX
 SG_ EPASTP_a158_amGduFailDuringRecovery m2 : 41|1@1+ (1,0) [0|0] "" Vector__XXX
 SG_ EPASTP_a218_aadApplicationStateErr m3 : 41|1@1+ (1,0) [0|0] "" Vector__XXX
 SG_ EPASTP_a039_csohCh2CsErrorErrAtReset m0 : 42|1@1+ (1,0) [0|0] "" Vector__XXX
 SG_ EPASTP_a099_mcdTorqueMismatchFault m1 : 42|1@1+ (1,0) [0|0] "" Vector__XXX
 SG_ EPASTP_a159_exchFlashWordlineTransientErr m2 : 42|1@1+ (1,0) [0|0] "" Vector__XXX
 SG_ EPASTP_a219_frhFastRestartFailed m3 : 42|1@1+ (1,0) [0|0] "" Vector__XXX
 SG_ EPASTP_a040_swrhLimitedResetRetriesExpired m0 : 43|1@1+ (1,0) [0|0] "" Vector__XXX
 SG_ EPASTP_a100_amVbrgLssFault m1 : 43|1@1+ (1,0) [0|0] "" Vector__XXX
 SG_ EPASTP_a160_rsthCpu1UnexpectedAlarm m2 : 43|1@1+ (1,0) [0|0] "" Vector__XXX
 SG_ EPASTP_a221_apsCntError m3 : 43|1@1+ (1,0) [0|0] "" Vector__XXX
 SG_ EPASTP_a041_imcmCoreConfigurationMismatch m0 : 44|1@1+ (1,0) [0|0] "" Vector__XXX
 SG_ EPASTP_a101_sdrvSpcIdMismatch m1 : 44|1@1+ (1,0) [0|0] "" Vector__XXX
 SG_ EPASTP_a161_tdaRelayfetjunctionTempChecker m2 : 44|1@1+ (1,0) [0|0] "" Vector__XXX
 SG_ EPASTP_a222_apsCsError m3 : 44|1@1+ (1,0) [0|0] "" Vector__XXX
 SG_ EPASTP_a042_wdhWdTestFail m0 : 45|1@1+ (1,0) [0|0] "" Vector__XXX
 SG_ EPASTP_a102_amPhasecurrentQosErr m1 : 45|1@1+ (1,0) [0|0] "" Vector__XXX
 SG_ EPASTP_a162_tdaBridgefetjunctionTempChecker m2 : 45|1@1+ (1,0) [0|0] "" Vector__XXX
 SG_ EPASTP_a223_apsMia m3 : 45|1@1+ (1,0) [0|0] "" Vector__XXX
 SG_ EPASTP_a043_sbcmWdStateDisabled m0 : 46|1@1+ (1,0) [0|0] "" Vector__XXX
 SG_ EPASTP_a103_exhaUnusedInterruptCallException m1 : 46|1@1+ (1,0) [0|0] "" Vector__XXX
 SG_ EPASTP_a163_tdaPowermoduleTempChecker m2 : 46|1@1+ (1,0) [0|0] "" Vector__XXX
 SG_ EPASTP_a224_dasCntError m3 : 46|1@1+ (1,0) [0|0] "" Vector__XXX
 SG_ EPASTP_a044_sbcmSbcEepromFail m0 : 47|1@1+ (1,0) [0|0] "" Vector__XXX
 SG_ EPASTP_a104_exhaBusMpuException m1 : 47|1@1+ (1,0) [0|0] "" Vector__XXX
 SG_ EPASTP_a164_tdaBattfetjunctionTempChecker m2 : 47|1@1+ (1,0) [0|0] "" Vector__XXX
 SG_ EPASTP_a225_dasCsError m3 : 47|1@1+ (1,0) [0|0] "" Vector__XXX
 SG_ EPASTP_a045_psumSbcBandgapVoltErr m0 : 48|1@1+ (1,0) [0|0] "" Vector__XXX
 SG_ EPASTP_a105_exhaSriBusErrException m1 : 48|1@1+ (1,0) [0|0] "" Vector__XXX
 SG_ EPASTP_a165_tdaDcbusshuntTempChecker m2 : 48|1@1+ (1,0) [0|0] "" Vector__XXX
 SG_ EPASTP_a226_dasMia m3 : 48|1@1+ (1,0) [0|0] "" Vector__XXX
 SG_ EPASTP_a046_mcusscOscillatorNotReliable m0 : 49|1@1+ (1,0) [0|0] "" Vector__XXX
 SG_ EPASTP_a106_exhaSpbBusErrException m1 : 49|1@1+ (1,0) [0|0] "" Vector__XXX
 SG_ EPASTP_a166_tdaPhasecurrentshuntTempChecker m2 : 49|1@1+ (1,0) [0|0] "" Vector__XXX
 SG_ EPASTP_a227_dirTorqueCntError m3 : 49|1@1+ (1,0) [0|0] "" Vector__XXX
 SG_ EPASTP_a047_epmVregVoltFail m0 : 50|1@1+ (1,0) [0|0] "" Vector__XXX
 SG_ EPASTP_a107_exhaOtherNmiException m1 : 50|1@1+ (1,0) [0|0] "" Vector__XXX
 SG_ EPASTP_a167_iccd1ErrQueueOverflow m2 : 50|1@1+ (1,0) [0|0] "" Vector__XXX
 SG_ EPASTP_a228_dirTorqueCsError m3 : 50|1@1+ (1,0) [0|0] "" Vector__XXX
 SG_ EPASTP_a048_epmVcpVoltFail m0 : 51|1@1+ (1,0) [0|0] "" Vector__XXX
 SG_ EPASTP_a108_exhaInternalProtectionException m1 : 51|1@1+ (1,0) [0|0] "" Vector__XXX
 SG_ EPASTP_a168_c1csInvalidC1App m2 : 51|1@1+ (1,0) [0|0] "" Vector__XXX
 SG_ EPASTP_a229_dirTorqueMia m3 : 51|1@1+ (1,0) [0|0] "" Vector__XXX
 SG_ EPASTP_a049_epmLgFail m0 : 52|1@1+ (1,0) [0|0] "" Vector__XXX
 SG_ EPASTP_a109_exhaSysBusOrPeriphErrException m1 : 52|1@1+ (1,0) [0|0] "" Vector__XXX
 SG_ EPASTP_a169_scpSafetyReset m2 : 52|1@1+ (1,0) [0|0] "" Vector__XXX
 SG_ EPASTP_a230_diSpdCntError m3 : 52|1@1+ (1,0) [0|0] "" Vector__XXX
 SG_ EPASTP_a050_erlErr m0 : 53|1@1+ (1,0) [0|0] "" Vector__XXX
 SG_ EPASTP_a110_amPhaseRelaySwitchOffTest m1 : 53|1@1+ (1,0) [0|0] "" Vector__XXX
 SG_ EPASTP_a170_pmpDcvoltAge m2 : 53|1@1+ (1,0) [0|0] "" Vector__XXX
 SG_ EPASTP_a231_diSpdCsError m3 : 53|1@1+ (1,0) [0|0] "" Vector__XXX
 SG_ EPASTP_a051_ermMessageErr m0 : 54|1@1+ (1,0) [0|0] "" Vector__XXX
 SG_ EPASTP_a111_amCurrentSensingDisconnection m1 : 54|1@1+ (1,0) [0|0] "" Vector__XXX
 SG_ EPASTP_a171_pmpKgvalueAge m2 : 54|1@1+ (1,0) [0|0] "" Vector__XXX
 SG_ EPASTP_a232_diSpdMia m3 : 54|1@1+ (1,0) [0|0] "" Vector__XXX
 SG_ EPASTP_a052_ermSdcInputBufferOverflow m0 : 55|1@1+ (1,0) [0|0] "" Vector__XXX
 SG_ EPASTP_a112_rsthSafetyFlipflopErr m1 : 55|1@1+ (1,0) [0|0] "" Vector__XXX
 SG_ EPASTP_a172_pmpElangMotorcurrentAge m2 : 55|1@1+ (1,0) [0|0] "" Vector__XXX
 SG_ EPASTP_a233_ecu2StatCntError m3 : 55|1@1+ (1,0) [0|0] "" Vector__XXX
 SG_ EPASTP_a053_adcUnexpectedNumOfData m0 : 56|1@1+ (1,0) [0|0] "" Vector__XXX
 SG_ EPASTP_a113_rsthUncorrectableEndToEndBusErr m1 : 56|1@1+ (1,0) [0|0] "" Vector__XXX
 SG_ EPASTP_a173_pmpRotorspeedAge m2 : 56|1@1+ (1,0) [0|0] "" Vector__XXX
 SG_ EPASTP_a234_ecu2StatCsError m3 : 56|1@1+ (1,0) [0|0] "" Vector__XXX
 SG_ EPASTP_a054_adcUnexpectedData m0 : 57|1@1+ (1,0) [0|0] "" Vector__XXX
 SG_ EPASTP_a114_osehOsErr m1 : 57|1@1+ (1,0) [0|0] "" Vector__XXX
 SG_ EPASTP_a174_pmpPhasecurrentAge m2 : 57|1@1+ (1,0) [0|0] "" Vector__XXX
 SG_ EPASTP_a235_ecu2StatMia m3 : 57|1@1+ (1,0) [0|0] "" Vector__XXX
 SG_ EPASTP_a055_amExtendedGduTest m0 : 58|1@1+ (1,0) [0|0] "" Vector__XXX
 SG_ EPASTP_a115_mcusscLbistSingleFail m1 : 58|1@1+ (1,0) [0|0] "" Vector__XXX
 SG_ EPASTP_a175_exchFlashStoredConfigErr m2 : 58|1@1+ (1,0) [0|0] "" Vector__XXX
 SG_ EPASTP_a236_espWrCntError m3 : 58|1@1+ (1,0) [0|0] "" Vector__XXX
 SG_ EPASTP_a056_amGduConfigCsErrorCheck m0 : 59|1@1+ (1,0) [0|0] "" Vector__XXX
 SG_ EPASTP_a116_mrccStartupRegCsErrorStaticErr m1 : 59|1@1+ (1,0) [0|0] "" Vector__XXX
 SG_ EPASTP_a176_exchCpu1ExceptionReset m2 : 59|1@1+ (1,0) [0|0] "" Vector__XXX
 SG_ EPASTP_a237_espWrCsError m3 : 59|1@1+ (1,0) [0|0] "" Vector__XXX
 SG_ EPASTP_a057_amGduVds m0 : 60|1@1+ (1,0) [0|0] "" Vector__XXX
 SG_ EPASTP_a117_mrccStartupRegCsErrorTransientErr m1 : 60|1@1+ (1,0) [0|0] "" Vector__XXX
 SG_ EPASTP_a177_etsrInvalidated m2 : 60|1@1+ (1,0) [0|0] "" Vector__XXX
 SG_ EPASTP_a238_espWrMia m3 : 60|1@1+ (1,0) [0|0] "" Vector__XXX
 SG_ EPASTP_a058_amIntVgsUndervtgErr m0 : 61|1@1+ (1,0) [0|0] "" Vector__XXX
 SG_ EPASTP_a118_mcusscFlashCsErrorErr m1 : 61|1@1+ (1,0) [0|0] "" Vector__XXX
 SG_ EPASTP_a178_exchWdtException m2 : 61|1@1+ (1,0) [0|0] "" Vector__XXX
 SG_ EPASTP_a239_espWsCntError m3 : 61|1@1+ (1,0) [0|0] "" Vector__XXX
 SG_ EPASTP_a059_amStartupTestFailed m0 : 62|1@1+ (1,0) [0|0] "" Vector__XXX
 SG_ EPASTP_a119_mcusscFlashEccCriticalErr m1 : 62|1@1+ (1,0) [0|0] "" Vector__XXX
 SG_ EPASTP_a179_tedMotorcoilTempChecker m2 : 62|1@1+ (1,0) [0|0] "" Vector__XXX
 SG_ EPASTP_a240_espWsCsError m3 : 62|1@1+ (1,0) [0|0] "" Vector__XXX
 SG_ EPASTP_a060_amGduFail m0 : 63|1@1+ (1,0) [0|0] "" Vector__XXX
 SG_ EPASTP_a120_mcusscFlashEccLatentErr m1 : 63|1@1+ (1,0) [0|0] "" Vector__XXX
 SG_ EPASTP_a180_dmDeadlineViolationC1 m2 : 63|1@1+ (1,0) [0|0] "" Vector__XXX
 SG_ EPASTP_a241_espWsMia m3 : 63|1@1+ (1,0) [0|0] "" Vector__XXX

BO_ 923 DAS_status: 8 Vector__XXX
 SG_ DAS_autopilotState : 0|4@1+ (1,0) [0|0] "" Vector__XXX
 SG_ DAS_blindSpotRearLeft : 4|2@1+ (1,0) [0|0] "" Vector__XXX
 SG_ DAS_blindSpotRearRight : 6|2@1+ (1,0) [0|0] "" Vector__XXX
 SG_ DAS_fusedSpeedLimit : 8|5@1+ (5,0) [0|0] "" Vector__XXX
 SG_ DAS_suppressSpeedWarning : 13|1@1+ (1,0) [0|0] "" Vector__XXX
 SG_ DAS_summonObstacle : 14|1@1+ (1,0) [0|0] "" Vector__XXX
 SG_ DAS_summonClearedGate : 15|1@1+ (1,0) [0|0] "" Vector__XXX
 SG_ DAS_visionOnlySpeedLimit : 16|5@1+ (5,0) [0|0] "" Vector__XXX
 SG_ DAS_heaterState : 21|1@1+ (1,0) [0|0] "" Vector__XXX
 SG_ DAS_forwardCollisionWarning : 22|2@1+ (1,0) [0|0] "" Vector__XXX
 SG_ DAS_autoparkReady : 24|1@1+ (1,0) [0|0] "" Vector__XXX
 SG_ DAS_autoParked : 25|1@1+ (1,0) [0|0] "" Vector__XXX
 SG_ DAS_autoparkActive : 26|1@1+ (1,0) [0|0] "" Vector__XXX
 SG_ DAS_summonFwdLeashReached : 27|1@1+ (1,0) [0|0] "" Vector__XXX
 SG_ DAS_summonRvsLeashReached : 28|1@1+ (1,0) [0|0] "" Vector__XXX
 SG_ DAS_lssState : 29|3@1+ (1,0) [0|0] "" Vector__XXX
 SG_ DAS_sideCollisionAvoid : 32|2@1+ (1,0) [0|0] "" Vector__XXX
 SG_ DAS_sideCollisionWarning : 34|2@1+ (1,0) [0|0] "" Vector__XXX
 SG_ DAS_sideCollisionInhibit : 36|1@1+ (1,0) [0|0] "" Vector__XXX
 SG_ DAS_laneDepartureWarning : 37|3@1+ (1,0) [0|0] "" Vector__XXX
 SG_ DAS_fleetSpeedState : 40|2@1+ (1,0) [0|0] "" Vector__XXX
 SG_ DAS_autopilotHandsOnState : 42|4@1+ (1,0) [0|0] "" Vector__XXX
 SG_ DAS_autoLaneChangeState : 46|5@1+ (1,0) [0|0] "" Vector__XXX
 SG_ DAS_summonAvailable : 51|1@1+ (1,0) [0|0] "" Vector__XXX
 SG_ DAS_statusCounter : 52|4@1+ (1,0) [0|0] "" Vector__XXX
 SG_ DAS_statusChecksum : 56|8@1+ (1,0) [0|0] "" Vector__XXX

BO_ 924 VCRIGHT_stationaryDetect: 8 Vector__XXX
 SG_ VCRIGHT_angleVar : 0|20@1+ (1e-05,0) [0|0] "" Vector__XXX
 SG_ VCRIGHT_accelVar : 20|20@1+ (1e-05,0) [0|0] "" Vector__XXX
 SG_ VCRIGHT_detectedMovingWhileStopped : 40|1@1+ (1,0) [0|0] "" Vector__XXX
 SG_ VCRIGHT_detectedStationaryAtSpeed : 41|1@1+ (1,0) [0|0] "" Vector__XXX
 SG_ VCRIGHT_slopeStable : 42|1@1+ (1,0) [0|0] "" Vector__XXX
 SG_ VCRIGHT_stationaryParkRequest : 43|1@1+ (1,0) [0|0] "" Vector__XXX
 SG_ VCRIGHT_brakePressHeld : 44|1@1+ (1,0) [0|0] "" Vector__XXX
 SG_ VCRIGHT_epbOpenUnableToPark : 45|1@1+ (1,0) [0|0] "" Vector__XXX
 SG_ VCRIGHT_slopeParkable : 46|1@1+ (1,0) [0|0] "" Vector__XXX
 SG_ VCRIGHT_uiNotAvailable : 47|1@1+ (1,0) [0|0] "" Vector__XXX
 SG_ VCRIGHT_varianceStationary : 48|1@1+ (1,0) [0|0] "" Vector__XXX

BO_ 925 IBST_status: 8 Vector__XXX
 SG_ IBST_statusChecksum : 0|8@1+ (1,0) [0|0] "" Vector__XXX
 SG_ IBST_statusCounter : 8|4@1+ (1,0) [0|0] "" Vector__XXX
 SG_ IBST_iBoosterStatus : 12|3@1+ (1,0) [0|0] "" Vector__XXX
 SG_ IBST_driverBrakeApply : 16|2@1+ (1,0) [0|0] "" Vector__XXX
 SG_ IBST_internalState : 18|3@1+ (1,0) [0|0] "" Vector__XXX
 SG_ IBST_sInputRodDriver : 21|12@1+ (0.015625,-5) [0|0] "" Vector__XXX
 SG_ IBST_LVPowerModeState : 35|2@1+ (1,0) [0|0] "" Vector__XXX

BO_ 930 VCFRONT_outputPowerStatus: 8 Vector__XXX
 SG_ VCFRONT_outputPowerStatusMuxIndex M : 0|1@1+ (1,0) [0|0] "" Vector__XXX
 SG_ VCFRONT_vcleftCurrentInputResistance m0 : 1|12@1+ (0.05,0) [0|0] "" Vector__XXX
 SG_ VCFRONT_vcrightCurrentInputResistance m1 : 1|12@1+ (0.05,0) [0|0] "" Vector__XXX
 SG_ VCFRONT_vcleftVoltageInputResistance m0 : 14|12@1+ (0.005443676098,0) [0|0] "" Vector__XXX
 SG_ VCFRONT_vcrightVoltageInputResistance m1 : 14|12@1+ (0.005443676098,0) [0|0] "" Vector__XXX
 SG_ VCFRONT_vcleftSampleTimestamp m0 : 26|32@1+ (1,0) [0|0] "" Vector__XXX
 SG_ VCFRONT_vcrightSampleTimestamp m1 : 26|32@1+ (1,0) [0|0] "" Vector__XXX

BO_ 931 VCLEFT_sourceImpedanceSyncStatus: 8 Vector__XXX
 SG_ VCLEFT_upstreamVoltage : 0|12@1+ (0.005443676098,0) [0|0] "" Vector__XXX
 SG_ VCLEFT_upstreamCurrent : 12|12@1+ (0.05,0) [0|0] "" Vector__XXX
 SG_ VCLEFT_localVoltage : 24|12@1+ (0.005443676098,0) [0|0] "" Vector__XXX
 SG_ VCLEFT_resistanceEstimate : 36|12@1+ (0.00061,0) [0|0] "" Vector__XXX
 SG_ VCLEFT_prevUpstreamCurrent : 48|12@1+ (0.05,0) [0|0] "" Vector__XXX
 SG_ VCLEFT_voltageRational : 60|1@1+ (1,0) [0|0] "" Vector__XXX

BO_ 932 VCRIGHT_sourceImpedanceSyncStatus: 8 Vector__XXX
 SG_ VCRIGHT_upstreamVoltage : 0|12@1+ (0.005443676098,0) [0|0] "" Vector__XXX
 SG_ VCRIGHT_upstreamCurrent : 12|12@1+ (0.05,0) [0|0] "" Vector__XXX
 SG_ VCRIGHT_localVoltage : 24|12@1+ (0.005443676098,0) [0|0] "" Vector__XXX
 SG_ VCRIGHT_resistanceEstimate : 36|12@1+ (0.00061,0) [0|0] "" Vector__XXX
 SG_ VCRIGHT_prevUpstreamCurrent : 48|12@1+ (0.05,0) [0|0] "" Vector__XXX
 SG_ VCRIGHT_voltageRational : 60|1@1+ (1,0) [0|0] "" Vector__XXX

BO_ 933 VCLEFT_sourceImpedanceSyncStatusDebug: 8 Vector__XXX
 SG_ VCLEFT_timeOffset : 0|31@1- (1,0) [0|0] "" Vector__XXX
 SG_ VCLEFT_timeSyncValid : 32|1@1+ (1,0) [0|0] "" Vector__XXX
 SG_ VCLEFT_sampleTransmitLatency : 33|9@1+ (0.1,0) [0|0] "" Vector__XXX

BO_ 934 VCRIGHT_sourceImpedanceSyncStatusDebug: 8 Vector__XXX
 SG_ VCRIGHT_timeOffset : 0|31@1- (1,0) [0|0] "" Vector__XXX
 SG_ VCRIGHT_timeSyncValid : 32|1@1+ (1,0) [0|0] "" Vector__XXX
 SG_ VCRIGHT_sampleTransmitLatency : 33|9@1+ (0.1,0) [0|0] "" Vector__XXX

BO_ 949 BRAKE_primaryActuator: 8 Vector__XXX
 SG_ BRAKE_primaryActuatorChecksum : 0|8@1+ (1,0) [0|0] "" Vector__XXX
 SG_ BRAKE_primaryActuatorCounter : 8|4@1+ (1,0) [0|0] "" Vector__XXX
 SG_ BRAKE_primaryActuatorValveVolt : 12|11@1+ (0.01,0) [0|0] "" Vector__XXX
 SG_ BRAKE_primaryActuatorMotorVolt : 23|11@1+ (0.01,0) [0|0] "" Vector__XXX

BO_ 950 BRAKE_secondaryActuator: 8 Vector__XXX
 SG_ BRAKE_secondaryActuatorChecksum : 0|8@1+ (1,0) [0|0] "" Vector__XXX
 SG_ BRAKE_secondaryActuatorCounter : 8|4@1+ (1,0) [0|0] "" Vector__XXX
 SG_ BRAKE_secondaryActuatorValveVolt : 12|11@1+ (0.01,0) [0|0] "" Vector__XXX
 SG_ BRAKE_secondaryActuatorMotorVolt : 23|11@1+ (0.01,0) [0|0] "" Vector__XXX

BO_ 977 EPAS3P_angleCalibration: 8 Vector__XXX
 SG_ EPAS3P_appliedAngleOffset : 0|8@1+ (0.1,-12.8) [0|0] "" Vector__XXX
 SG_ EPAS3P_calculatedAngleOffset : 8|8@1+ (0.1,-12.8) [0|0] "" Vector__XXX
 SG_ EPAS3P_resyncStatus : 16|1@1+ (1,0) [0|0] "" Vector__XXX
 SG_ EPAS3P_pullDriftLongTermTrq : 17|12@1+ (0.01,-10) [0|0] "" Vector__XXX
 SG_ EPAS3P_pullDriftCompTrq : 29|12@1+ (0.01,-10) [0|0] "" Vector__XXX
 SG_ EPAS3P_learnedSCCMOffset : 41|8@1+ (0.1,-12.8) [0|0] "" Vector__XXX

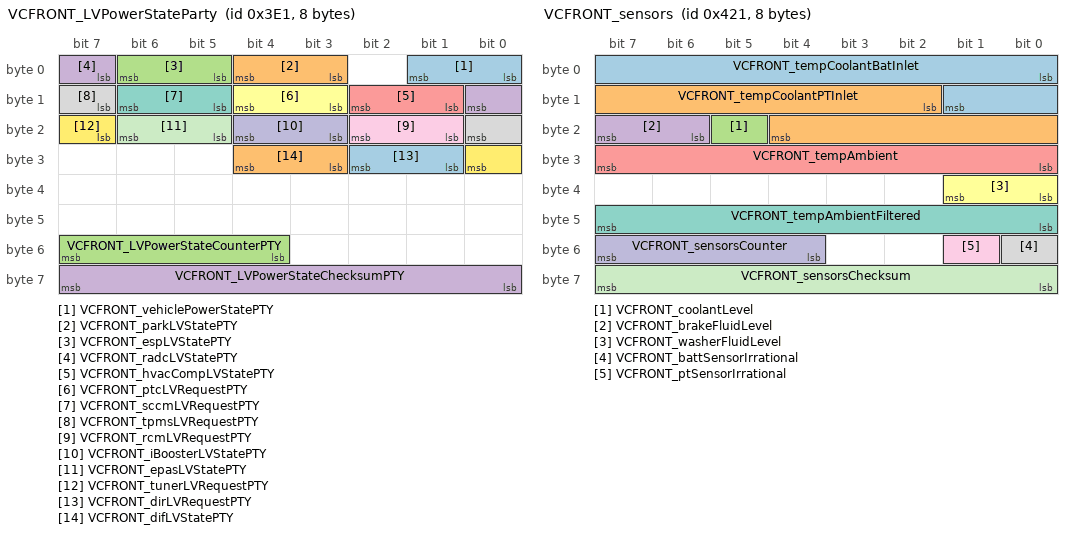
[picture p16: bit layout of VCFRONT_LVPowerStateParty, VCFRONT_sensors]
BO_ 993 VCFRONT_LVPowerStateParty: 8 Vector__XXX
 SG_ VCFRONT_vehiclePowerStatePTY : 0|2@1+ (1,0) [0|0] "" Vector__XXX
 SG_ VCFRONT_parkLVStatePTY : 3|2@1+ (1,0) [0|0] "" Vector__XXX
 SG_ VCFRONT_espLVStatePTY : 5|2@1+ (1,0) [0|0] "" Vector__XXX
 SG_ VCFRONT_radcLVStatePTY : 7|2@1+ (1,0) [0|0] "" Vector__XXX
 SG_ VCFRONT_hvacCompLVStatePTY : 9|2@1+ (1,0) [0|0] "" Vector__XXX
 SG_ VCFRONT_ptcLVRequestPTY : 11|2@1+ (1,0) [0|0] "" Vector__XXX
 SG_ VCFRONT_sccmLVRequestPTY : 13|2@1+ (1,0) [0|0] "" Vector__XXX
 SG_ VCFRONT_tpmsLVRequestPTY : 15|2@1+ (1,0) [0|0] "" Vector__XXX
 SG_ VCFRONT_rcmLVRequestPTY : 17|2@1+ (1,0) [0|0] "" Vector__XXX
 SG_ VCFRONT_iBoosterLVStatePTY : 19|2@1+ (1,0) [0|0] "" Vector__XXX
 SG_ VCFRONT_epasLVStatePTY : 21|2@1+ (1,0) [0|0] "" Vector__XXX
 SG_ VCFRONT_tunerLVRequestPTY : 23|2@1+ (1,0) [0|0] "" Vector__XXX
 SG_ VCFRONT_dirLVRequestPTY : 25|2@1+ (1,0) [0|0] "" Vector__XXX
 SG_ VCFRONT_difLVStatePTY : 27|2@1+ (1,0) [0|0] "" Vector__XXX
 SG_ VCFRONT_LVPowerStateCounterPTY : 52|4@1+ (1,0) [0|0] "" Vector__XXX
 SG_ VCFRONT_LVPowerStateChecksumPTY : 56|8@1+ (1,0) [0|0] "" Vector__XXX

BO_ 1009 VCFRONT_AP_vehicleState1HzMuxed: 8 Vector__XXX
 SG_ VCFRONT_AP_vehicleState1HzMuxedIndex M : 12|2@1+ (1,0) [0|0] "" Vector__XXX
 SG_ VCFRONT_AP_wiperECUType m0 : 14|2@1+ (1,0) [0|0] "" Vector__XXX
 SG_ VCFRONT_APGlassHeaterType m1 : 16|3@1+ (1,0) [0|0] "" Vector__XXX
 SG_ VCFRONT_AP_wiperFrictionInwipeSpeed m0 : 16|3@1+ (1,0) [0|0] "" Vector__XXX
 SG_ VCFRONT_APGlassHeaterResistance m1 : 19|10@1+ (0.01,0) [0|0] "" Vector__XXX
 SG_ VCFRONT_AP_wiperFrictionOutwipeSpeed m0 : 19|3@1+ (1,0) [0|0] "" Vector__XXX
 SG_ VCFRONT_AP_wiperFrictionAvgInwipePower m0 : 22|8@1+ (0.5,0) [0|0] "" Vector__XXX
 SG_ VCFRONT_AP_maxAllowedSleepPower m1 : 30|8@1+ (0.25,0) [0|0] "" Vector__XXX
 SG_ VCFRONT_AP_wiperFrictionAvgOutwipePower m0 : 30|8@1+ (0.5,0) [0|0] "" Vector__XXX
 SG_ VCFRONT_AP_hasNarrowWipingHardware m1 : 38|1@1+ (1,0) [0|0] "" Vector__XXX
 SG_ VCFRONT_AP_wiperFrictionInwipeTime m0 : 38|7@1+ (10,0) [0|0] "" Vector__XXX
 SG_ VCFRONT_AP_narrowWipingAvailable m1 : 39|1@1+ (1,0) [0|0] "" Vector__XXX
 SG_ VCFRONT_ah_coolantSystemState m1 : 40|3@1+ (1,0) [0|0] "" Vector__XXX
 SG_ VCFRONT_AP_wiperFrictionOutwipeTime m0 : 45|7@1+ (10,0) [0|0] "" Vector__XXX
 SG_ VCFRONT_LVPowerSecondsToPrecondition m1 : 48|16@1+ (1,0) [0|0] "" Vector__XXX
 SG_ VCFRONT_AP_wiperFrictionAvgWetOutwipePower m0 : 52|8@1+ (0.5,0) [0|0] "" Vector__XXX
 SG_ VCFRONT_AP_wiperFrictionOutwipeCycleCount m0 : 60|4@1+ (100,0) [0|0] "" Vector__XXX

BO_ 1016 VCBATT2_cameraCleaningLogging: 8 Vector__XXX
 SG_ VCBATT2_washPump1Current : 0|12@1- (0.02,0) [0|0] "" Vector__XXX
 SG_ VCBATT2_washPump2Current : 12|12@1- (0.02,0) [0|0] "" Vector__XXX
 SG_ VCBATT2_washer1FluidLevelRaw : 24|2@1+ (1,0) [0|0] "" Vector__XXX
 SG_ VCBATT2_washer2FluidLevelRaw : 26|2@1+ (1,0) [0|0] "" Vector__XXX

BO_ 1023 APS_selfTest: 8 Vector__XXX
 SG_ APS_selfTestReserved : 0|64@1+ (1,0) [0|0] "" Vector__XXX

BO_ 1057 VCFRONT_sensors: 8 Vector__XXX
 SG_ VCFRONT_tempCoolantBatInlet : 0|10@1+ (0.125,-40) [0|0] "" Vector__XXX
 SG_ VCFRONT_tempCoolantPTInlet : 10|11@1+ (0.125,-40) [0|0] "" Vector__XXX
 SG_ VCFRONT_coolantLevel : 21|1@1+ (1,0) [0|0] "" Vector__XXX
 SG_ VCFRONT_brakeFluidLevel : 22|2@1+ (1,0) [0|0] "" Vector__XXX
 SG_ VCFRONT_tempAmbient : 24|8@1+ (0.5,-40) [0|0] "" Vector__XXX
 SG_ VCFRONT_washerFluidLevel : 32|2@1+ (1,0) [0|0] "" Vector__XXX
 SG_ VCFRONT_tempAmbientFiltered : 40|8@1+ (0.5,-40) [0|0] "" Vector__XXX
 SG_ VCFRONT_battSensorIrrational : 48|1@1+ (1,0) [0|0] "" Vector__XXX
 SG_ VCFRONT_ptSensorIrrational : 49|1@1+ (1,0) [0|0] "" Vector__XXX
 SG_ VCFRONT_sensorsCounter : 52|4@1+ (1,0) [0|0] "" Vector__XXX
 SG_ VCFRONT_sensorsChecksum : 56|8@1+ (1,0) [0|0] "" Vector__XXX

BO_ 1160 DAS_steeringControl: 8 Vector__XXX
 SG_ DAS_steeringAngleRequest : 6|15@0+ (0.1,-1638.35) [0|0] "" Vector__XXX
 SG_ DAS_steeringHapticRequest : 7|1@0+ (1,0) [0|0] "" Vector__XXX
 SG_ DAS_steeringControlCounter : 19|4@0+ (1,0) [0|0] "" Vector__XXX
 SG_ DAS_steeringControlType : 23|2@0+ (1,0) [0|0] "" Vector__XXX
 SG_ DAS_steeringControlChecksum : 31|8@0+ (1,0) [0|0] "" Vector__XXX

BO_ 1161 DAS_brakeControl: 8 Vector__XXX
 SG_ DAS_brakeControlChecksum : 0|8@1+ (1,0) [0|0] "" Vector__XXX
 SG_ DAS_brakeControlCounter : 8|4@1+ (1,0) [0|0] "" Vector__XXX
 SG_ DAS_brakeTorqueCommand : 12|13@1+ (2,0) [0|0] "" Vector__XXX
 SG_ DAS_brakeControlRequest : 25|1@1+ (1,0) [0|0] "" Vector__XXX

BO_ 1249 VCFRONT_vehicleTime: 8 Vector__XXX
 SG_ VCFRONT_timeSync : 0|32@1+ (1,0) [0|0] "" Vector__XXX

BO_ 1265 VCFRONT_AP_vehicleState1Hz: 8 Vector__XXX
 SG_ VCFRONT_AP_vehicleState1HzChecksum : 0|8@1+ (1,0) [0|0] "" Vector__XXX
 SG_ VCFRONT_AP_vehicleState1HzCounter : 8|4@1+ (1,0) [0|0] "" Vector__XXX
 SG_ VCFRONT_AP_glassHeaterState : 12|3@1+ (1,0) [0|0] "" Vector__XXX
 SG_ VCFRONT_AP_preconditionRequest : 15|1@1+ (1,0) [0|0] "" Vector__XXX
 SG_ VCFRONT_AP_tempAmbientFiltered : 16|8@1+ (0.5,-40) [0|0] "" Vector__XXX
 SG_ VCFRONT_AP_thsTemperature : 24|8@1+ (1,-40) [0|0] "" Vector__XXX
 SG_ VCFRONT_AP_thsActive : 32|1@1+ (1,0) [0|0] "" Vector__XXX
 SG_ VCFRONT_AP_coolantLevel : 33|1@1+ (1,0) [0|0] "" Vector__XXX
 SG_ VCFRONT_AP_leftTurnSignalFault : 34|1@1+ (1,0) [0|0] "" Vector__XXX
 SG_ VCFRONT_AP_rightTurnSignalFault : 35|1@1+ (1,0) [0|0] "" Vector__XXX
 SG_ VCFRONT_AP_interiorCameraLedLVState : 36|2@1+ (1,0) [0|0] "" Vector__XXX
 SG_ VCFRONT_AP_isAdaptiveHighBeamAvailable : 38|1@1+ (1,0) [0|0] "" Vector__XXX
 SG_ VCFRONT_AP_bothHeadlampsAimed : 39|1@1+ (1,0) [0|0] "" Vector__XXX
 SG_ VCFRONT_AP_highBeamLeftStatus : 40|2@1+ (1,0) [0|0] "" Vector__XXX
 SG_ VCFRONT_AP_highBeamRightStatus : 42|2@1+ (1,0) [0|0] "" Vector__XXX
 SG_ VCFRONT_AP_lowBeamLeftStatus : 44|2@1+ (1,0) [0|0] "" Vector__XXX
 SG_ VCFRONT_AP_lowBeamRightStatus : 46|2@1+ (1,0) [0|0] "" Vector__XXX
 SG_ VCFRONT_AP_washerFluidLevel : 48|2@1+ (1,0) [0|0] "" Vector__XXX
 SG_ VCFRONT_AP_passengerPresent : 50|1@1+ (1,0) [0|0] "" Vector__XXX
 SG_ VCFRONT_AP_hvacBlowerRPMActual : 51|5@1+ (200,0) [0|0] "" Vector__XXX
 SG_ VCFRONT_AP_hvacCabinTempEst : 56|7@1+ (1,-30) [0|0] "" Vector__XXX
 SG_ VCFRONT_AP_hvacOn : 63|1@1+ (1,0) [0|0] "" Vector__XXX

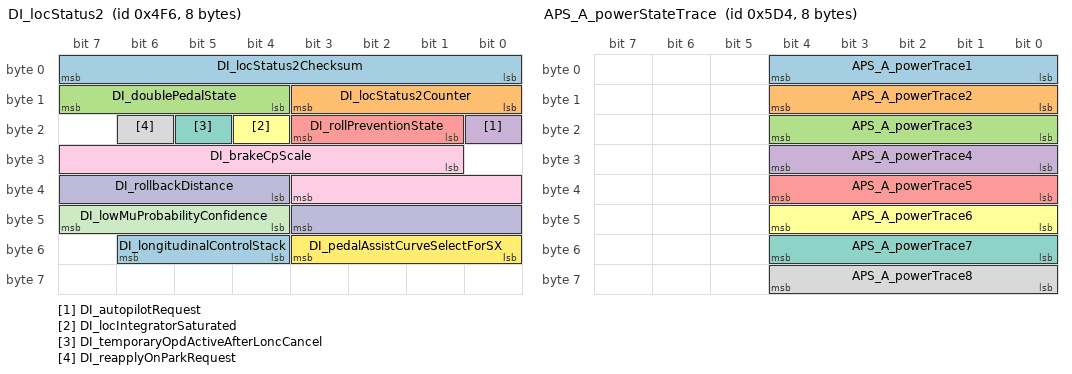
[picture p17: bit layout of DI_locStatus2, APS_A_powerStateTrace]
BO_ 1270 DI_locStatus2: 8 Vector__XXX
 SG_ DI_locStatus2Checksum : 0|8@1+ (1,0) [0|0] "" Vector__XXX
 SG_ DI_locStatus2Counter : 8|4@1+ (1,0) [0|0] "" Vector__XXX
 SG_ DI_doublePedalState : 12|4@1+ (1,0) [0|0] "" Vector__XXX
 SG_ DI_autopilotRequest : 16|1@1+ (1,0) [0|0] "" Vector__XXX
 SG_ DI_rollPreventionState : 17|3@1+ (1,0) [0|0] "" Vector__XXX
 SG_ DI_locIntegratorSaturated : 20|1@1+ (1,0) [0|0] "" Vector__XXX
 SG_ DI_temporaryOpdActiveAfterLoncCancel : 21|1@1+ (1,0) [0|0] "" Vector__XXX
 SG_ DI_reapplyOnParkRequest : 22|1@1+ (1,0) [0|0] "" Vector__XXX
 SG_ DI_brakeCpScale : 25|11@1+ (0.005,0) [0|0] "" Vector__XXX
 SG_ DI_rollbackDistance : 36|8@1+ (0.005,0) [0|0] "" Vector__XXX
 SG_ DI_lowMuProbabilityConfidence : 44|4@1+ (0.06666666666666667,0) [0|0] "" Vector__XXX
 SG_ DI_pedalAssistCurveSelectForSX : 48|4@1+ (1,0) [0|0] "" Vector__XXX
 SG_ DI_longitudinalControlStack : 52|3@1+ (1,0) [0|0] "" Vector__XXX

BO_ 1271 DI_systemTorque: 8 Vector__XXX
 SG_ DI_sysTorqueCommand : 0|16@1- (0.5,0) [0|0] "" Vector__XXX
 SG_ DI_sysTorqueActual : 16|16@1- (0.5,0) [0|0] "" Vector__XXX

BO_ 1361 EPAS3P_bootID: 8 Vector__XXX
 SG_ EPAS3P_bootIdData : 0|64@1+ (1,0) [0|0] "" Vector__XXX

BO_ 1365 DIF_statistics: 8 Vector__XXX
 SG_ DIF_torqueEstimated : 0|13@1- (2,0) [0|0] "" Vector__XXX
 SG_ DIF_torqueErrorEstimated : 16|11@1- (0.1,0) [0|0] "" Vector__XXX

BO_ 1426 EPAS3P_alertLog: 8 Vector__XXX
 SG_ EPAS3P_alertID M : 0|8@1+ (1,0) [0|0] "" Vector__XXX
 SG_ EPAS3P_alertState : 15|1@1+ (1,0) [0|0] "" Vector__XXX
 SG_ EPAS3P_a084_eacCancelMtrq m84 : 16|10@1+ (0.01,0) [0|0] "" Vector__XXX
 SG_ EPAS3P_a132_motorTorqueCommand m132 : 16|8@1- (0.0787,0) [0|0] "" Vector__XXX
 SG_ EPAS3P_a133_motorTorqueCommand m133 : 16|8@1- (0.0787,0) [0|0] "" Vector__XXX
 SG_ EPAS3P_a134_motorTorqueCommand m134 : 16|8@1- (0.0787,0) [0|0] "" Vector__XXX
 SG_ EPAS3P_a135_motorTorqueCommand m135 : 16|8@1- (0.0787,0) [0|0] "" Vector__XXX
 SG_ EPAS3P_a136_motorTorqueCommand m136 : 16|8@1- (0.0787,0) [0|0] "" Vector__XXX
 SG_ EPAS3P_a137_motorTorqueCommand m137 : 16|8@1- (0.0787,0) [0|0] "" Vector__XXX
 SG_ EPAS3P_a147_transitionReason m147 : 16|2@1+ (1,0) [0|0] "" Vector__XXX
 SG_ EPAS3P_a148_vehicleSpeed m148 : 16|10@1+ (0.5,0) [0|0] "" Vector__XXX
 SG_ EPAS3P_a149_pcbTemp m149 : 16|8@1- (1,60) [0|0] "" Vector__XXX
 SG_ EPAS3P_a150_pcbTemp m150 : 16|8@1- (1,60) [0|0] "" Vector__XXX
 SG_ EPAS3P_a151_dcsVBridge m151 : 16|6@1+ (0.328,0) [0|0] "" Vector__XXX
 SG_ EPAS3P_a152_dcsVBridge m152 : 16|6@1+ (0.328,0) [0|0] "" Vector__XXX
 SG_ EPAS3P_a153_dcsOffsetA m153 : 16|10@1- (1,0) [0|0] "" Vector__XXX
 SG_ EPAS3P_a154_vehicleSpeed m154 : 16|10@1+ (0.5,0) [0|0] "" Vector__XXX
 SG_ EPAS3P_a155_vehicleSpeed m155 : 16|10@1+ (0.5,0) [0|0] "" Vector__XXX
 SG_ EPAS3P_a156_vehicleSpeed m156 : 16|10@1+ (0.5,0) [0|0] "" Vector__XXX
 SG_ EPAS3P_a151_dcsMainChannelA m151 : 22|10@1- (0.41,0) [0|0] "" Vector__XXX
 SG_ EPAS3P_a152_dcsModIndex m152 : 23|7@1+ (1,0) [0|0] "" Vector__XXX
 SG_ EPAS3P_a132_motorTorqueInverse m132 : 24|8@1- (0.0787,0) [0|0] "" Vector__XXX
 SG_ EPAS3P_a133_motorTorqueInverse m133 : 24|8@1- (0.0787,0) [0|0] "" Vector__XXX
 SG_ EPAS3P_a134_motorTorqueInverse m134 : 24|8@1- (0.0787,0) [0|0] "" Vector__XXX
 SG_ EPAS3P_a135_iqReference m135 : 24|9@1- (0.78125,0) [0|0] "" Vector__XXX
 SG_ EPAS3P_a136_iqReference m136 : 24|9@1- (0.78125,0) [0|0] "" Vector__XXX
 SG_ EPAS3P_a137_iqReference m137 : 24|9@1- (0.78125,0) [0|0] "" Vector__XXX
 SG_ EPAS3P_a150_phaUMainPathCalcDiff m150 : 24|15@1+ (1,0) [0|0] "" Vector__XXX
 SG_ EPAS3P_a084_eacCancelTtrq m84 : 26|10@1+ (0.05,-25) [0|0] "" Vector__XXX
 SG_ EPAS3P_a153_dcsOffsetB m153 : 26|10@1- (1,0) [0|0] "" Vector__XXX
 SG_ EPAS3P_a152_dcsMainPathErrReg m152 : 30|11@1+ (1,0) [0|0] "" Vector__XXX
 SG_ EPAS3P_a132_idMeasured m132 : 32|8@1+ (0.787,0) [0|0] "" Vector__XXX
 SG_ EPAS3P_a133_idMeasured m133 : 32|8@1+ (0.787,0) [0|0] "" Vector__XXX
 SG_ EPAS3P_a134_idMeasured m134 : 32|8@1+ (0.787,0) [0|0] "" Vector__XXX
 SG_ EPAS3P_a151_dcsMainChannelB m151 : 32|10@1- (0.41,0) [0|0] "" Vector__XXX
 SG_ EPAS3P_a135_idMeasured m135 : 33|8@1+ (0.787,0) [0|0] "" Vector__XXX
 SG_ EPAS3P_a136_idMeasured m136 : 33|8@1+ (0.787,0) [0|0] "" Vector__XXX
 SG_ EPAS3P_a137_idMeasured m137 : 33|8@1+ (0.787,0) [0|0] "" Vector__XXX
 SG_ EPAS3P_a084_eacCancelAngleGrad m84 : 36|12@1+ (1,-2048) [0|0] "" Vector__XXX
 SG_ EPAS3P_a150_phaVMainPathCalcDiff m150 : 39|15@1+ (1,0) [0|0] "" Vector__XXX
 SG_ EPAS3P_a132_iqMeasured m132 : 40|9@1- (0.78125,0) [0|0] "" Vector__XXX
 SG_ EPAS3P_a133_iqMeasured m133 : 40|9@1- (0.78125,0) [0|0] "" Vector__XXX
 SG_ EPAS3P_a134_iqMeasured m134 : 40|9@1- (0.78125,0) [0|0] "" Vector__XXX
 SG_ EPAS3P_a135_iqMeasured m135 : 41|9@1- (0.78125,0) [0|0] "" Vector__XXX
 SG_ EPAS3P_a136_iqMeasured m136 : 41|9@1- (0.78125,0) [0|0] "" Vector__XXX
 SG_ EPAS3P_a137_iqMeasured m137 : 41|9@1- (0.78125,0) [0|0] "" Vector__XXX
 SG_ EPAS3P_a152_dcsTubErrReg m152 : 41|6@1+ (1,0) [0|0] "" Vector__XXX
 SG_ EPAS3P_a151_dcsOffsetA m151 : 42|10@1- (1,0) [0|0] "" Vector__XXX
 SG_ EPAS3P_a152_dcsErrSumReg m152 : 47|10@1+ (1,0) [0|0] "" Vector__XXX
 SG_ EPAS3P_a084_eacCancelAngle m84 : 48|12@1+ (1,-2048) [0|0] "" Vector__XXX
 SG_ EPAS3P_a132_motorVelocity m132 : 49|10@1- (0.9765625,0) [0|0] "" Vector__XXX
 SG_ EPAS3P_a133_motorVelocity m133 : 49|10@1- (0.9765625,0) [0|0] "" Vector__XXX
 SG_ EPAS3P_a134_motorVelocity m134 : 49|10@1- (0.9765625,0) [0|0] "" Vector__XXX
 SG_ EPAS3P_a135_motorVelocity m135 : 50|10@1- (0.9765625,0) [0|0] "" Vector__XXX
 SG_ EPAS3P_a136_motorVelocity m136 : 50|10@1- (0.9765625,0) [0|0] "" Vector__XXX
 SG_ EPAS3P_a137_motorVelocity m137 : 50|10@1- (0.9765625,0) [0|0] "" Vector__XXX
 SG_ EPAS3P_a151_dcsOffsetB m151 : 52|10@1- (1,0) [0|0] "" Vector__XXX
 SG_ EPAS3P_a150_otherECUAssistStatusFlag m150 : 54|1@1+ (1,0) [0|0] "" Vector__XXX
 SG_ EPAS3P_a152_dcsVbusDiagPathErrReg m152 : 57|7@1+ (1,0) [0|0] "" Vector__XXX
 SG_ EPAS3P_a084_eacCancelCode m84 : 60|4@1+ (1,0) [0|0] "" Vector__XXX
 SG_ EPAS3P_a151_dcsCBootA m151 : 62|1@1+ (1,0) [0|0] "" Vector__XXX
 SG_ EPAS3P_a151_dcsCBootB m151 : 63|1@1+ (1,0) [0|0] "" Vector__XXX

BO_ 1427 EPASTP_alertLog: 8 Vector__XXX
 SG_ EPASTP_alertID M : 0|9@1+ (1,0) [0|0] "" Vector__XXX
 SG_ EPASTP_alertState : 15|1@1+ (1,0) [0|0] "" Vector__XXX
 SG_ EPASTP_a001_debugInfo m1 : 16|48@1+ (1,0) [0|0] "" Vector__XXX
 SG_ EPASTP_a002_debugInfo m2 : 16|48@1+ (1,0) [0|0] "" Vector__XXX
 SG_ EPASTP_a003_debugInfo m3 : 16|48@1+ (1,0) [0|0] "" Vector__XXX
 SG_ EPASTP_a004_debugInfo m4 : 16|48@1+ (1,0) [0|0] "" Vector__XXX
 SG_ EPASTP_a005_debugInfo m5 : 16|48@1+ (1,0) [0|0] "" Vector__XXX
 SG_ EPASTP_a006_debugInfo m6 : 16|48@1+ (1,0) [0|0] "" Vector__XXX
 SG_ EPASTP_a007_debugInfo m7 : 16|48@1+ (1,0) [0|0] "" Vector__XXX
 SG_ EPASTP_a008_debugInfo m8 : 16|48@1+ (1,0) [0|0] "" Vector__XXX
 SG_ EPASTP_a009_debugInfo m9 : 16|48@1+ (1,0) [0|0] "" Vector__XXX
 SG_ EPASTP_a010_debugInfo m10 : 16|48@1+ (1,0) [0|0] "" Vector__XXX
 SG_ EPASTP_a011_debugInfo m11 : 16|48@1+ (1,0) [0|0] "" Vector__XXX
 SG_ EPASTP_a012_debugInfo m12 : 16|48@1+ (1,0) [0|0] "" Vector__XXX
 SG_ EPASTP_a013_debugInfo m13 : 16|48@1+ (1,0) [0|0] "" Vector__XXX
 SG_ EPASTP_a014_debugInfo m14 : 16|48@1+ (1,0) [0|0] "" Vector__XXX
 SG_ EPASTP_a015_debugInfo m15 : 16|48@1+ (1,0) [0|0] "" Vector__XXX
 SG_ EPASTP_a016_debugInfo m16 : 16|48@1+ (1,0) [0|0] "" Vector__XXX
 SG_ EPASTP_a017_debugInfo m17 : 16|48@1+ (1,0) [0|0] "" Vector__XXX
 SG_ EPASTP_a018_debugInfo m18 : 16|48@1+ (1,0) [0|0] "" Vector__XXX
 SG_ EPASTP_a019_debugInfo m19 : 16|48@1+ (1,0) [0|0] "" Vector__XXX
 SG_ EPASTP_a020_debugInfo m20 : 16|48@1+ (1,0) [0|0] "" Vector__XXX
 SG_ EPASTP_a021_debugInfo m21 : 16|48@1+ (1,0) [0|0] "" Vector__XXX
 SG_ EPASTP_a022_debugInfo m22 : 16|48@1+ (1,0) [0|0] "" Vector__XXX
 SG_ EPASTP_a023_debugInfo m23 : 16|48@1+ (1,0) [0|0] "" Vector__XXX
 SG_ EPASTP_a024_debugInfo m24 : 16|48@1+ (1,0) [0|0] "" Vector__XXX
 SG_ EPASTP_a025_debugInfo m25 : 16|48@1+ (1,0) [0|0] "" Vector__XXX
 SG_ EPASTP_a026_debugInfo m26 : 16|48@1+ (1,0) [0|0] "" Vector__XXX
 SG_ EPASTP_a027_debugInfo m27 : 16|48@1+ (1,0) [0|0] "" Vector__XXX
 SG_ EPASTP_a028_debugInfo m28 : 16|48@1+ (1,0) [0|0] "" Vector__XXX
 SG_ EPASTP_a029_debugInfo m29 : 16|48@1+ (1,0) [0|0] "" Vector__XXX
 SG_ EPASTP_a030_debugInfo m30 : 16|48@1+ (1,0) [0|0] "" Vector__XXX
 SG_ EPASTP_a031_debugInfo m31 : 16|48@1+ (1,0) [0|0] "" Vector__XXX
 SG_ EPASTP_a032_debugInfo m32 : 16|48@1+ (1,0) [0|0] "" Vector__XXX
 SG_ EPASTP_a033_debugInfo m33 : 16|48@1+ (1,0) [0|0] "" Vector__XXX
 SG_ EPASTP_a034_debugInfo m34 : 16|48@1+ (1,0) [0|0] "" Vector__XXX
 SG_ EPASTP_a035_debugInfo m35 : 16|48@1+ (1,0) [0|0] "" Vector__XXX
 SG_ EPASTP_a036_debugInfo m36 : 16|48@1+ (1,0) [0|0] "" Vector__XXX
 SG_ EPASTP_a037_debugInfo m37 : 16|48@1+ (1,0) [0|0] "" Vector__XXX
 SG_ EPASTP_a038_debugInfo m38 : 16|48@1+ (1,0) [0|0] "" Vector__XXX
 SG_ EPASTP_a039_debugInfo m39 : 16|48@1+ (1,0) [0|0] "" Vector__XXX
 SG_ EPASTP_a040_debugInfo m40 : 16|48@1+ (1,0) [0|0] "" Vector__XXX
 SG_ EPASTP_a041_debugInfo m41 : 16|48@1+ (1,0) [0|0] "" Vector__XXX
 SG_ EPASTP_a042_debugInfo m42 : 16|48@1+ (1,0) [0|0] "" Vector__XXX
 SG_ EPASTP_a043_debugInfo m43 : 16|48@1+ (1,0) [0|0] "" Vector__XXX
 SG_ EPASTP_a044_debugInfo m44 : 16|48@1+ (1,0) [0|0] "" Vector__XXX
 SG_ EPASTP_a045_debugInfo m45 : 16|48@1+ (1,0) [0|0] "" Vector__XXX
 SG_ EPASTP_a046_debugInfo m46 : 16|48@1+ (1,0) [0|0] "" Vector__XXX
 SG_ EPASTP_a047_debugInfo m47 : 16|48@1+ (1,0) [0|0] "" Vector__XXX
 SG_ EPASTP_a048_debugInfo m48 : 16|48@1+ (1,0) [0|0] "" Vector__XXX
 SG_ EPASTP_a049_debugInfo m49 : 16|48@1+ (1,0) [0|0] "" Vector__XXX
 SG_ EPASTP_a050_debugInfo m50 : 16|48@1+ (1,0) [0|0] "" Vector__XXX
 SG_ EPASTP_a051_debugInfo m51 : 16|48@1+ (1,0) [0|0] "" Vector__XXX
 SG_ EPASTP_a052_debugInfo m52 : 16|48@1+ (1,0) [0|0] "" Vector__XXX
 SG_ EPASTP_a053_debugInfo m53 : 16|48@1+ (1,0) [0|0] "" Vector__XXX
 SG_ EPASTP_a054_debugInfo m54 : 16|48@1+ (1,0) [0|0] "" Vector__XXX
 SG_ EPASTP_a055_debugInfo m55 : 16|48@1+ (1,0) [0|0] "" Vector__XXX
 SG_ EPASTP_a056_debugInfo m56 : 16|48@1+ (1,0) [0|0] "" Vector__XXX
 SG_ EPASTP_a057_debugInfo m57 : 16|48@1+ (1,0) [0|0] "" Vector__XXX
 SG_ EPASTP_a058_debugInfo m58 : 16|48@1+ (1,0) [0|0] "" Vector__XXX
 SG_ EPASTP_a059_debugInfo m59 : 16|48@1+ (1,0) [0|0] "" Vector__XXX
 SG_ EPASTP_a060_debugInfo m60 : 16|48@1+ (1,0) [0|0] "" Vector__XXX
 SG_ EPASTP_a061_debugInfo m61 : 16|48@1+ (1,0) [0|0] "" Vector__XXX
 SG_ EPASTP_a062_debugInfo m62 : 16|48@1+ (1,0) [0|0] "" Vector__XXX
 SG_ EPASTP_a063_debugInfo m63 : 16|48@1+ (1,0) [0|0] "" Vector__XXX
 SG_ EPASTP_a064_debugInfo m64 : 16|48@1+ (1,0) [0|0] "" Vector__XXX
 SG_ EPASTP_a065_debugInfo m65 : 16|48@1+ (1,0) [0|0] "" Vector__XXX
 SG_ EPASTP_a066_debugInfo m66 : 16|48@1+ (1,0) [0|0] "" Vector__XXX
 SG_ EPASTP_a067_debugInfo m67 : 16|48@1+ (1,0) [0|0] "" Vector__XXX
 SG_ EPASTP_a068_debugInfo m68 : 16|48@1+ (1,0) [0|0] "" Vector__XXX
 SG_ EPASTP_a069_debugInfo m69 : 16|48@1+ (1,0) [0|0] "" Vector__XXX
 SG_ EPASTP_a070_debugInfo m70 : 16|48@1+ (1,0) [0|0] "" Vector__XXX
 SG_ EPASTP_a071_debugInfo m71 : 16|48@1+ (1,0) [0|0] "" Vector__XXX
 SG_ EPASTP_a072_debugInfo m72 : 16|48@1+ (1,0) [0|0] "" Vector__XXX
 SG_ EPASTP_a073_debugInfo m73 : 16|48@1+ (1,0) [0|0] "" Vector__XXX
 SG_ EPASTP_a074_debugInfo m74 : 16|48@1+ (1,0) [0|0] "" Vector__XXX
 SG_ EPASTP_a075_debugInfo m75 : 16|48@1+ (1,0) [0|0] "" Vector__XXX
 SG_ EPASTP_a076_debugInfo m76 : 16|48@1+ (1,0) [0|0] "" Vector__XXX
 SG_ EPASTP_a077_debugInfo m77 : 16|48@1+ (1,0) [0|0] "" Vector__XXX
 SG_ EPASTP_a078_debugInfo m78 : 16|48@1+ (1,0) [0|0] "" Vector__XXX
 SG_ EPASTP_a079_debugInfo m79 : 16|48@1+ (1,0) [0|0] "" Vector__XXX
 SG_ EPASTP_a080_debugInfo m80 : 16|48@1+ (1,0) [0|0] "" Vector__XXX
 SG_ EPASTP_a081_debugInfo m81 : 16|48@1+ (1,0) [0|0] "" Vector__XXX
 SG_ EPASTP_a082_debugInfo m82 : 16|48@1+ (1,0) [0|0] "" Vector__XXX
 SG_ EPASTP_a083_debugInfo m83 : 16|48@1+ (1,0) [0|0] "" Vector__XXX
 SG_ EPASTP_a084_debugInfo m84 : 16|48@1+ (1,0) [0|0] "" Vector__XXX
 SG_ EPASTP_a085_debugInfo m85 : 16|48@1+ (1,0) [0|0] "" Vector__XXX
 SG_ EPASTP_a086_debugInfo m86 : 16|48@1+ (1,0) [0|0] "" Vector__XXX
 SG_ EPASTP_a087_debugInfo m87 : 16|48@1+ (1,0) [0|0] "" Vector__XXX
 SG_ EPASTP_a088_debugInfo m88 : 16|48@1+ (1,0) [0|0] "" Vector__XXX
 SG_ EPASTP_a089_debugInfo m89 : 16|48@1+ (1,0) [0|0] "" Vector__XXX
 SG_ EPASTP_a090_debugInfo m90 : 16|48@1+ (1,0) [0|0] "" Vector__XXX
 SG_ EPASTP_a091_debugInfo m91 : 16|48@1+ (1,0) [0|0] "" Vector__XXX
 SG_ EPASTP_a092_debugInfo m92 : 16|48@1+ (1,0) [0|0] "" Vector__XXX
 SG_ EPASTP_a093_debugInfo m93 : 16|48@1+ (1,0) [0|0] "" Vector__XXX
 SG_ EPASTP_a094_debugInfo m94 : 16|48@1+ (1,0) [0|0] "" Vector__XXX
 SG_ EPASTP_a095_debugInfo m95 : 16|48@1+ (1,0) [0|0] "" Vector__XXX
 SG_ EPASTP_a096_debugInfo m96 : 16|48@1+ (1,0) [0|0] "" Vector__XXX
 SG_ EPASTP_a097_debugInfo m97 : 16|48@1+ (1,0) [0|0] "" Vector__XXX
 SG_ EPASTP_a098_debugInfo m98 : 16|48@1+ (1,0) [0|0] "" Vector__XXX
 SG_ EPASTP_a099_debugInfo m99 : 16|48@1+ (1,0) [0|0] "" Vector__XXX
 SG_ EPASTP_a100_debugInfo m100 : 16|48@1+ (1,0) [0|0] "" Vector__XXX
 SG_ EPASTP_a101_debugInfo m101 : 16|48@1+ (1,0) [0|0] "" Vector__XXX
 SG_ EPASTP_a102_debugInfo m102 : 16|48@1+ (1,0) [0|0] "" Vector__XXX
 SG_ EPASTP_a103_debugInfo m103 : 16|48@1+ (1,0) [0|0] "" Vector__XXX
 SG_ EPASTP_a104_debugInfo m104 : 16|48@1+ (1,0) [0|0] "" Vector__XXX
 SG_ EPASTP_a105_debugInfo m105 : 16|48@1+ (1,0) [0|0] "" Vector__XXX
 SG_ EPASTP_a106_debugInfo m106 : 16|48@1+ (1,0) [0|0] "" Vector__XXX
 SG_ EPASTP_a107_debugInfo m107 : 16|48@1+ (1,0) [0|0] "" Vector__XXX
 SG_ EPASTP_a108_debugInfo m108 : 16|48@1+ (1,0) [0|0] "" Vector__XXX
 SG_ EPASTP_a109_debugInfo m109 : 16|48@1+ (1,0) [0|0] "" Vector__XXX
 SG_ EPASTP_a110_debugInfo m110 : 16|48@1+ (1,0) [0|0] "" Vector__XXX
 SG_ EPASTP_a111_debugInfo m111 : 16|48@1+ (1,0) [0|0] "" Vector__XXX
 SG_ EPASTP_a112_debugInfo m112 : 16|48@1+ (1,0) [0|0] "" Vector__XXX
 SG_ EPASTP_a113_debugInfo m113 : 16|48@1+ (1,0) [0|0] "" Vector__XXX
 SG_ EPASTP_a114_debugInfo m114 : 16|48@1+ (1,0) [0|0] "" Vector__XXX
 SG_ EPASTP_a115_debugInfo m115 : 16|48@1+ (1,0) [0|0] "" Vector__XXX
 SG_ EPASTP_a116_debugInfo m116 : 16|48@1+ (1,0) [0|0] "" Vector__XXX
 SG_ EPASTP_a117_debugInfo m117 : 16|48@1+ (1,0) [0|0] "" Vector__XXX
 SG_ EPASTP_a118_debugInfo m118 : 16|48@1+ (1,0) [0|0] "" Vector__XXX
 SG_ EPASTP_a119_debugInfo m119 : 16|48@1+ (1,0) [0|0] "" Vector__XXX
 SG_ EPASTP_a120_debugInfo m120 : 16|48@1+ (1,0) [0|0] "" Vector__XXX
 SG_ EPASTP_a121_debugInfo m121 : 16|48@1+ (1,0) [0|0] "" Vector__XXX
 SG_ EPASTP_a122_debugInfo m122 : 16|48@1+ (1,0) [0|0] "" Vector__XXX
 SG_ EPASTP_a123_debugInfo m123 : 16|48@1+ (1,0) [0|0] "" Vector__XXX
 SG_ EPASTP_a124_debugInfo m124 : 16|48@1+ (1,0) [0|0] "" Vector__XXX
 SG_ EPASTP_a125_debugInfo m125 : 16|48@1+ (1,0) [0|0] "" Vector__XXX
 SG_ EPASTP_a126_debugInfo m126 : 16|48@1+ (1,0) [0|0] "" Vector__XXX
 SG_ EPASTP_a127_debugInfo m127 : 16|48@1+ (1,0) [0|0] "" Vector__XXX
 SG_ EPASTP_a128_debugInfo m128 : 16|48@1+ (1,0) [0|0] "" Vector__XXX
 SG_ EPASTP_a129_debugInfo m129 : 16|48@1+ (1,0) [0|0] "" Vector__XXX
 SG_ EPASTP_a130_debugInfo m130 : 16|48@1+ (1,0) [0|0] "" Vector__XXX
 SG_ EPASTP_a131_debugInfo m131 : 16|48@1+ (1,0) [0|0] "" Vector__XXX
 SG_ EPASTP_a132_debugInfo m132 : 16|48@1+ (1,0) [0|0] "" Vector__XXX
 SG_ EPASTP_a133_debugInfo m133 : 16|48@1+ (1,0) [0|0] "" Vector__XXX
 SG_ EPASTP_a134_debugInfo m134 : 16|48@1+ (1,0) [0|0] "" Vector__XXX
 SG_ EPASTP_a135_debugInfo m135 : 16|48@1+ (1,0) [0|0] "" Vector__XXX
 SG_ EPASTP_a136_debugInfo m136 : 16|48@1+ (1,0) [0|0] "" Vector__XXX
 SG_ EPASTP_a137_debugInfo m137 : 16|48@1+ (1,0) [0|0] "" Vector__XXX
 SG_ EPASTP_a138_debugInfo m138 : 16|48@1+ (1,0) [0|0] "" Vector__XXX
 SG_ EPASTP_a139_debugInfo m139 : 16|48@1+ (1,0) [0|0] "" Vector__XXX
 SG_ EPASTP_a140_debugInfo m140 : 16|48@1+ (1,0) [0|0] "" Vector__XXX
 SG_ EPASTP_a141_debugInfo m141 : 16|48@1+ (1,0) [0|0] "" Vector__XXX
 SG_ EPASTP_a142_debugInfo m142 : 16|48@1+ (1,0) [0|0] "" Vector__XXX
 SG_ EPASTP_a143_debugInfo m143 : 16|48@1+ (1,0) [0|0] "" Vector__XXX
 SG_ EPASTP_a144_debugInfo m144 : 16|48@1+ (1,0) [0|0] "" Vector__XXX
 SG_ EPASTP_a145_debugInfo m145 : 16|48@1+ (1,0) [0|0] "" Vector__XXX
 SG_ EPASTP_a146_debugInfo m146 : 16|48@1+ (1,0) [0|0] "" Vector__XXX
 SG_ EPASTP_a147_debugInfo m147 : 16|48@1+ (1,0) [0|0] "" Vector__XXX
 SG_ EPASTP_a148_debugInfo m148 : 16|48@1+ (1,0) [0|0] "" Vector__XXX
 SG_ EPASTP_a149_debugInfo m149 : 16|48@1+ (1,0) [0|0] "" Vector__XXX
 SG_ EPASTP_a150_debugInfo m150 : 16|48@1+ (1,0) [0|0] "" Vector__XXX
 SG_ EPASTP_a151_debugInfo m151 : 16|48@1+ (1,0) [0|0] "" Vector__XXX
 SG_ EPASTP_a152_debugInfo m152 : 16|48@1+ (1,0) [0|0] "" Vector__XXX
 SG_ EPASTP_a153_debugInfo m153 : 16|48@1+ (1,0) [0|0] "" Vector__XXX
 SG_ EPASTP_a154_debugInfo m154 : 16|48@1+ (1,0) [0|0] "" Vector__XXX
 SG_ EPASTP_a155_debugInfo m155 : 16|48@1+ (1,0) [0|0] "" Vector__XXX
 SG_ EPASTP_a156_debugInfo m156 : 16|48@1+ (1,0) [0|0] "" Vector__XXX
 SG_ EPASTP_a157_debugInfo m157 : 16|48@1+ (1,0) [0|0] "" Vector__XXX
 SG_ EPASTP_a158_debugInfo m158 : 16|48@1+ (1,0) [0|0] "" Vector__XXX
 SG_ EPASTP_a159_debugInfo m159 : 16|48@1+ (1,0) [0|0] "" Vector__XXX
 SG_ EPASTP_a160_debugInfo m160 : 16|48@1+ (1,0) [0|0] "" Vector__XXX
 SG_ EPASTP_a161_debugInfo m161 : 16|48@1+ (1,0) [0|0] "" Vector__XXX
 SG_ EPASTP_a162_debugInfo m162 : 16|48@1+ (1,0) [0|0] "" Vector__XXX
 SG_ EPASTP_a163_debugInfo m163 : 16|48@1+ (1,0) [0|0] "" Vector__XXX
 SG_ EPASTP_a164_debugInfo m164 : 16|48@1+ (1,0) [0|0] "" Vector__XXX
 SG_ EPASTP_a165_debugInfo m165 : 16|48@1+ (1,0) [0|0] "" Vector__XXX
 SG_ EPASTP_a166_debugInfo m166 : 16|48@1+ (1,0) [0|0] "" Vector__XXX
 SG_ EPASTP_a167_debugInfo m167 : 16|48@1+ (1,0) [0|0] "" Vector__XXX
 SG_ EPASTP_a168_debugInfo m168 : 16|48@1+ (1,0) [0|0] "" Vector__XXX
 SG_ EPASTP_a169_debugInfo m169 : 16|48@1+ (1,0) [0|0] "" Vector__XXX
 SG_ EPASTP_a170_debugInfo m170 : 16|48@1+ (1,0) [0|0] "" Vector__XXX
 SG_ EPASTP_a171_debugInfo m171 : 16|48@1+ (1,0) [0|0] "" Vector__XXX
 SG_ EPASTP_a172_debugInfo m172 : 16|48@1+ (1,0) [0|0] "" Vector__XXX
 SG_ EPASTP_a173_debugInfo m173 : 16|48@1+ (1,0) [0|0] "" Vector__XXX
 SG_ EPASTP_a174_debugInfo m174 : 16|48@1+ (1,0) [0|0] "" Vector__XXX
 SG_ EPASTP_a175_debugInfo m175 : 16|48@1+ (1,0) [0|0] "" Vector__XXX
 SG_ EPASTP_a176_debugInfo m176 : 16|48@1+ (1,0) [0|0] "" Vector__XXX
 SG_ EPASTP_a177_debugInfo m177 : 16|48@1+ (1,0) [0|0] "" Vector__XXX
 SG_ EPASTP_a178_debugInfo m178 : 16|48@1+ (1,0) [0|0] "" Vector__XXX
 SG_ EPASTP_a179_debugInfo m179 : 16|48@1+ (1,0) [0|0] "" Vector__XXX
 SG_ EPASTP_a180_debugInfo m180 : 16|48@1+ (1,0) [0|0] "" Vector__XXX
 SG_ EPASTP_a181_debugInfo m181 : 16|48@1+ (1,0) [0|0] "" Vector__XXX
 SG_ EPASTP_a182_debugInfo m182 : 16|48@1+ (1,0) [0|0] "" Vector__XXX
 SG_ EPASTP_a183_debugInfo m183 : 16|48@1+ (1,0) [0|0] "" Vector__XXX
 SG_ EPASTP_a184_debugInfo m184 : 16|48@1+ (1,0) [0|0] "" Vector__XXX
 SG_ EPASTP_a185_debugInfo m185 : 16|48@1+ (1,0) [0|0] "" Vector__XXX
 SG_ EPASTP_a186_debugInfo m186 : 16|48@1+ (1,0) [0|0] "" Vector__XXX
 SG_ EPASTP_a187_debugInfo m187 : 16|48@1+ (1,0) [0|0] "" Vector__XXX
 SG_ EPASTP_a188_debugInfo m188 : 16|48@1+ (1,0) [0|0] "" Vector__XXX
 SG_ EPASTP_a189_debugInfo m189 : 16|48@1+ (1,0) [0|0] "" Vector__XXX
 SG_ EPASTP_a190_debugInfo m190 : 16|48@1+ (1,0) [0|0] "" Vector__XXX
 SG_ EPASTP_a191_debugInfo m191 : 16|48@1+ (1,0) [0|0] "" Vector__XXX
 SG_ EPASTP_a192_debugInfo m192 : 16|48@1+ (1,0) [0|0] "" Vector__XXX
 SG_ EPASTP_a193_debugInfo m193 : 16|48@1+ (1,0) [0|0] "" Vector__XXX
 SG_ EPASTP_a194_debugInfo m194 : 16|48@1+ (1,0) [0|0] "" Vector__XXX
 SG_ EPASTP_a195_debugInfo m195 : 16|48@1+ (1,0) [0|0] "" Vector__XXX
 SG_ EPASTP_a196_debugInfo m196 : 16|48@1+ (1,0) [0|0] "" Vector__XXX
 SG_ EPASTP_a197_debugInfo m197 : 16|48@1+ (1,0) [0|0] "" Vector__XXX
 SG_ EPASTP_a198_debugInfo m198 : 16|48@1+ (1,0) [0|0] "" Vector__XXX
 SG_ EPASTP_a199_debugInfo m199 : 16|48@1+ (1,0) [0|0] "" Vector__XXX
 SG_ EPASTP_a200_debugInfo m200 : 16|48@1+ (1,0) [0|0] "" Vector__XXX
 SG_ EPASTP_a201_debugInfo m201 : 16|48@1+ (1,0) [0|0] "" Vector__XXX
 SG_ EPASTP_a202_debugInfo m202 : 16|48@1+ (1,0) [0|0] "" Vector__XXX
 SG_ EPASTP_a203_debugInfo m203 : 16|48@1+ (1,0) [0|0] "" Vector__XXX
 SG_ EPASTP_a204_debugInfo m204 : 16|48@1+ (1,0) [0|0] "" Vector__XXX
 SG_ EPASTP_a205_debugInfo m205 : 16|48@1+ (1,0) [0|0] "" Vector__XXX
 SG_ EPASTP_a206_debugInfo m206 : 16|48@1+ (1,0) [0|0] "" Vector__XXX
 SG_ EPASTP_a207_debugInfo m207 : 16|48@1+ (1,0) [0|0] "" Vector__XXX
 SG_ EPASTP_a208_debugInfo m208 : 16|48@1+ (1,0) [0|0] "" Vector__XXX
 SG_ EPASTP_a209_debugInfo m209 : 16|48@1+ (1,0) [0|0] "" Vector__XXX
 SG_ EPASTP_a210_debugInfo m210 : 16|48@1+ (1,0) [0|0] "" Vector__XXX
 SG_ EPASTP_a211_debugInfo m211 : 16|48@1+ (1,0) [0|0] "" Vector__XXX
 SG_ EPASTP_a212_debugInfo m212 : 16|48@1+ (1,0) [0|0] "" Vector__XXX
 SG_ EPASTP_a213_debugInfo m213 : 16|48@1+ (1,0) [0|0] "" Vector__XXX
 SG_ EPASTP_a214_debugInfo m214 : 16|48@1+ (1,0) [0|0] "" Vector__XXX
 SG_ EPASTP_a215_debugInfo m215 : 16|48@1+ (1,0) [0|0] "" Vector__XXX
 SG_ EPASTP_a216_debugInfo m216 : 16|48@1+ (1,0) [0|0] "" Vector__XXX
 SG_ EPASTP_a217_debugInfo m217 : 16|48@1+ (1,0) [0|0] "" Vector__XXX
 SG_ EPASTP_a218_debugInfo m218 : 16|48@1+ (1,0) [0|0] "" Vector__XXX
 SG_ EPASTP_a219_debugInfo m219 : 16|48@1+ (1,0) [0|0] "" Vector__XXX
 SG_ EPASTP_a221_debugInfo m221 : 16|48@1+ (1,0) [0|0] "" Vector__XXX
 SG_ EPASTP_a222_debugInfo m222 : 16|48@1+ (1,0) [0|0] "" Vector__XXX
 SG_ EPASTP_a223_debugInfo m223 : 16|48@1+ (1,0) [0|0] "" Vector__XXX
 SG_ EPASTP_a224_debugInfo m224 : 16|48@1+ (1,0) [0|0] "" Vector__XXX
 SG_ EPASTP_a225_debugInfo m225 : 16|48@1+ (1,0) [0|0] "" Vector__XXX
 SG_ EPASTP_a226_debugInfo m226 : 16|48@1+ (1,0) [0|0] "" Vector__XXX
 SG_ EPASTP_a227_debugInfo m227 : 16|48@1+ (1,0) [0|0] "" Vector__XXX
 SG_ EPASTP_a228_debugInfo m228 : 16|48@1+ (1,0) [0|0] "" Vector__XXX
 SG_ EPASTP_a229_debugInfo m229 : 16|48@1+ (1,0) [0|0] "" Vector__XXX
 SG_ EPASTP_a230_debugInfo m230 : 16|48@1+ (1,0) [0|0] "" Vector__XXX
 SG_ EPASTP_a231_debugInfo m231 : 16|48@1+ (1,0) [0|0] "" Vector__XXX
 SG_ EPASTP_a232_debugInfo m232 : 16|48@1+ (1,0) [0|0] "" Vector__XXX
 SG_ EPASTP_a233_debugInfo m233 : 16|48@1+ (1,0) [0|0] "" Vector__XXX
 SG_ EPASTP_a234_debugInfo m234 : 16|48@1+ (1,0) [0|0] "" Vector__XXX
 SG_ EPASTP_a235_debugInfo m235 : 16|48@1+ (1,0) [0|0] "" Vector__XXX
 SG_ EPASTP_a236_debugInfo m236 : 16|48@1+ (1,0) [0|0] "" Vector__XXX
 SG_ EPASTP_a237_debugInfo m237 : 16|48@1+ (1,0) [0|0] "" Vector__XXX
 SG_ EPASTP_a238_debugInfo m238 : 16|48@1+ (1,0) [0|0] "" Vector__XXX
 SG_ EPASTP_a239_debugInfo m239 : 16|48@1+ (1,0) [0|0] "" Vector__XXX
 SG_ EPASTP_a240_debugInfo m240 : 16|48@1+ (1,0) [0|0] "" Vector__XXX
 SG_ EPASTP_a241_debugInfo m241 : 16|48@1+ (1,0) [0|0] "" Vector__XXX
 SG_ EPASTP_a242_debugInfo m242 : 16|48@1+ (1,0) [0|0] "" Vector__XXX
 SG_ EPASTP_a243_debugInfo m243 : 16|48@1+ (1,0) [0|0] "" Vector__XXX
 SG_ EPASTP_a244_debugInfo m244 : 16|48@1+ (1,0) [0|0] "" Vector__XXX
 SG_ EPASTP_a245_debugInfo m245 : 16|48@1+ (1,0) [0|0] "" Vector__XXX
 SG_ EPASTP_a246_debugInfo m246 : 16|48@1+ (1,0) [0|0] "" Vector__XXX
 SG_ EPASTP_a247_debugInfo m247 : 16|48@1+ (1,0) [0|0] "" Vector__XXX
 SG_ EPASTP_a248_debugInfo m248 : 16|48@1+ (1,0) [0|0] "" Vector__XXX
 SG_ EPASTP_a249_debugInfo m249 : 16|48@1+ (1,0) [0|0] "" Vector__XXX
 SG_ EPASTP_a250_debugInfo m250 : 16|48@1+ (1,0) [0|0] "" Vector__XXX
 SG_ EPASTP_a251_debugInfo m251 : 16|48@1+ (1,0) [0|0] "" Vector__XXX
 SG_ EPASTP_a252_debugInfo m252 : 16|48@1+ (1,0) [0|0] "" Vector__XXX
 SG_ EPASTP_a253_debugInfo m253 : 16|48@1+ (1,0) [0|0] "" Vector__XXX
 SG_ EPASTP_a254_debugInfo m254 : 16|48@1+ (1,0) [0|0] "" Vector__XXX
 SG_ EPASTP_a255_debugInfo m255 : 16|48@1+ (1,0) [0|0] "" Vector__XXX
 SG_ EPASTP_a256_debugInfo m256 : 16|48@1+ (1,0) [0|0] "" Vector__XXX
 SG_ EPASTP_a257_debugInfo m257 : 16|48@1+ (1,0) [0|0] "" Vector__XXX
 SG_ EPASTP_a258_debugInfo m258 : 16|48@1+ (1,0) [0|0] "" Vector__XXX
 SG_ EPASTP_a259_debugInfo m259 : 16|48@1+ (1,0) [0|0] "" Vector__XXX
 SG_ EPASTP_a260_debugInfo m260 : 16|48@1+ (1,0) [0|0] "" Vector__XXX
 SG_ EPASTP_a261_debugInfo m261 : 16|48@1+ (1,0) [0|0] "" Vector__XXX
 SG_ EPASTP_a262_debugInfo m262 : 16|48@1+ (1,0) [0|0] "" Vector__XXX
 SG_ EPASTP_a263_debugInfo m263 : 16|48@1+ (1,0) [0|0] "" Vector__XXX
 SG_ EPASTP_a264_degradedECU m264 : 16|8@1+ (1,0) [0|0] "" Vector__XXX
 SG_ EPASTP_a265_degradedECU m265 : 16|8@1+ (1,0) [0|0] "" Vector__XXX
 SG_ EPASTP_a266_cdpAssistFactor m266 : 16|8@1+ (1,0) [0|0] "" Vector__XXX
 SG_ EPASTP_a267_vehicleSpeed m267 : 16|16@1+ (0.1,0) [0|0] "" Vector__XXX
 SG_ EPASTP_a268_vehicleSpeed m268 : 16|16@1+ (0.1,0) [0|0] "" Vector__XXX
 SG_ EPASTP_a269_vehicleSpeed m269 : 16|16@1+ (0.1,0) [0|0] "" Vector__XXX
 SG_ EPASTP_a270_debugInfo m270 : 16|48@1+ (1,0) [0|0] "" Vector__XXX
 SG_ EPASTP_a264_vehicleSpeed m264 : 24|16@1+ (0.1,0) [0|0] "" Vector__XXX
 SG_ EPASTP_a265_vehicleSpeed m265 : 24|16@1+ (0.1,0) [0|0] "" Vector__XXX
 SG_ EPASTP_a266_vehicleSpeed m266 : 24|16@1+ (0.1,0) [0|0] "" Vector__XXX
 SG_ EPASTP_a267_velocityEstimatorState m267 : 32|8@1+ (1,0) [0|0] "" Vector__XXX
 SG_ EPASTP_a268_torsionBarTorque m268 : 32|8@1+ (0.1,-12) [0|0] "" Vector__XXX
 SG_ EPASTP_a264_powerRatio m264 : 40|8@1+ (1,0) [0|0] "" Vector__XXX
 SG_ EPASTP_a265_rawMcuTemperature m265 : 40|16@1+ (1,-100) [0|0] "" Vector__XXX
 SG_ EPASTP_a268_eacErrorCode m268 : 40|8@1+ (1,0) [0|0] "" Vector__XXX
 SG_ EPASTP_a264_ownSideDegradationReason m264 : 48|8@1+ (1,0) [0|0] "" Vector__XXX
 SG_ EPASTP_a268_pinionAngleSpeed m268 : 48|16@1+ (1,-3000) [0|0] "" Vector__XXX
 SG_ EPASTP_a264_otherSideDegradationReason m264 : 56|8@1+ (1,0) [0|0] "" Vector__XXX
 SG_ EPASTP_a265_degradedCurrentLimit m265 : 56|8@1+ (1,0) [0|0] "" Vector__XXX

BO_ 1488 APS_cpuStats: 8 Vector__XXX
 SG_ APS_A_totalCpuUtilization : 0|7@1+ (1,0) [0|0] "" Vector__XXX

BO_ 1492 APS_A_powerStateTrace: 8 Vector__XXX
 SG_ APS_A_powerTrace1 : 0|5@1+ (1,0) [0|0] "" Vector__XXX
 SG_ APS_A_powerTrace2 : 8|5@1+ (1,0) [0|0] "" Vector__XXX
 SG_ APS_A_powerTrace3 : 16|5@1+ (1,0) [0|0] "" Vector__XXX
 SG_ APS_A_powerTrace4 : 24|5@1+ (1,0) [0|0] "" Vector__XXX
 SG_ APS_A_powerTrace5 : 32|5@1+ (1,0) [0|0] "" Vector__XXX
 SG_ APS_A_powerTrace6 : 40|5@1+ (1,0) [0|0] "" Vector__XXX
 SG_ APS_A_powerTrace7 : 48|5@1+ (1,0) [0|0] "" Vector__XXX
 SG_ APS_A_powerTrace8 : 56|5@1+ (1,0) [0|0] "" Vector__XXX

BO_ 1493 DIR_statistics: 8 Vector__XXX
 SG_ DIR_torqueEstimated : 0|13@1- (2,0) [0|0] "" Vector__XXX
 SG_ DIR_torqueErrorEstimated : 13|11@1- (0.1,0) [0|0] "" Vector__XXX

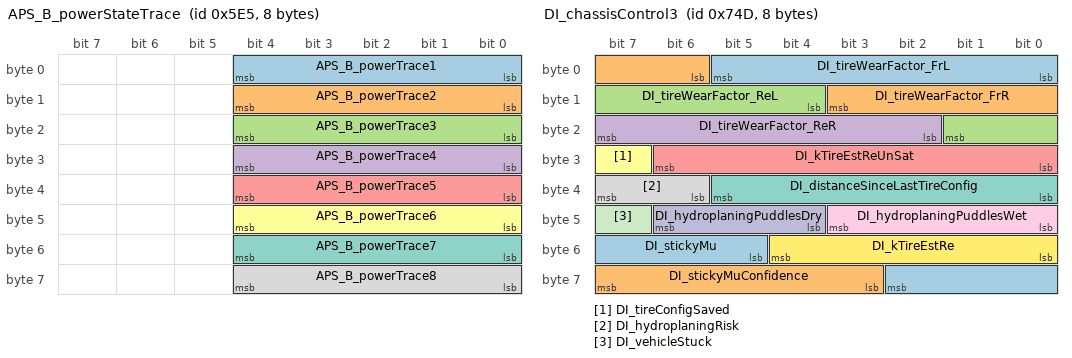
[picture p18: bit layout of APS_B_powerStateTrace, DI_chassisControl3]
BO_ 1509 APS_B_powerStateTrace: 8 Vector__XXX
 SG_ APS_B_powerTrace1 : 0|5@1+ (1,0) [0|0] "" Vector__XXX
 SG_ APS_B_powerTrace2 : 8|5@1+ (1,0) [0|0] "" Vector__XXX
 SG_ APS_B_powerTrace3 : 16|5@1+ (1,0) [0|0] "" Vector__XXX
 SG_ APS_B_powerTrace4 : 24|5@1+ (1,0) [0|0] "" Vector__XXX
 SG_ APS_B_powerTrace5 : 32|5@1+ (1,0) [0|0] "" Vector__XXX
 SG_ APS_B_powerTrace6 : 40|5@1+ (1,0) [0|0] "" Vector__XXX
 SG_ APS_B_powerTrace7 : 48|5@1+ (1,0) [0|0] "" Vector__XXX
 SG_ APS_B_powerTrace8 : 56|5@1+ (1,0) [0|0] "" Vector__XXX

BO_ 1618 VCBATT0_info: 8 Vector__XXX
 SG_ VCBATT0_infoIndex M : 0|8@1+ (1,0) [0|0] "" Vector__XXX
 SG_ VCBATT0_infoAppCrc m13 : 8|32@1+ (1,0) [0|0] "" Vector__XXX
 SG_ VCBATT0_infoAppGitHash m17 : 8|56@1+ (1,0) [0|0] "" Vector__XXX
 SG_ VCBATT0_infoBootGitHash m18 : 8|56@1+ (1,0) [0|0] "" Vector__XXX
 SG_ VCBATT0_infoBootUdsProtoVersion m20 : 8|16@1+ (1,0) [0|0] "" Vector__XXX
 SG_ VCBATT0_infoBuildType m10 : 8|3@1+ (1,0) [0|0] "" Vector__XXX
 SG_ VCBATT0_infoPcbaId m11 : 8|8@1+ (1,0) [0|0] "" Vector__XXX
 SG_ VCBATT0_infoPlatformType m19 : 8|8@1+ (1,0) [0|0] "" Vector__XXX
 SG_ VCBATT0_infoAssemblyId m11 : 16|8@1+ (1,0) [0|0] "" Vector__XXX
 SG_ VCBATT0_infoBuildConfigId m10 : 16|16@1+ (1,0) [0|0] "" Vector__XXX
 SG_ VCBATT0_infoBootCrc m20 : 24|32@1+ (1,0) [0|0] "" Vector__XXX
 SG_ VCBATT0_infoUsageId m11 : 24|16@1+ (1,0) [0|0] "" Vector__XXX
 SG_ VCBATT0_infoHardwareId m10 : 32|16@1+ (1,0) [0|0] "" Vector__XXX
 SG_ VCBATT0_infoSubcomponent1 m16 : 32|32@1+ (1,0) [0|0] "" Vector__XXX
 SG_ VCBATT0_infoSubcomponent2 m23 : 32|32@1+ (1,0) [0|0] "" Vector__XXX
 SG_ VCBATT0_infoSubcomponent3 m24 : 32|32@1+ (1,0) [0|0] "" Vector__XXX
 SG_ VCBATT0_infoSubcomponent4 m31 : 32|32@1+ (1,0) [0|0] "" Vector__XXX
 SG_ VCBATT0_infoSubcomponent5 m32 : 32|32@1+ (1,0) [0|0] "" Vector__XXX
 SG_ VCBATT0_infoSubcomponent6 m33 : 32|32@1+ (1,0) [0|0] "" Vector__XXX
 SG_ VCBATT0_infoSubUsageId m11 : 40|16@1+ (1,0) [0|0] "" Vector__XXX
 SG_ VCBATT0_infoComponentId m10 : 48|16@1+ (1,0) [0|0] "" Vector__XXX

BO_ 1637 XCP_epasRequest: 8 Vector__XXX
 SG_ XCP_epasRequestData : 7|64@0+ (1,0) [0|0] "" Vector__XXX

BO_ 1639 EPAS3P_xcpResponse: 8 Vector__XXX
 SG_ EPAS3P_xcpResponseData : 7|64@0+ (1,0) [0|0] "" Vector__XXX

BO_ 1808 VCBATT0_logging0Point1Hz: 8 Vector__XXX
 SG_ VCBATT0_nmWakeUpReasonDBG : 0|6@1+ (1,0) [0|0] "" Vector__XXX

BO_ 1809 VCBATT0_CPULoad: 8 Vector__XXX
 SG_ VCBATT0_CPULoadTotal : 0|8@1+ (1,0) [0|0] "" Vector__XXX
 SG_ VCBATT0_CPULoad1msTask : 8|8@1+ (1,0) [0|0] "" Vector__XXX
 SG_ VCBATT0_CPULoad10msTask : 16|8@1+ (1,0) [0|0] "" Vector__XXX
 SG_ VCBATT0_CPULoad100msTask : 24|8@1+ (1,0) [0|0] "" Vector__XXX
 SG_ VCBATT0_CPULoad1000msTask : 32|8@1+ (1,0) [0|0] "" Vector__XXX

BO_ 1840 UDS_epas3pRequestPARTY: 8 Vector__XXX
 SG_ UDS_epas3pRequestDataPARTY : 7|64@0+ (1,0) [0|0] "" Vector__XXX

BO_ 1848 EPAS3P_udsResponse: 8 Vector__XXX
 SG_ EPAS3P_udsResponseData : 7|64@0+ (1,0) [0|0] "" Vector__XXX

BO_ 1861 DI_chassisControl2: 8 Vector__XXX
 SG_ DI_gradeAngle : 0|6@1- (0.01,0) [0|0] "" Vector__XXX
 SG_ DI_bankAngle : 6|6@1- (0.01,0) [0|0] "" Vector__XXX
 SG_ DI_chassisControlVideoRequest : 12|4@1+ (1,0) [0|0] "" Vector__XXX
 SG_ DI_tireUtilizationRatioFrL : 17|5@1+ (0.0625,0) [0|0] "" Vector__XXX
 SG_ DI_tireUtilizationRatioFrR : 22|5@1+ (0.0625,0) [0|0] "" Vector__XXX
 SG_ DI_tireUtilizationRatioReL : 27|5@1+ (0.0625,0) [0|0] "" Vector__XXX
 SG_ DI_tireUtilizationRatioReR : 32|5@1+ (0.0625,0) [0|0] "" Vector__XXX
 SG_ DI_counterSteerTarget : 37|2@1+ (1,0) [0|0] "" Vector__XXX
 SG_ DI_splitMuProbability : 39|2@1+ (0.334,0) [0|0] "" Vector__XXX
 SG_ DI_mzError : 41|2@1+ (1667,0) [0|0] "" Vector__XXX
 SG_ DI_slipDifferenceFrontRear : 43|3@1- (0.133,0) [0|0] "" Vector__XXX
 SG_ DI_highFreqYawRate : 46|2@1+ (0.334,0) [0|0] "" Vector__XXX
 SG_ DI_turnDirection : 48|1@1+ (1,0) [0|0] "" Vector__XXX
 SG_ DI_absolutePreControlRequest : 49|2@1+ (5000,0) [0|0] "" Vector__XXX
 SG_ DI_oppositeBuildDirFrontAxle : 51|1@1+ (1,0) [0|0] "" Vector__XXX
 SG_ DI_oppositeBuildDirRearAxle : 52|1@1+ (1,0) [0|0] "" Vector__XXX
 SG_ DI_saturatedEffectiveness : 53|1@1+ (1,0) [0|0] "" Vector__XXX
 SG_ DI_driverPanicIndex : 54|2@1+ (0.334,0) [0|0] "" Vector__XXX
 SG_ DI_learnDownMu : 56|2@1+ (0.334,0) [0|0] "" Vector__XXX
 SG_ DI_preControlOpposingTurnDir : 58|1@1+ (1,0) [0|0] "" Vector__XXX
 SG_ DI_driverFxError : 59|2@1+ (1000,0) [0|0] "" Vector__XXX
 SG_ DI_targetSaturation : 61|3@1+ (0.572,0) [0|0] "" Vector__XXX

BO_ 1869 DI_chassisControl3: 8 Vector__XXX
 SG_ DI_tireWearFactor_FrL : 0|6@1+ (0.00125,0.96) [0|0] "" Vector__XXX
 SG_ DI_tireWearFactor_FrR : 6|6@1+ (0.00125,0.96) [0|0] "" Vector__XXX
 SG_ DI_tireWearFactor_ReL : 12|6@1+ (0.00125,0.96) [0|0] "" Vector__XXX
 SG_ DI_tireWearFactor_ReR : 18|6@1+ (0.00125,0.96) [0|0] "" Vector__XXX
 SG_ DI_kTireEstReUnSat : 24|7@1+ (0.001,0.008) [0|0] "" Vector__XXX
 SG_ DI_tireConfigSaved : 31|1@1+ (1,0) [0|0] "" Vector__XXX
 SG_ DI_distanceSinceLastTireConfig : 32|6@1+ (500,0) [0|0] "" Vector__XXX
 SG_ DI_hydroplaningRisk : 38|2@1+ (0.3333333333333333,0) [0|0] "" Vector__XXX
 SG_ DI_hydroplaningPuddlesWet : 40|4@1+ (1,0) [0|0] "" Vector__XXX
 SG_ DI_hydroplaningPuddlesDry : 44|3@1+ (1,0) [0|0] "" Vector__XXX
 SG_ DI_vehicleStuck : 47|1@1+ (1,0) [0|0] "" Vector__XXX
 SG_ DI_kTireEstRe : 48|5@1+ (0.001,0.03) [0|0] "" Vector__XXX
 SG_ DI_stickyMu : 53|6@1+ (0.025,0) [0|0] "" Vector__XXX
 SG_ DI_stickyMuConfidence : 59|5@1+ (0.1,0) [0|0] "" Vector__XXX

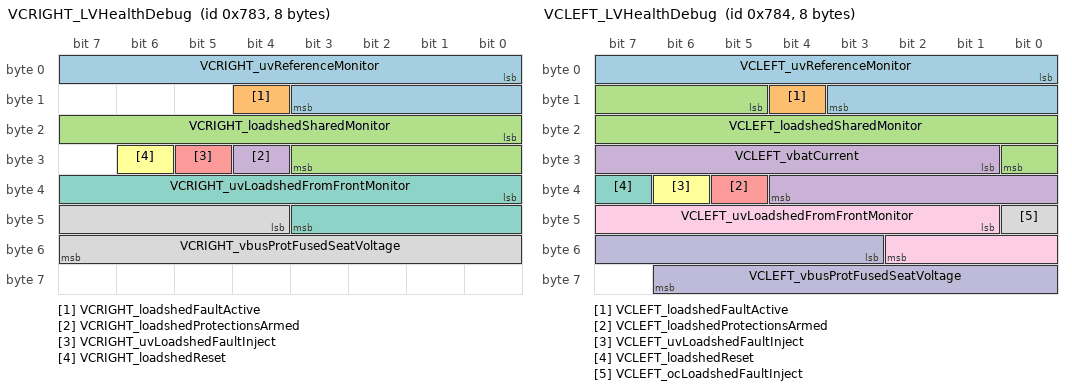
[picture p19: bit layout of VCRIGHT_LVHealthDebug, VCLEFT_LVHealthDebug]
BO_ 1923 VCRIGHT_LVHealthDebug: 8 Vector__XXX
 SG_ VCRIGHT_uvReferenceMonitor : 0|12@1+ (0.005443676098,0) [0|0] "" Vector__XXX
 SG_ VCRIGHT_loadshedFaultActive : 12|1@1+ (1,0) [0|0] "" Vector__XXX
 SG_ VCRIGHT_loadshedSharedMonitor : 16|12@1+ (0.005443676098,0) [0|0] "" Vector__XXX
 SG_ VCRIGHT_loadshedProtectionsArmed : 28|1@1+ (1,0) [0|0] "" Vector__XXX
 SG_ VCRIGHT_uvLoadshedFaultInject : 29|1@1+ (1,0) [0|0] "" Vector__XXX
 SG_ VCRIGHT_loadshedReset : 30|1@1+ (1,0) [0|0] "" Vector__XXX
 SG_ VCRIGHT_uvLoadshedFromFrontMonitor : 32|12@1+ (0.005443676098,0) [0|0] "" Vector__XXX
 SG_ VCRIGHT_vbusProtFusedSeatVoltage : 44|12@1+ (0.005443676098,0) [0|0] "" Vector__XXX

BO_ 1924 VCLEFT_LVHealthDebug: 8 Vector__XXX
 SG_ VCLEFT_uvReferenceMonitor : 0|12@1+ (0.005443676098,0) [0|0] "" Vector__XXX
 SG_ VCLEFT_loadshedFaultActive : 12|1@1+ (1,0) [0|0] "" Vector__XXX
 SG_ VCLEFT_loadshedSharedMonitor : 13|12@1+ (0.005443676098,0) [0|0] "" Vector__XXX
 SG_ VCLEFT_vbatCurrent : 25|12@1- (0.1,0) [0|0] "" Vector__XXX
 SG_ VCLEFT_loadshedProtectionsArmed : 37|1@1+ (1,0) [0|0] "" Vector__XXX
 SG_ VCLEFT_uvLoadshedFaultInject : 38|1@1+ (1,0) [0|0] "" Vector__XXX
 SG_ VCLEFT_loadshedReset : 39|1@1+ (1,0) [0|0] "" Vector__XXX
 SG_ VCLEFT_ocLoadshedFaultInject : 40|1@1+ (1,0) [0|0] "" Vector__XXX
 SG_ VCLEFT_uvLoadshedFromFrontMonitor : 41|10@1+ (0.017595307917888565,0) [0|0] "" Vector__XXX
 SG_ VCLEFT_vbusProtFusedSeatVoltage : 51|12@1+ (0.005443676098,0) [0|0] "" Vector__XXX

BO_ 1973 PM_itpmsDisplay: 8 Vector__XXX
 SG_ PM_itpmsDisplaySelector M : 0|2@1+ (1,0) [0|0] "" Vector__XXX
 SG_ PM_fusedPressureEstimateFrL m2 : 2|9@1+ (0.008,0) [0|0] "" Vector__XXX
 SG_ PM_fusedPressureEstimateReL m3 : 2|9@1+ (0.008,0) [0|0] "" Vector__XXX
 SG_ PM_indirectTPMSTellTale m0 : 2|2@1+ (1,0) [0|0] "" Vector__XXX
 SG_ PM_indirectTPMSDisplayState m0 : 4|2@1+ (1,0) [0|0] "" Vector__XXX
 SG_ PM_indirectTPMSDisplayProgress m0 : 8|5@1+ (0.05,0) [0|0] "" Vector__XXX
 SG_ PM_indirectTPMSRecommendedColdPressureFront m1 : 8|8@1+ (0.025,0) [0|0] "" Vector__XXX
 SG_ PM_fusedPressureEstimateFrR m2 : 11|9@1+ (0.008,0) [0|0] "" Vector__XXX
 SG_ PM_fusedPressureEstimateReR m3 : 11|9@1+ (0.008,0) [0|0] "" Vector__XXX
 SG_ PM_indirectTPMSDisplayWarningIndicatorFL m0 : 13|2@1+ (1,0) [0|0] "" Vector__XXX
 SG_ PM_indirectTPMSDisplayWarningIndicatorFR m0 : 16|2@1+ (1,0) [0|0] "" Vector__XXX
 SG_ PM_indirectTPMSRecommendedColdPressureRear m1 : 16|8@1+ (0.025,0) [0|0] "" Vector__XXX
 SG_ PM_indirectTPMSDisplayWarningIndicatorRL m0 : 18|2@1+ (1,0) [0|0] "" Vector__XXX
 SG_ PM_indirectTPMSDisplayWarningIndicatorRR m0 : 20|2@1+ (1,0) [0|0] "" Vector__XXX

BO_ 1974 PM_itpmsData: 8 Vector__XXX
 SG_ PM_itpmsDataSelector M : 0|3@1+ (1,0) [0|0] "" Vector__XXX
 SG_ PM_gnssAbsRadiusConvergenceConditions m5 : 3|3@1+ (1,0) [0|0] "" Vector__XXX
 SG_ PM_gnssAbsRadiusCovariance m4 : 3|10@1+ (1e-07,0) [0|0] "" Vector__XXX
 SG_ PM_itpmsState m0 : 3|3@1+ (1,0) [0|0] "" Vector__XXX
 SG_ PM_wheelSpeedFactorCurrentFrL m3 : 3|9@1+ (0.00012,0.97) [0|0] "" Vector__XXX
 SG_ PM_wheelSpeedFactorReferenceFrL m2 : 3|9@1+ (0.00012,0.97) [0|0] "" Vector__XXX
 SG_ PM_estimatedPressureLossGNSSFrL m1 : 8|7@1+ (0.025,0) [0|0] "" Vector__XXX
 SG_ PM_gnssAbsRadiusCurrentFrL m5 : 8|11@1+ (6.5e-05,0.32) [0|0] "" Vector__XXX
 SG_ PM_itpmsStateRelative m0 : 8|3@1+ (1,0) [0|0] "" Vector__XXX
 SG_ PM_itpmsStateGNSS m0 : 11|3@1+ (1,0) [0|0] "" Vector__XXX
 SG_ PM_wheelSpeedFactorCurrentFrR m3 : 12|9@1+ (0.00012,0.97) [0|0] "" Vector__XXX
 SG_ PM_wheelSpeedFactorReferenceFrR m2 : 12|9@1+ (0.00012,0.97) [0|0] "" Vector__XXX
 SG_ PM_gnssAbsRadiusReferenceFrL m4 : 13|11@1+ (6.5e-05,0.32) [0|0] "" Vector__XXX
 SG_ PM_itpmsStateNominalPressure m0 : 14|2@1+ (1,0) [0|0] "" Vector__XXX
 SG_ PM_estimatedPressureLossGNSSFrR m1 : 15|7@1+ (0.025,0) [0|0] "" Vector__XXX
 SG_ PM_itpmsCalibrationConfidenceRelative m0 : 16|6@1+ (0.02,0) [0|0] "" Vector__XXX
 SG_ PM_gnssAbsRadiusCurrentFrR m5 : 19|11@1+ (6.5e-05,0.32) [0|0] "" Vector__XXX
 SG_ PM_wheelSpeedFactorCurrentReL m3 : 21|9@1+ (0.00012,0.97) [0|0] "" Vector__XXX
 SG_ PM_wheelSpeedFactorReferenceReL m2 : 21|9@1+ (0.00012,0.97) [0|0] "" Vector__XXX
 SG_ PM_estimatedPressureLossGNSSReL m1 : 22|7@1+ (0.025,0) [0|0] "" Vector__XXX
 SG_ PM_gnssAbsRadiusReferenceFrR m4 : 24|11@1+ (6.5e-05,0.32) [0|0] "" Vector__XXX
 SG_ PM_itpmsCalibrationConfidenceGNSS m0 : 24|6@1+ (0.02,0) [0|0] "" Vector__XXX
 SG_ PM_estimatedPressureLossGNSSReR m1 : 29|7@1+ (0.025,0) [0|0] "" Vector__XXX
 SG_ PM_wheelSpeedFactorCurrentReR m3 : 30|9@1+ (0.00012,0.97) [0|0] "" Vector__XXX
 SG_ PM_wheelSpeedFactorReferenceReR m2 : 30|9@1+ (0.00012,0.97) [0|0] "" Vector__XXX
 SG_ PM_gnssAbsRadiusCurrentReL m5 : 32|11@1+ (6.5e-05,0.32) [0|0] "" Vector__XXX
 SG_ PM_permeabilityDeflationInitDay m0 : 32|16@1+ (1,0) [0|0] "" Vector__XXX
 SG_ PM_gnssAbsRadiusReferenceReL m4 : 35|11@1+ (6.5e-05,0.32) [0|0] "" Vector__XXX
 SG_ PM_estimatedPressureLossRelativeFrL m1 : 36|7@1+ (0.025,0) [0|0] "" Vector__XXX
 SG_ PM_estimatedPressureLossRelativeFrR m1 : 43|7@1+ (0.025,0) [0|0] "" Vector__XXX
 SG_ PM_gnssAbsRadiusCurrentReR m5 : 43|11@1+ (6.5e-05,0.32) [0|0] "" Vector__XXX
 SG_ PM_gnssAbsRadiusReferenceReR m4 : 48|11@1+ (6.5e-05,0.32) [0|0] "" Vector__XXX
 SG_ PM_permeabilityNominalPressureEstimate m0 : 48|8@1+ (0.015,0) [0|0] "" Vector__XXX
 SG_ PM_estimatedPressureLossRelativeReL m1 : 50|7@1+ (0.025,0) [0|0] "" Vector__XXX
 SG_ PM_estimatedPressureLossRelativeReR m1 : 57|7@1+ (0.025,0) [0|0] "" Vector__XXX

BO_ 1975 PM_looseBoltDetection: 8 Vector__XXX
 SG_ PM_latLinkLooseBoltDetectionState : 0|3@1+ (1,0) [0|0] "" Vector__XXX

BO_ 1976 PM_looseBoltDetectionDebug: 8 Vector__XXX
 SG_ PM_lbdDebugSelector M : 0|3@1+ (1,0) [0|0] "" Vector__XXX
 SG_ PM_lbdBMat0 m0 : 3|30@1- (0.0001,0) [0|0] "" Vector__XXX
 SG_ PM_lbdBMat1 m1 : 3|30@1- (2e-11,0) [0|0] "" Vector__XXX
 SG_ PM_lbdLogisticRegressionFlagStreak m3 : 8|16@1+ (1,0) [0|0] "" Vector__XXX
 SG_ PM_lbdMLPRawConfidence m4 : 8|16@1- (0.002,0) [0|0] "" Vector__XXX
 SG_ PM_lbdOdomLastUpdateKm m2 : 8|16@1+ (5,0) [0|0] "" Vector__XXX
 SG_ PM_lbdHiddenLayer0 m4 : 24|32@1- (0.0001,0) [0|0] "" Vector__XXX
 SG_ PM_lbdTotalRegressionSamples m2 : 24|16@1+ (1,0) [0|0] "" Vector__XXX
 SG_ PM_lbdUpdatesSinceLowTP m3 : 24|16@1+ (1,0) [0|0] "" Vector__XXX
 SG_ PM_lbdBMat2 m0 : 33|31@1- (1e-14,0) [0|0] "" Vector__XXX
 SG_ PM_lbdBMat3 m1 : 33|31@1- (1e-16,0) [0|0] "" Vector__XXX
 SG_ PM_lbdUpdatesSinceMLPFlag m3 : 40|16@1+ (1,0) [0|0] "" Vector__XXX
 SG_ PM_lbdLogisticRegressionConfidence m4 : 56|6@1+ (0.02,0) [0|0] "" Vector__XXX
 SG_ PM_lbdAlertSet m4 : 62|2@1+ (1,0) [0|0] "" Vector__XXX

BO_ 2015 UDS_functionalRequest: 8 Vector__XXX
 SG_ UDS_functionalRequestData_0 : 7|8@0+ (1,0) [0|0] "" Vector__XXX
 SG_ UDS_functionalRequestData_1 : 15|8@0+ (1,0) [0|0] "" Vector__XXX
 SG_ UDS_functionalRequestData_2 : 23|8@0+ (1,0) [0|0] "" Vector__XXX
 SG_ UDS_functionalRequestData_3 : 31|8@0+ (1,0) [0|0] "" Vector__XXX
 SG_ UDS_functionalRequestData_4 : 39|8@0+ (1,0) [0|0] "" Vector__XXX
 SG_ UDS_functionalRequestData_5 : 47|8@0+ (1,0) [0|0] "" Vector__XXX
 SG_ UDS_functionalRequestData_6 : 55|8@0+ (1,0) [0|0] "" Vector__XXX
 SG_ UDS_functionalRequestData_7 : 63|8@0+ (1,0) [0|0] "" Vector__XXX

BO_ 2031 DBG_testMessage: 8 Vector__XXX
 SG_ DBG_testID : 0|16@1+ (1,0) [0|0] "" Vector__XXX

BO_ 2038 PM_vdcDebug: 8 Vector__XXX
 SG_ PM_vdcDebugSelector M : 0|6@1+ (1,0) [0|0] "" Vector__XXX
 SG_ PM_VDCA_brakeForceRequest_FrL m0 : 6|9@1- (20,-4940) [0|0] "" Vector__XXX
 SG_ PM_VDCA_brakeForceRequest_FrR m1 : 6|9@1- (20,-4940) [0|0] "" Vector__XXX
 SG_ PM_VDCA_brakeForceRequest_ReL m2 : 6|9@1- (20,-4940) [0|0] "" Vector__XXX
 SG_ PM_VDCA_brakeForceRequest_ReR m3 : 6|9@1- (20,-4940) [0|0] "" Vector__XXX
 SG_ PM_VDCR_dMzRequestPreControl m32 : 6|10@1- (60,720) [0|0] "" Vector__XXX
 SG_ PM_VDCT_observerDirWillChange m24 : 6|1@1+ (1,0) [0|0] "" Vector__XXX
 SG_ PM_VDCT_turnDirection m22 : 6|2@1- (1,0) [0|0] "" Vector__XXX
 SG_ PM_VDCT_yrTarOSTurnOutMod m26 : 6|9@1- (0.006,0.234) [0|0] "" Vector__XXX
 SG_ PM_VE_corrPathWheelVelocityInTolerance_FrL m11 : 6|1@1+ (1,0) [0|0] "" Vector__XXX
 SG_ PM_VE_corrPathWheelVelocityInTolerance_ReL m12 : 6|1@1+ (1,0) [0|0] "" Vector__XXX
 SG_ PM_VSE_dMzLimitMax_allActuators m23 : 6|11@1- (30,720) [0|0] "" Vector__XXX
 SG_ PM_VSE_muVehicleDecLeakRate m29 : 6|5@1+ (0.05,0) [0|0] "" Vector__XXX
 SG_ PM_VDCT_obvserverYawRatePredict m24 : 7|9@1- (0.006,0.234) [0|0] "" Vector__XXX
 SG_ PM_VE_corrPathABSActiveNoSlip_FrL m11 : 7|1@1+ (1,0) [0|0] "" Vector__XXX
 SG_ PM_VE_corrPathABSActiveNoSlip_ReL m12 : 7|1@1+ (1,0) [0|0] "" Vector__XXX
 SG_ PM_TC_initThreshold_FrL m14 : 8|6@1+ (0.1875,0) [0|0] "" Vector__XXX
 SG_ PM_TC_initThreshold_FrR m15 : 8|6@1+ (0.1875,0) [0|0] "" Vector__XXX
 SG_ PM_TC_initThreshold_ReL m16 : 8|6@1+ (0.1875,0) [0|0] "" Vector__XXX
 SG_ PM_TC_initThreshold_ReR m17 : 8|6@1+ (0.1875,0) [0|0] "" Vector__XXX
 SG_ PM_TC_limit_Fr_Rwd m10 : 8|7@1- (56,-2464) [0|0] "" Vector__XXX
 SG_ PM_TC_slipErrorFiltered_Fr_Fwd m18 : 8|6@1- (0.25,0) [0|0] "" Vector__XXX
 SG_ PM_TC_slipErrorFiltered_ReL_Fwd m20 : 8|6@1- (0.25,0) [0|0] "" Vector__XXX
 SG_ PM_TC_slipErrorFiltered_ReR_Fwd m21 : 8|6@1- (0.25,0) [0|0] "" Vector__XXX
 SG_ PM_TC_slipErrorFiltered_Re_Fwd m19 : 8|6@1- (0.25,0) [0|0] "" Vector__XXX
 SG_ PM_VDCA_TCSlipTargetMod_FA_Fwd m4 : 8|6@1- (0.1,0) [0|0] "" Vector__XXX
 SG_ PM_VDCA_TCSlipTargetMod_RA_Fwd m5 : 8|6@1- (0.1,0) [0|0] "" Vector__XXX
 SG_ PM_VDCA_motorTorqueLimit_Fr m6 : 8|8@1- (50,3600) [0|0] "" Vector__XXX
 SG_ PM_VDCA_motorTorqueLimit_Re m7 : 8|8@1- (50,3600) [0|0] "" Vector__XXX
 SG_ PM_VDCA_motorTorqueLimit_ReL m8 : 8|8@1- (50,3600) [0|0] "" Vector__XXX
 SG_ PM_VDCA_motorTorqueLimit_ReR m9 : 8|8@1- (50,3600) [0|0] "" Vector__XXX
 SG_ PM_VDCR_dMzRequest m25 : 8|11@1- (30,720) [0|0] "" Vector__XXX
 SG_ PM_VDCT_ALOSAuthorityIndicator m27 : 8|5@1+ (0.0325,0) [0|0] "" Vector__XXX
 SG_ PM_VDCT_ALOSAuthorityThreshMult m28 : 8|4@1+ (0.1,1) [0|0] "" Vector__XXX
 SG_ PM_VDCT_osInitThreshBase m22 : 8|8@1- (0.006,0.366) [0|0] "" Vector__XXX
 SG_ PM_VE_corrPathABSInactWheelNotInSlip_FrL m11 : 8|1@1+ (1,0) [0|0] "" Vector__XXX
 SG_ PM_VE_corrPathABSInactWheelNotInSlip_ReL m12 : 8|1@1+ (1,0) [0|0] "" Vector__XXX
 SG_ PM_VE_fxmFres m13 : 8|8@1- (200,0) [0|0] "" Vector__XXX
 SG_ PM_VSE_stickyMu m30 : 8|6@1+ (0.025,0) [0|0] "" Vector__XXX
 SG_ PM_VSE_stickyMu_SurfaceUtil_contConf m31 : 8|4@1+ (0.07,0) [0|0] "" Vector__XXX
 SG_ PM_VE_corrPathABSInactWheelInSlip_FrL m11 : 9|1@1+ (1,0) [0|0] "" Vector__XXX
 SG_ PM_VE_corrPathABSInactWheelInSlip_ReL m12 : 9|1@1+ (1,0) [0|0] "" Vector__XXX
 SG_ PM_VE_corrPathABSInactZeroForceNoFlare_FrL m11 : 10|1@1+ (1,0) [0|0] "" Vector__XXX
 SG_ PM_VE_corrPathABSInactZeroForceNoFlare_ReL m12 : 10|1@1+ (1,0) [0|0] "" Vector__XXX
 SG_ PM_VE_corrPathFourWheelSlipZeroKValues_FrL m11 : 11|1@1+ (1,0) [0|0] "" Vector__XXX
 SG_ PM_VE_corrPathFourWheelSlipZeroKValues_ReL m12 : 11|1@1+ (1,0) [0|0] "" Vector__XXX
 SG_ PM_VSE_muVehicleLearnDown m29 : 11|5@1+ (0.05,0) [0|0] "" Vector__XXX
 SG_ PM_VDCT_ALUSAuthorityThreshMult m28 : 12|4@1+ (0.1,1) [0|0] "" Vector__XXX
 SG_ PM_VE_corrPathNotFourWheelSlipNormKValues_FrL m11 : 12|1@1+ (1,0) [0|0] "" Vector__XXX
 SG_ PM_VE_corrPathNotFourWheelSlipNormKValues_ReL m12 : 12|1@1+ (1,0) [0|0] "" Vector__XXX
 SG_ PM_VSE_stickyMu_SurfaceUtil_instConf m31 : 12|4@1+ (0.07,0) [0|0] "" Vector__XXX
 SG_ PM_VE_corrPathForceInfeasible_FrL m11 : 13|1@1+ (1,0) [0|0] "" Vector__XXX
 SG_ PM_VE_corrPathForceInfeasible_ReL m12 : 13|1@1+ (1,0) [0|0] "" Vector__XXX
 SG_ PM_VE_corrPathControlledBraking_FrL m11 : 14|1@1+ (1,0) [0|0] "" Vector__XXX
 SG_ PM_VE_corrPathControlledBraking_ReL m12 : 14|1@1+ (1,0) [0|0] "" Vector__XXX
 SG_ PM_TC_limit_Fr_Fwd m10 : 15|7@1- (63,3213) [0|0] "" Vector__XXX
 SG_ PM_VDCT_yawRateTarOversteer m26 : 15|9@1- (0.006,0.234) [0|0] "" Vector__XXX
 SG_ PM_VE_corrPathLowSpeedCorrection_FrL m11 : 15|1@1+ (1,0) [0|0] "" Vector__XXX
 SG_ PM_VE_corrPathLowSpeedCorrection_ReL m12 : 15|1@1+ (1,0) [0|0] "" Vector__XXX
 SG_ PM_TC_muFxDriverFF_FrL m14 : 16|6@1+ (0.025,0) [0|0] "" Vector__XXX
 SG_ PM_TC_muFxDriverFF_FrR m15 : 16|6@1+ (0.025,0) [0|0] "" Vector__XXX
 SG_ PM_TC_muFxDriverFF_ReL m16 : 16|6@1+ (0.025,0) [0|0] "" Vector__XXX
 SG_ PM_TC_muFxDriverFF_ReR m17 : 16|6@1+ (0.025,0) [0|0] "" Vector__XXX
 SG_ PM_TC_slipErrorFiltered_Fr_Rwd m18 : 16|6@1- (0.25,0) [0|0] "" Vector__XXX
 SG_ PM_TC_slipErrorFiltered_ReL_Rwd m20 : 16|6@1- (0.25,0) [0|0] "" Vector__XXX
 SG_ PM_TC_slipErrorFiltered_ReR_Rwd m21 : 16|6@1- (0.25,0) [0|0] "" Vector__XXX
 SG_ PM_TC_slipErrorFiltered_Re_Rwd m19 : 16|6@1- (0.25,0) [0|0] "" Vector__XXX
 SG_ PM_VDCA_TCSlipTargetMod_FA_Rwd m4 : 16|6@1- (0.1,0) [0|0] "" Vector__XXX
 SG_ PM_VDCA_TCSlipTargetMod_RA_Rwd m5 : 16|6@1- (0.1,0) [0|0] "" Vector__XXX
 SG_ PM_VDCA_motorTorqueLimMinReq_Fr m6 : 16|1@1+ (1,0) [0|0] "" Vector__XXX
 SG_ PM_VDCA_motorTorqueLimMinReq_Re m7 : 16|1@1+ (1,0) [0|0] "" Vector__XXX
 SG_ PM_VDCA_motorTorqueLimMinReq_ReL m8 : 16|1@1+ (1,0) [0|0] "" Vector__XXX
 SG_ PM_VDCA_motorTorqueLimMinReq_ReR m9 : 16|1@1+ (1,0) [0|0] "" Vector__XXX
 SG_ PM_VDCR_MotorRedistributionUP m28 : 16|8@1- (40,120) [0|0] "" Vector__XXX
 SG_ PM_VDCR_dMzRequestAyDmz m32 : 16|10@1- (60,720) [0|0] "" Vector__XXX
 SG_ PM_VDCR_isPreConOpposingTurnDir m24 : 16|1@1+ (1,0) [0|0] "" Vector__XXX
 SG_ PM_VDCT_osInitThreshHighFreqOff m22 : 16|8@1- (0.006,0.366) [0|0] "" Vector__XXX
 SG_ PM_VE_corrPathBTCCorrectionZeroK_FrL m11 : 16|1@1+ (1,0) [0|0] "" Vector__XXX
 SG_ PM_VE_corrPathBTCCorrectionZeroK_ReL m12 : 16|1@1+ (1,0) [0|0] "" Vector__XXX
 SG_ PM_VE_fxAccelMass m13 : 16|8@1- (0.16,0) [0|0] "" Vector__XXX
 SG_ PM_VSE_dMzSlipTargetLatDeg_Fwd m27 : 16|7@1- (240,480) [0|0] "" Vector__XXX
 SG_ PM_VSE_longActuatorEff_FrL m0 : 16|7@1- (0.05,0) [0|0] "" Vector__XXX
 SG_ PM_VSE_longActuatorEff_FrR m1 : 16|7@1- (0.05,0) [0|0] "" Vector__XXX
 SG_ PM_VSE_longActuatorEff_ReL m2 : 16|7@1- (0.05,0) [0|0] "" Vector__XXX
 SG_ PM_VSE_longActuatorEff_ReR m3 : 16|7@1- (0.05,0) [0|0] "" Vector__XXX
 SG_ PM_VSE_muVehicleDecFilter m29 : 16|5@1+ (0.05,0) [0|0] "" Vector__XXX
 SG_ PM_VSE_stickyMuTarget m30 : 16|6@1+ (0.025,0) [0|0] "" Vector__XXX
 SG_ PM_VSE_stickyMu_TC_contConf m31 : 16|4@1+ (0.07,0) [0|0] "" Vector__XXX
 SG_ PM_VDCA_motorTorqueLimMaxReq_Fr m6 : 17|1@1+ (1,0) [0|0] "" Vector__XXX
 SG_ PM_VDCA_motorTorqueLimMaxReq_Re m7 : 17|1@1+ (1,0) [0|0] "" Vector__XXX
 SG_ PM_VDCA_motorTorqueLimMaxReq_ReL m8 : 17|1@1+ (1,0) [0|0] "" Vector__XXX
 SG_ PM_VDCA_motorTorqueLimMaxReq_ReR m9 : 17|1@1+ (1,0) [0|0] "" Vector__XXX
 SG_ PM_VDCR_dMzRequestPreControlTotal m24 : 17|10@1- (60,720) [0|0] "" Vector__XXX
 SG_ PM_VE_corrPathBTCCorrectionSumOfAxleK_FrL m11 : 17|1@1+ (1,0) [0|0] "" Vector__XXX
 SG_ PM_VE_corrPathBTCCorrectionSumOfAxleK_ReL m12 : 17|1@1+ (1,0) [0|0] "" Vector__XXX
 SG_ PM_VSE_dMzLimitMin_allActuators m23 : 17|11@1- (30,720) [0|0] "" Vector__XXX
 SG_ PM_VDCA_torqueSplitModification_Fr m6 : 18|6@1+ (0.032,0) [0|0] "" Vector__XXX
 SG_ PM_VDCA_torqueSplitModification_Re m7 : 18|6@1+ (0.032,0) [0|0] "" Vector__XXX
 SG_ PM_VDCA_torqueSplitModification_ReL m8 : 18|6@1+ (0.032,0) [0|0] "" Vector__XXX
 SG_ PM_VDCA_torqueSplitModification_ReR m9 : 18|6@1+ (0.032,0) [0|0] "" Vector__XXX
 SG_ PM_VE_corrPathABSBrakingCorrection_FrL m11 : 18|1@1+ (1,0) [0|0] "" Vector__XXX
 SG_ PM_VE_corrPathABSBrakingCorrection_ReL m12 : 18|1@1+ (1,0) [0|0] "" Vector__XXX
 SG_ PM_VE_corrPathNonABSBrakingCorrection_FrL m11 : 19|1@1+ (1,0) [0|0] "" Vector__XXX
 SG_ PM_VE_corrPathNonABSBrakingCorrection_ReL m12 : 19|1@1+ (1,0) [0|0] "" Vector__XXX
 SG_ PM_VSE_dMzCurrent m25 : 19|11@1- (30,720) [0|0] "" Vector__XXX
 SG_ PM_VE_corrPathWheelVelocityInTolerance_FrR m11 : 20|1@1+ (1,0) [0|0] "" Vector__XXX
 SG_ PM_VE_corrPathWheelVelocityInTolerance_ReR m12 : 20|1@1+ (1,0) [0|0] "" Vector__XXX
 SG_ PM_VSE_stickyMu_TC_instConf m31 : 20|4@1+ (0.07,0) [0|0] "" Vector__XXX
 SG_ PM_VE_corrPathABSActiveNoSlip_FrR m11 : 21|1@1+ (1,0) [0|0] "" Vector__XXX
 SG_ PM_VE_corrPathABSActiveNoSlip_ReR m12 : 21|1@1+ (1,0) [0|0] "" Vector__XXX
 SG_ PM_VSE_muVehicleLatDecLeakRate m29 : 21|5@1+ (0.05,0) [0|0] "" Vector__XXX
 SG_ PM_TC_limit_Re_Rwd m10 : 22|7@1- (56,-2464) [0|0] "" Vector__XXX
 SG_ PM_VE_corrPathABSInactWheelNotInSlip_FrR m11 : 22|1@1+ (1,0) [0|0] "" Vector__XXX
 SG_ PM_VE_corrPathABSInactWheelNotInSlip_ReR m12 : 22|1@1+ (1,0) [0|0] "" Vector__XXX
 SG_ PM_VSE_forceY_FA m4 : 22|9@1- (40,240) [0|0] "" Vector__XXX
 SG_ PM_VSE_forceY_RA m5 : 22|9@1- (40,240) [0|0] "" Vector__XXX
 SG_ PM_VE_corrPathABSInactWheelInSlip_FrR m11 : 23|1@1+ (1,0) [0|0] "" Vector__XXX
 SG_ PM_VE_corrPathABSInactWheelInSlip_ReR m12 : 23|1@1+ (1,0) [0|0] "" Vector__XXX
 SG_ PM_TC_kiLatAndVelocity_Fr m18 : 24|6@1+ (25,0) [0|0] "" Vector__XXX
 SG_ PM_TC_kiLatAndVelocity_Re m19 : 24|6@1+ (25,0) [0|0] "" Vector__XXX
 SG_ PM_TC_kiLatAndVelocity_ReL m20 : 24|6@1+ (25,0) [0|0] "" Vector__XXX
 SG_ PM_TC_kiLatAndVelocity_ReR m21 : 24|6@1+ (25,0) [0|0] "" Vector__XXX
 SG_ PM_TC_preVdcSlipTarget_FrL m14 : 24|6@1+ (0.125,0) [0|0] "" Vector__XXX
 SG_ PM_TC_preVdcSlipTarget_FrR m15 : 24|6@1+ (0.125,0) [0|0] "" Vector__XXX
 SG_ PM_TC_preVdcSlipTarget_ReL m16 : 24|6@1+ (0.125,0) [0|0] "" Vector__XXX
 SG_ PM_TC_preVdcSlipTarget_ReR m17 : 24|6@1+ (0.125,0) [0|0] "" Vector__XXX
 SG_ PM_VDCA_torqueSplitOperatingPoint_Fr m6 : 24|6@1+ (0.016,0) [0|0] "" Vector__XXX
 SG_ PM_VDCA_torqueSplitOperatingPoint_Re m7 : 24|6@1+ (0.016,0) [0|0] "" Vector__XXX
 SG_ PM_VDCA_torqueSplitOperatingPoint_ReL m8 : 24|6@1+ (0.016,0) [0|0] "" Vector__XXX
 SG_ PM_VDCA_torqueSplitOperatingPoint_ReR m9 : 24|6@1+ (0.016,0) [0|0] "" Vector__XXX
 SG_ PM_VDCT_osInitThreshold m22 : 24|8@1- (0.006,0.366) [0|0] "" Vector__XXX
 SG_ PM_VDCT_yrTarUSFiltered m26 : 24|9@1- (0.006,0.234) [0|0] "" Vector__XXX
 SG_ PM_VE_corrPathABSInactZeroForceNoFlare_FrR m11 : 24|1@1+ (1,0) [0|0] "" Vector__XXX
 SG_ PM_VE_corrPathABSInactZeroForceNoFlare_ReR m12 : 24|1@1+ (1,0) [0|0] "" Vector__XXX
 SG_ PM_VE_vxDotGrade m13 : 24|8@1- (0.1,0.8) [0|0] "" Vector__XXX
 SG_ PM_VSE_dMzSlipTargetLatDeg_Rwd m27 : 24|7@1- (240,480) [0|0] "" Vector__XXX
 SG_ PM_VSE_fXCurrentBrakes_FrL m0 : 24|8@1- (40,-4880) [0|0] "" Vector__XXX
 SG_ PM_VSE_fXCurrentBrakes_FrR m1 : 24|8@1- (40,-4880) [0|0] "" Vector__XXX
 SG_ PM_VSE_fXCurrentBrakes_ReL m2 : 24|8@1- (40,-4880) [0|0] "" Vector__XXX
 SG_ PM_VSE_fXCurrentBrakes_ReR m3 : 24|8@1- (40,-4880) [0|0] "" Vector__XXX
 SG_ PM_VSE_stickyMuTotalConfidence m30 : 24|5@1+ (0.1,0) [0|0] "" Vector__XXX
 SG_ PM_VSE_stickyMu_VDC_contConf m31 : 24|4@1+ (0.07,0) [0|0] "" Vector__XXX
 SG_ PM_VSP_vdcState m28 : 24|2@1+ (1,0) [0|0] "" Vector__XXX
 SG_ PM_VE_corrPathFourWheelSlipZeroKValues_FrR m11 : 25|1@1+ (1,0) [0|0] "" Vector__XXX
 SG_ PM_VE_corrPathFourWheelSlipZeroKValues_ReR m12 : 25|1@1+ (1,0) [0|0] "" Vector__XXX
 SG_ PM_VDCR_dMzRequestRolloverDmz m32 : 26|10@1- (60,720) [0|0] "" Vector__XXX
 SG_ PM_VDCT_threshMultDriverSensorOS m28 : 26|4@1+ (0.1,1) [0|0] "" Vector__XXX
 SG_ PM_VE_corrPathNotFourWheelSlipNormKValues_FrR m11 : 26|1@1+ (1,0) [0|0] "" Vector__XXX
 SG_ PM_VE_corrPathNotFourWheelSlipNormKValues_ReR m12 : 26|1@1+ (1,0) [0|0] "" Vector__XXX
 SG_ PM_VSE_splitMuProbability m29 : 26|5@1+ (0.05,0) [0|0] "" Vector__XXX
 SG_ PM_VDCR_preConMuScaledActGain m24 : 27|5@1+ (0.05,0) [0|0] "" Vector__XXX
 SG_ PM_VE_corrPathForceInfeasible_FrR m11 : 27|1@1+ (1,0) [0|0] "" Vector__XXX
 SG_ PM_VE_corrPathForceInfeasible_ReR m12 : 27|1@1+ (1,0) [0|0] "" Vector__XXX
 SG_ PM_VE_corrPathControlledBraking_FrR m11 : 28|1@1+ (1,0) [0|0] "" Vector__XXX
 SG_ PM_VE_corrPathControlledBraking_ReR m12 : 28|1@1+ (1,0) [0|0] "" Vector__XXX
 SG_ PM_VSE_dMzLimitMax_powertrain m23 : 28|10@1- (30,360) [0|0] "" Vector__XXX
 SG_ PM_VSE_stickyMu_VDC_instConf m31 : 28|4@1+ (0.07,0) [0|0] "" Vector__XXX
 SG_ PM_TC_limit_Re_Fwd m10 : 29|7@1- (63,3213) [0|0] "" Vector__XXX
 SG_ PM_VE_corrPathLowSpeedCorrection_FrR m11 : 29|1@1+ (1,0) [0|0] "" Vector__XXX
 SG_ PM_VE_corrPathLowSpeedCorrection_ReR m12 : 29|1@1+ (1,0) [0|0] "" Vector__XXX
 SG_ PM_VE_corrPathBTCCorrectionZeroK_FrR m11 : 30|1@1+ (1,0) [0|0] "" Vector__XXX
 SG_ PM_VE_corrPathBTCCorrectionZeroK_ReR m12 : 30|1@1+ (1,0) [0|0] "" Vector__XXX
 SG_ PM_VSE_dMzDriver m25 : 30|9@1- (60,360) [0|0] "" Vector__XXX
 SG_ PM_VDCT_observerSlipAngle_FA m4 : 31|9@1- (0.005,0.03) [0|0] "" Vector__XXX
 SG_ PM_VDCT_observerSlipAngle_RA m5 : 31|9@1- (0.005,0.03) [0|0] "" Vector__XXX
 SG_ PM_VE_corrPathBTCCorrectionSumOfAxleK_FrR m11 : 31|1@1+ (1,0) [0|0] "" Vector__XXX
 SG_ PM_VE_corrPathBTCCorrectionSumOfAxleK_ReR m12 : 31|1@1+ (1,0) [0|0] "" Vector__XXX
 SG_ PM_VSE_splitMuTotalMz m29 : 31|9@1- (60,360) [0|0] "" Vector__XXX
 SG_ PM_MAST_torqueSplitPreVDC_Fr m6 : 32|6@1+ (0.016,0) [0|0] "" Vector__XXX
 SG_ PM_MAST_torqueSplitPreVDC_Re m7 : 32|6@1+ (0.016,0) [0|0] "" Vector__XXX
 SG_ PM_MAST_torqueSplitPreVDC_ReL m8 : 32|6@1+ (0.016,0) [0|0] "" Vector__XXX
 SG_ PM_MAST_torqueSplitPreVDC_ReR m9 : 32|6@1+ (0.016,0) [0|0] "" Vector__XXX
 SG_ PM_TC_kiTorque_Fr m18 : 32|6@1+ (25,0) [0|0] "" Vector__XXX
 SG_ PM_TC_kiTorque_Re m19 : 32|6@1+ (25,0) [0|0] "" Vector__XXX
 SG_ PM_TC_kiTorque_ReL m20 : 32|6@1+ (25,0) [0|0] "" Vector__XXX
 SG_ PM_TC_kiTorque_ReR m21 : 32|6@1+ (25,0) [0|0] "" Vector__XXX
 SG_ PM_TC_postVdcSlipTarget_FrL m14 : 32|6@1+ (0.125,0) [0|0] "" Vector__XXX
 SG_ PM_TC_postVdcSlipTarget_FrR m15 : 32|6@1+ (0.125,0) [0|0] "" Vector__XXX
 SG_ PM_TC_postVdcSlipTarget_ReL m16 : 32|6@1+ (0.125,0) [0|0] "" Vector__XXX
 SG_ PM_TC_postVdcSlipTarget_ReR m17 : 32|6@1+ (0.125,0) [0|0] "" Vector__XXX
 SG_ PM_VDCR_controlActive m28 : 32|3@1+ (1,0) [0|0] "" Vector__XXX
 SG_ PM_VDCR_decelControlAxRequest m24 : 32|8@1- (0.1,0.8) [0|0] "" Vector__XXX
 SG_ PM_VDCT_yrTarDriverSteadyState m22 : 32|9@1- (0.006,0.234) [0|0] "" Vector__XXX
 SG_ PM_VE_betaEst m13 : 32|8@1- (0.01,0) [0|0] "" Vector__XXX
 SG_ PM_VE_corrPathABSBrakingCorrection_FrR m11 : 32|1@1+ (1,0) [0|0] "" Vector__XXX
 SG_ PM_VE_corrPathABSBrakingCorrection_ReR m12 : 32|1@1+ (1,0) [0|0] "" Vector__XXX
 SG_ PM_VSE_dMzTorqueSplitLatDeg m27 : 32|8@1- (120,480) [0|0] "" Vector__XXX
 SG_ PM_VSE_fXDriverBrakeSat_FrL m0 : 32|8@1- (40,-4880) [0|0] "" Vector__XXX
 SG_ PM_VSE_fXDriverBrakeSat_FrR m1 : 32|8@1- (40,-4880) [0|0] "" Vector__XXX
 SG_ PM_VSE_fXDriverBrakeSat_ReL m2 : 32|8@1- (40,-4880) [0|0] "" Vector__XXX
 SG_ PM_VSE_fXDriverBrakeSat_ReR m3 : 32|8@1- (40,-4880) [0|0] "" Vector__XXX
 SG_ PM_VSE_stickyMu_SurfaceUtil_targetMu m30 : 32|6@1+ (0.025,0) [0|0] "" Vector__XXX
 SG_ PM_VSE_stickyMu_WheelSat_contConf m31 : 32|4@1+ (0.07,0) [0|0] "" Vector__XXX
 SG_ PM_VDCT_yrTarUSSurfaceSat m26 : 33|9@1- (0.006,0.234) [0|0] "" Vector__XXX
 SG_ PM_VE_corrPathNonABSBrakingCorrection_FrR m11 : 33|1@1+ (1,0) [0|0] "" Vector__XXX
 SG_ PM_VE_corrPathNonABSBrakingCorrection_ReR m12 : 33|1@1+ (1,0) [0|0] "" Vector__XXX
 SG_ PM_VE_vxDotFx m12 : 34|8@1- (0.16,0) [0|0] "" Vector__XXX
 SG_ PM_VE_wheelCorrectionGainFinal_FrL m11 : 34|4@1+ (0.4,0) [0|0] "" Vector__XXX
 SG_ PM_VDCT_threshMultDriverSensorUS m28 : 35|4@1+ (0.1,1) [0|0] "" Vector__XXX
 SG_ PM_TC_limit_ReL_Rwd m10 : 36|7@1- (56,-2464) [0|0] "" Vector__XXX
 SG_ PM_VDCT_observerLateralAccelPredict m32 : 36|10@1- (0.03,0) [0|0] "" Vector__XXX
 SG_ PM_VSE_stickyMu_WheelSat_instConf m31 : 36|4@1+ (0.07,0) [0|0] "" Vector__XXX
 SG_ PM_VSE_dMzLimitMin_powertrain m23 : 38|10@1- (30,360) [0|0] "" Vector__XXX
 SG_ PM_VDCR_osYawRateError m25 : 39|8@1- (0.006,0.018) [0|0] "" Vector__XXX
 SG_ PM_TC_ff_limit_Fr_Rwd m6 : 40|7@1- (63,-3969) [0|0] "" Vector__XXX
 SG_ PM_TC_ff_limit_ReL_Rwd m8 : 40|7@1- (63,-3969) [0|0] "" Vector__XXX
 SG_ PM_TC_ff_limit_ReR_Rwd m9 : 40|7@1- (63,-3969) [0|0] "" Vector__XXX
 SG_ PM_TC_ff_limit_Re_Rwd m7 : 40|7@1- (63,-3969) [0|0] "" Vector__XXX
 SG_ PM_TC_kiErrorError_Fr m18 : 40|6@1+ (25,0) [0|0] "" Vector__XXX
 SG_ PM_TC_kiErrorError_Re m19 : 40|6@1+ (25,0) [0|0] "" Vector__XXX
 SG_ PM_TC_kiErrorError_ReL m20 : 40|6@1+ (25,0) [0|0] "" Vector__XXX
 SG_ PM_TC_kiErrorError_ReR m21 : 40|6@1+ (25,0) [0|0] "" Vector__XXX
 SG_ PM_TC_slip_FrL m14 : 40|6@1+ (0.125,0) [0|0] "" Vector__XXX
 SG_ PM_TC_slip_FrR m15 : 40|6@1+ (0.125,0) [0|0] "" Vector__XXX
 SG_ PM_TC_slip_ReL m16 : 40|6@1+ (0.125,0) [0|0] "" Vector__XXX
 SG_ PM_TC_slip_ReR m17 : 40|6@1+ (0.125,0) [0|0] "" Vector__XXX
 SG_ PM_VDCR_decelControlStatus m24 : 40|2@1+ (1,0) [0|0] "" Vector__XXX
 SG_ PM_VDCR_dmzMotorRedistribution m27 : 40|8@1- (120,480) [0|0] "" Vector__XXX
 SG_ PM_VDCT_threshMultTargetSensor m28 : 40|4@1+ (0.1,1) [0|0] "" Vector__XXX
 SG_ PM_VE_wheelCorrectionGainFinal_FrR m11 : 40|4@1+ (0.4,0) [0|0] "" Vector__XXX
 SG_ PM_VSE_attitudeBankAngle m29 : 40|9@1- (0.005,0.03) [0|0] "" Vector__XXX
 SG_ PM_VSE_fXDriverBrakeUnSat_FrL m0 : 40|8@1- (40,-4880) [0|0] "" Vector__XXX
 SG_ PM_VSE_fXDriverBrakeUnSat_FrR m1 : 40|8@1- (40,-4880) [0|0] "" Vector__XXX
 SG_ PM_VSE_fXDriverBrakeUnSat_ReL m2 : 40|8@1- (40,-4880) [0|0] "" Vector__XXX
 SG_ PM_VSE_fXDriverBrakeUnSat_ReR m3 : 40|8@1- (40,-4880) [0|0] "" Vector__XXX
 SG_ PM_VSE_muVehicleFxHigh m13 : 40|5@1+ (0.05,0) [0|0] "" Vector__XXX
 SG_ PM_VSE_muVehicleFxLow m5 : 40|5@1+ (0.05,0) [0|0] "" Vector__XXX
 SG_ PM_VSE_stickyMu_TC_targetMu m30 : 40|6@1+ (0.025,0) [0|0] "" Vector__XXX
 SG_ PM_VSE_stickyMu_YawRateDiv_contConf m31 : 40|4@1+ (0.07,0) [0|0] "" Vector__XXX
 SG_ PM_VDCT_yrTarDriverPreSatDyn m22 : 41|9@1- (0.006,0.234) [0|0] "" Vector__XXX
 SG_ PM_VDCR_decelControlActGain m24 : 42|5@1+ (0.05,0) [0|0] "" Vector__XXX
 SG_ PM_VDCT_yawRateTarUndersteer m26 : 42|9@1- (0.006,0.234) [0|0] "" Vector__XXX
 SG_ PM_VE_vxDotAx m12 : 42|8@1- (0.16,0) [0|0] "" Vector__XXX
 SG_ PM_TC_limit_ReL_Fwd m10 : 43|7@1- (63,3213) [0|0] "" Vector__XXX
 SG_ PM_VE_wheelCorrectionGainFinal_ReL m11 : 44|4@1+ (0.4,0) [0|0] "" Vector__XXX
 SG_ PM_VSE_stickyMu_YawRateDiv_instConf m31 : 44|4@1+ (0.07,0) [0|0] "" Vector__XXX
 SG_ PM_TC_kiError_Fr m18 : 46|6@1+ (25,0) [0|0] "" Vector__XXX
 SG_ PM_TC_kiError_Re m19 : 46|6@1+ (25,0) [0|0] "" Vector__XXX
 SG_ PM_TC_kiError_ReL m20 : 46|6@1+ (25,0) [0|0] "" Vector__XXX
 SG_ PM_TC_kiError_ReR m21 : 46|6@1+ (25,0) [0|0] "" Vector__XXX
 SG_ PM_VDCR_lateralJerkFrom2HzFilteredLateralAccel m32 : 46|10@1- (0.2,0) [0|0] "" Vector__XXX
 SG_ PM_VSE_stickyMu_VDC_targetMu m30 : 46|6@1+ (0.025,0) [0|0] "" Vector__XXX
 SG_ PM_VDCR_usYawRateError m25 : 47|8@1- (0.006,0.018) [0|0] "" Vector__XXX
 SG_ PM_VDCT_decelControlInitThresh m24 : 47|8@1- (0.006,0.366) [0|0] "" Vector__XXX
 SG_ PM_TC_absMaxVehicleMz m15 : 48|8@1+ (100,0) [0|0] "" Vector__XXX
 SG_ PM_TC_absVehicleMotorMz m14 : 48|8@1+ (100,0) [0|0] "" Vector__XXX
 SG_ PM_TC_ff_limit_Fr_Fwd m6 : 48|7@1+ (63,0) [0|0] "" Vector__XXX
 SG_ PM_TC_ff_limit_ReL_Fwd m8 : 48|7@1+ (63,0) [0|0] "" Vector__XXX
 SG_ PM_TC_ff_limit_ReR_Fwd m9 : 48|7@1+ (63,0) [0|0] "" Vector__XXX
 SG_ PM_TC_ff_limit_Re_Fwd m7 : 48|7@1+ (63,0) [0|0] "" Vector__XXX
 SG_ PM_TC_nominalSlipBoostPerMotor m17 : 48|5@1+ (0.05,0) [0|0] "" Vector__XXX
 SG_ PM_VDCA_brakeForceHighLim_FrL m0 : 48|8@1- (40,-4880) [0|0] "" Vector__XXX
 SG_ PM_VDCA_brakeForceHighLim_FrR m1 : 48|8@1- (40,-4880) [0|0] "" Vector__XXX
 SG_ PM_VDCA_brakeForceHighLim_ReL m2 : 48|8@1- (40,-4880) [0|0] "" Vector__XXX
 SG_ PM_VDCA_brakeForceHighLim_ReR m3 : 48|8@1- (40,-4880) [0|0] "" Vector__XXX
 SG_ PM_VDCT_oversteerBaseThreshMult m27 : 48|4@1+ (0.1,1) [0|0] "" Vector__XXX
 SG_ PM_VDCT_usInitThreshBase m23 : 48|8@1- (0.006,0.366) [0|0] "" Vector__XXX
 SG_ PM_VE_wheelCorrectionGainFinal_ReR m11 : 48|4@1+ (0.4,0) [0|0] "" Vector__XXX
 SG_ PM_VSE_attitudeDBetaInControl m29 : 49|8@1- (0.01,0.03) [0|0] "" Vector__XXX
 SG_ PM_TC_limit_ReR_Rwd m10 : 50|7@1- (56,-2464) [0|0] "" Vector__XXX
 SG_ PM_VDCT_yrTarDriverSatDyn m22 : 50|9@1- (0.006,0.234) [0|0] "" Vector__XXX
 SG_ PM_VE_vxDot m12 : 50|8@1- (0.16,0) [0|0] "" Vector__XXX
 SG_ PM_VDCT_observerYawRateEstimate m26 : 51|9@1- (0.006,0.234) [0|0] "" Vector__XXX
 SG_ PM_TC_kiBase_Fr m18 : 52|6@1+ (25,0) [0|0] "" Vector__XXX
 SG_ PM_TC_kiBase_Re m19 : 52|6@1+ (25,0) [0|0] "" Vector__XXX
 SG_ PM_TC_kiBase_ReL m20 : 52|6@1+ (25,0) [0|0] "" Vector__XXX
 SG_ PM_TC_kiBase_ReR m21 : 52|6@1+ (25,0) [0|0] "" Vector__XXX
 SG_ PM_VDCT_yawRateTargetMotorAL m27 : 52|9@1- (0.006,0.234) [0|0] "" Vector__XXX
 SG_ PM_VSE_stickyMu_WheelSat_targetMu m30 : 52|6@1+ (0.025,0) [0|0] "" Vector__XXX
 SG_ PM_VDCT_maxSurfaceYawRate m24 : 55|9@1- (0.006,0.234) [0|0] "" Vector__XXX
 SG_ PM_VDCT_yrTarOSSaturated m25 : 55|9@1- (0.006,0.234) [0|0] "" Vector__XXX
 SG_ PM_TC_maxSlipBoost m17 : 56|5@1+ (0.05,0) [0|0] "" Vector__XXX
 SG_ PM_VDCA_brakeForceLowLim_FrL m0 : 56|8@1- (40,-4880) [0|0] "" Vector__XXX
 SG_ PM_VDCA_brakeForceLowLim_FrR m1 : 56|8@1- (40,-4880) [0|0] "" Vector__XXX
 SG_ PM_VDCA_brakeForceLowLim_ReL m2 : 56|8@1- (40,-4880) [0|0] "" Vector__XXX
 SG_ PM_VDCA_brakeForceLowLim_ReR m3 : 56|8@1- (40,-4880) [0|0] "" Vector__XXX
 SG_ PM_VDCT_usInitThreshold m23 : 56|8@1- (0.006,0.366) [0|0] "" Vector__XXX
 SG_ PM_TC_limit_ReR_Fwd m10 : 57|7@1- (63,3213) [0|0] "" Vector__XXX
 SG_ PM_VSE_roadWheelAngleAverage m29 : 57|7@1- (0.015,0.255) [0|0] "" Vector__XXX
 SG_ PM_TC_kp_Fr m18 : 58|6@1+ (2,0) [0|0] "" Vector__XXX
 SG_ PM_TC_kp_Re m19 : 58|6@1+ (2,0) [0|0] "" Vector__XXX
 SG_ PM_TC_kp_ReL m20 : 58|6@1+ (2,0) [0|0] "" Vector__XXX
 SG_ PM_TC_kp_ReR m21 : 58|6@1+ (2,0) [0|0] "" Vector__XXX
 SG_ PM_VE_wheelFlare_FrL m12 : 58|1@1+ (1,0) [0|0] "" Vector__XXX
 SG_ PM_VSE_stickyMu_YawRateDiv_targetMu m30 : 58|6@1+ (0.025,0) [0|0] "" Vector__XXX
 SG_ PM_VE_wheelFlare_FrR m12 : 59|1@1+ (1,0) [0|0] "" Vector__XXX
 SG_ PM_VDCT_threshMultDriverTarget m26 : 60|4@1+ (0.1,1) [0|0] "" Vector__XXX
 SG_ PM_VE_wheelFlare_ReL m12 : 60|1@1+ (1,0) [0|0] "" Vector__XXX
 SG_ PM_VE_wheelFlare_ReR m12 : 61|1@1+ (1,0) [0|0] "" Vector__XXX

BO_ 2047 GTW_carConfig: 8 Vector__XXX
 SG_ GTW_carConfigMultiplexer M : 0|8@1+ (1,0) [0|0] "" Vector__XXX
 SG_ GTW_birthday m4 : 8|32@1+ (1,0) [0|0] "" Vector__XXX
 SG_ GTW_deliveryStatus m1 : 8|1@1+ (1,0) [0|0] "" Vector__XXX
 SG_ GTW_exteriorTrimType m2 : 8|1@1+ (1,0) [0|0] "" Vector__XXX
 SG_ GTW_gloveboxUSBType m5 : 8|2@1+ (1,0) [0|0] "" Vector__XXX
 SG_ GTW_mapRegion m3 : 8|4@1+ (1,0) [0|0] "" Vector__XXX
 SG_ GTW_rcmUndersideAbuseZThreshold m9 : 8|3@1+ (1,0) [0|0] "" Vector__XXX
 SG_ GTW_fasciaType m7 : 9|4@1+ (1,0) [0|0] "" Vector__XXX
 SG_ GTW_frontSeatHeaters m2 : 9|1@1+ (1,0) [0|0] "" Vector__XXX
 SG_ GTW_wiperMotorType m6 : 9|1@1+ (1,0) [0|0] "" Vector__XXX
 SG_ GTW_cabinPTCHeaterType m1 : 10|1@1+ (1,0) [0|0] "" Vector__XXX
 SG_ GTW_coolantPumpType m5 : 10|3@1+ (1,0) [0|0] "" Vector__XXX
 SG_ GTW_frontOverheadConsoleType m6 : 10|2@1+ (1,0) [0|0] "" Vector__XXX
 SG_ GTW_rearSeatHeaters m2 : 10|1@1+ (1,0) [0|0] "" Vector__XXX
 SG_ GTW_sohRegulatoryStatus m8 : 10|1@1+ (1,0) [0|0] "" Vector__XXX
 SG_ GTW_rcmUndersideAbuseYThreshold m9 : 11|3@1+ (1,0) [0|0] "" Vector__XXX
 SG_ GTW_rightHandDrive m1 : 11|1@1+ (1,0) [0|0] "" Vector__XXX
 SG_ GTW_eCallAntennaHW m2 : 12|1@1+ (1,0) [0|0] "" Vector__XXX
 SG_ GTW_performancePackage m3 : 12|3@1+ (1,0) [0|0] "" Vector__XXX
 SG_ GTW_rearLightType m1 : 12|2@1+ (1,0) [0|0] "" Vector__XXX
 SG_ GTW_shifterType m6 : 12|1@1+ (1,0) [0|0] "" Vector__XXX
 SG_ GTW_compressorType m6 : 13|4@1+ (1,0) [0|0] "" Vector__XXX
 SG_ GTW_epblHwType m5 : 13|4@1+ (1,0) [0|0] "" Vector__XXX
 SG_ GTW_homelinkType m2 : 13|1@1+ (1,0) [0|0] "" Vector__XXX
 SG_ GTW_powerSteeringColumn m7 : 13|1@1+ (1,0) [0|0] "" Vector__XXX
 SG_ GTW_frontSeatHeaterType m7 : 14|1@1+ (1,0) [0|0] "" Vector__XXX
 SG_ GTW_headlamps m1 : 14|2@1+ (1,0) [0|0] "" Vector__XXX
 SG_ GTW_rcmUndersideAbuseWindow m9 : 14|2@1+ (1,0) [0|0] "" Vector__XXX
 SG_ GTW_vdcType m2 : 14|1@1+ (1,0) [0|0] "" Vector__XXX
 SG_ GTW_softPerformanceLimit m7 : 15|4@1+ (1,0) [0|0] "" Vector__XXX
 SG_ GTW_country m1 : 16|16@1+ (1,0) [0|0] "" Vector__XXX
 SG_ GTW_epbrHwType m5 : 17|4@1+ (1,0) [0|0] "" Vector__XXX
 SG_ GTW_m3yBusArchitecture m8 : 17|2@1+ (1,0) [0|0] "" Vector__XXX
 SG_ GTW_memoryMirrors m2 : 17|1@1+ (1,0) [0|0] "" Vector__XXX
 SG_ GTW_twelveVBatteryType m6 : 17|3@1+ (1,0) [0|0] "" Vector__XXX
 SG_ GTW_chassisType m3 : 18|4@1+ (1,0) [0|0] "" Vector__XXX
 SG_ GTW_powerLiftgateType m2 : 18|2@1+ (1,0) [0|0] "" Vector__XXX
 SG_ GTW_efuseSWConfig m6 : 20|3@1+ (1,0) [0|0] "" Vector__XXX
 SG_ GTW_lumbarECUType m2 : 20|4@1+ (1,0) [0|0] "" Vector__XXX
 SG_ GTW_blowerMotorType m5 : 21|2@1+ (1,0) [0|0] "" Vector__XXX
 SG_ GTW_interiorUpperTrimType m8 : 21|1@1+ (1,0) [0|0] "" Vector__XXX
 SG_ GTW_airSuspension m3 : 22|2@1+ (1,0) [0|0] "" Vector__XXX
 SG_ GTW_alcoholInterlockType m7 : 22|1@1+ (1,0) [0|0] "" Vector__XXX
 SG_ GTW_blindSpotIndicatorLightType m8 : 22|2@1+ (1,0) [0|0] "" Vector__XXX
 SG_ GTW_immersiveAudio m7 : 23|2@1+ (1,0) [0|0] "" Vector__XXX
 SG_ GTW_bleEndpointUpdateMethod m6 : 24|1@1+ (1,0) [0|0] "" Vector__XXX
 SG_ GTW_centerConsoleControllerType m3 : 24|2@1+ (1,0) [0|0] "" Vector__XXX
 SG_ GTW_powerMirrorFoldType m5 : 24|1@1+ (1,0) [0|0] "" Vector__XXX
 SG_ GTW_rearSeatHeaterType m2 : 24|2@1+ (1,0) [0|0] "" Vector__XXX
 SG_ GTW_wiperMotorAsicType m8 : 24|2@1+ (1,0) [0|0] "" Vector__XXX
 SG_ GTW_headlinerMaterialType m9 : 25|2@1+ (1,0) [0|0] "" Vector__XXX
 SG_ GTW_steeringWheelControllerType m6 : 25|3@1+ (1,0) [0|0] "" Vector__XXX
 SG_ GTW_autopilotCameraType m3 : 26|1@1+ (1,0) [0|0] "" Vector__XXX
 SG_ GTW_auxParkLamps m2 : 26|2@1+ (1,0) [0|0] "" Vector__XXX
 SG_ GTW_passengerOccupancySensorType m7 : 26|3@1+ (1,0) [0|0] "" Vector__XXX
 SG_ GTW_connectivityPackage m3 : 27|1@1+ (1,0) [0|0] "" Vector__XXX
 SG_ GTW_frontUsbHubType m5 : 27|3@1+ (1,0) [0|0] "" Vector__XXX
 SG_ GTW_glareShieldHeaterType m9 : 27|1@1+ (1,0) [0|0] "" Vector__XXX
 SG_ GTW_interiorCabinRadarType m2 : 28|1@1+ (1,0) [0|0] "" Vector__XXX
 SG_ GTW_plcSupportType m3 : 28|2@1+ (1,0) [0|0] "" Vector__XXX
 SG_ GTW_gloveboxActuatorType m6 : 29|2@1+ (1,0) [0|0] "" Vector__XXX
 SG_ GTW_hvacPanelVaneType m2 : 29|1@1+ (1,0) [0|0] "" Vector__XXX
 SG_ GTW_occupancyDetectionSourceRequest m8 : 29|1@1+ (1,0) [0|0] "" Vector__XXX
 SG_ GTW_badgingVersion m3 : 30|2@1+ (1,0) [0|0] "" Vector__XXX
 SG_ GTW_intakeAirFilterType m2 : 30|2@1+ (1,0) [0|0] "" Vector__XXX
 SG_ GTW_packPerformanceDeviation m7 : 30|3@1+ (1,0) [0|0] "" Vector__XXX
 SG_ GTW_superManifoldType m5 : 30|2@1+ (1,0) [0|0] "" Vector__XXX
 SG_ GTW_rduCableType m8 : 31|1@1+ (1,0) [0|0] "" Vector__XXX
 SG_ GTW_eBuckConfig m2 : 32|1@1+ (1,0) [0|0] "" Vector__XXX
 SG_ GTW_epasType m6 : 32|4@1+ (1,0) [0|0] "" Vector__XXX
 SG_ GTW_packEnergy m3 : 32|5@1+ (1,0) [0|0] "" Vector__XXX
 SG_ GTW_parkTelltaleBehaviorType m8 : 32|1@1+ (1,0) [0|0] "" Vector__XXX
 SG_ GTW_rcmLocation m5 : 32|1@1+ (1,0) [0|0] "" Vector__XXX
 SG_ GTW_tireType m1 : 32|6@1+ (1,0) [0|0] "" Vector__XXX
 SG_ GTW_autopilotExteriorCameraType m5 : 33|1@1+ (1,0) [0|0] "" Vector__XXX
 SG_ GTW_steeringHeaterEnabled m2 : 33|1@1+ (1,0) [0|0] "" Vector__XXX
 SG_ GTW_activeHighBeam m2 : 34|1@1+ (1,0) [0|0] "" Vector__XXX
 SG_ GTW_airbagCutoffSwitch m2 : 35|1@1+ (1,0) [0|0] "" Vector__XXX
 SG_ GTW_frontFogLamps m7 : 35|1@1+ (1,0) [0|0] "" Vector__XXX
 SG_ GTW_interiorCamBeautyCoverType m5 : 35|2@1+ (1,0) [0|0] "" Vector__XXX
 SG_ GTW_homologationRegionOverride m6 : 36|2@1+ (1,0) [0|0] "" Vector__XXX
 SG_ GTW_intrusionSensorType m2 : 36|1@1+ (1,0) [0|0] "" Vector__XXX
 SG_ GTW_audioType m7 : 37|3@1+ (1,0) [0|0] "" Vector__XXX
 SG_ GTW_frontSeatReclinerHardware m3 : 37|2@1+ (1,0) [0|0] "" Vector__XXX
 SG_ GTW_spoilerType m2 : 37|1@1+ (1,0) [0|0] "" Vector__XXX
 SG_ GTW_hornType m5 : 38|1@1+ (1,0) [0|0] "" Vector__XXX
 SG_ GTW_roofGlassType m1 : 38|2@1+ (1,0) [0|0] "" Vector__XXX
 SG_ GTW_windowCommandsPermissionType m6 : 38|2@1+ (1,0) [0|0] "" Vector__XXX
 SG_ GTW_brakeLineSwitchType m3 : 39|1@1+ (1,0) [0|0] "" Vector__XXX
 SG_ GTW_interiorCameraType m8 : 39|2@1+ (1,0) [0|0] "" Vector__XXX
 SG_ GTW_rearFogLamps m2 : 39|1@1+ (1,0) [0|0] "" Vector__XXX
 SG_ GTW_dasHw m1 : 40|3@1+ (1,0) [0|0] "" Vector__XXX
 SG_ GTW_eCallEnabled m4 : 40|2@1+ (1,0) [0|0] "" Vector__XXX
 SG_ GTW_espValveType m3 : 40|2@1+ (1,0) [0|0] "" Vector__XXX
 SG_ GTW_mRecordVersion m9 : 40|1@1+ (1,0) [0|0] "" Vector__XXX
 SG_ GTW_roofType m2 : 40|1@1+ (1,0) [0|0] "" Vector__XXX
 SG_ GTW_frontFasciaCameraType m8 : 41|2@1+ (1,0) [0|0] "" Vector__XXX
 SG_ GTW_thirdRowSeatType m2 : 41|1@1+ (1,0) [0|0] "" Vector__XXX
 SG_ GTW_autopilot m2 : 42|3@1+ (1,0) [0|0] "" Vector__XXX
 SG_ GTW_headlightStepperStallDetectMode m6 : 42|1@1+ (1,0) [0|0] "" Vector__XXX
 SG_ GTW_occupancyClassificationFeatureType m7 : 42|1@1+ (1,0) [0|0] "" Vector__XXX
 SG_ GTW_parkAssistECUType m4 : 42|2@1+ (1,0) [0|0] "" Vector__XXX
 SG_ GTW_softRange m3 : 42|3@1+ (1,0) [0|0] "" Vector__XXX
 SG_ GTW_steeringColumnMotorType m5 : 42|2@1+ (1,0) [0|0] "" Vector__XXX
 SG_ GTW_brakeHWType m1 : 43|5@1+ (1,0) [0|0] "" Vector__XXX
 SG_ GTW_rgbInteriorLightingEnabled m6 : 43|2@1+ (1,0) [0|0] "" Vector__XXX
 SG_ GTW_passengerAirbagType m4 : 44|2@1+ (1,0) [0|0] "" Vector__XXX
 SG_ GTW_interiorCamFanType m8 : 45|3@1+ (1,0) [0|0] "" Vector__XXX
 SG_ GTW_refrigerantType m3 : 45|2@1+ (1,0) [0|0] "" Vector__XXX
 SG_ GTW_superchargingAccess m2 : 45|2@1+ (1,0) [0|0] "" Vector__XXX
 SG_ GTW_windshieldWiperHeaterType m6 : 45|1@1+ (1,0) [0|0] "" Vector__XXX
 SG_ GTW_forwardRadarHw m4 : 46|2@1+ (1,0) [0|0] "" Vector__XXX
 SG_ GTW_frontControllerArchitectureType m7 : 46|1@1+ (1,0) [0|0] "" Vector__XXX
 SG_ GTW_driveInterfaceType m6 : 47|1@1+ (1,0) [0|0] "" Vector__XXX
 SG_ GTW_exteriorColor m2 : 48|5@1+ (1,0) [0|0] "" Vector__XXX
 SG_ GTW_frontSeatType m4 : 48|4@1+ (1,0) [0|0] "" Vector__XXX
 SG_ GTW_refrigACLineType m5 : 48|2@1+ (1,0) [0|0] "" Vector__XXX
 SG_ GTW_restraintsHardwareType m1 : 48|8@1+ (1,0) [0|0] "" Vector__XXX
 SG_ GTW_wheelType m3 : 48|7@1+ (1,0) [0|0] "" Vector__XXX
 SG_ GTW_efficiencyPackage m6 : 49|6@1+ (1,0) [0|0] "" Vector__XXX
 SG_ GTW_tpmsType m7 : 49|2@1+ (1,0) [0|0] "" Vector__XXX
 SG_ GTW_refrigFilterType m5 : 50|2@1+ (1,0) [0|0] "" Vector__XXX
 SG_ GTW_authenticationEndpointLayout m7 : 52|3@1+ (1,0) [0|0] "" Vector__XXX
 SG_ GTW_diBurnInType m5 : 52|1@1+ (1,0) [0|0] "" Vector__XXX
 SG_ GTW_pedestrianWarningSound m2 : 53|2@1+ (1,0) [0|0] "" Vector__XXX
 SG_ GTW_specialBadgingType m5 : 53|2@1+ (1,0) [0|0] "" Vector__XXX
 SG_ GTW_wirelessPhoneChargerType m4 : 53|2@1+ (1,0) [0|0] "" Vector__XXX
 SG_ GTW_chassisSubType m5 : 55|2@1+ (1,0) [0|0] "" Vector__XXX
 SG_ GTW_ethernetTunerType m4 : 55|2@1+ (1,0) [0|0] "" Vector__XXX
 SG_ GTW_steeringColumnUJointType m2 : 55|1@1+ (1,0) [0|0] "" Vector__XXX
 SG_ GTW_visorLightType m6 : 55|1@1+ (1,0) [0|0] "" Vector__XXX
 SG_ GTW_bPillarNFCParam m2 : 56|1@1+ (1,0) [0|0] "" Vector__XXX
 SG_ GTW_drivetrainType m1 : 56|4@1+ (1,0) [0|0] "" Vector__XXX
 SG_ GTW_brakeActuationType m3 : 57|3@1+ (1,0) [0|0] "" Vector__XXX
 SG_ GTW_frontSeatVentilationType m5 : 57|1@1+ (1,0) [0|0] "" Vector__XXX
 SG_ GTW_interiorLighting m2 : 57|3@1+ (1,0) [0|0] "" Vector__XXX
 SG_ GTW_socSleepOverride m7 : 57|2@1+ (1,0) [0|0] "" Vector__XXX
 SG_ GTW_gnssAntennaType m6 : 58|2@1+ (1,0) [0|0] "" Vector__XXX
 SG_ GTW_towPackage m5 : 58|2@1+ (1,0) [0|0] "" Vector__XXX
 SG_ GTW_r79BehaviorOverride m7 : 59|1@1+ (1,0) [0|0] "" Vector__XXX
 SG_ GTW_headlightLevelerType m2 : 60|2@1+ (1,0) [0|0] "" Vector__XXX
 SG_ GTW_interiorTrimType m4 : 60|4@1+ (1,0) [0|0] "" Vector__XXX
 SG_ GTW_radarHeaterType m1 : 60|3@1+ (1,0) [0|0] "" Vector__XXX
 SG_ GTW_repeaterAeroRibType m8 : 60|3@1+ (1,0) [0|0] "" Vector__XXX
 SG_ GTW_secondRowSeatType m3 : 60|3@1+ (1,0) [0|0] "" Vector__XXX
 SG_ GTW_steeringHeaterType m7 : 60|3@1+ (1,0) [0|0] "" Vector__XXX
 SG_ GTW_restraintControlsType m5 : 61|1@1+ (1,0) [0|0] "" Vector__XXX
 SG_ GTW_caliperColorType m5 : 62|2@1+ (1,0) [0|0] "" Vector__XXX
 SG_ GTW_frontSeatHeatersEnabled m6 : 62|1@1+ (1,0) [0|0] "" Vector__XXX
 SG_ GTW_numberHVILNodes m2 : 62|2@1+ (1,0) [0|0] "" Vector__XXX
 SG_ GTW_narrowWipingSupported m7 : 63|1@1+ (1,0) [0|0] "" Vector__XXX
 SG_ GTW_windshieldWiperHeaterEnabled m6 : 63|1@1+ (1,0) [0|0] "" Vector__XXX
